VERSION ""

NS_ :

BS_:

BU_: APIM_CISM FCIMB RACM_RCIM DSP WCM DACMC HUD_ADV TRM_ITRM ACM GWM _delete APIM IPC GENERIC TSTR

BO_ 643 GWM_Send_Signals_18_HS3: 8 GWM
 SG_ StrtInGearMsgTxt_D_Rq_UB : 48|1@0+ (1,0) [0|1] "SED"  IPC
 SG_ StrtInGearMsgTxt_D_Rq : 59|4@0+ (1,0) [0|15] "SED"  IPC
 SG_ StabBarCnnct_D_Stat_UB : 49|1@0+ (1,0) [0|1] "SED"  APIM_CISM,APIM
 SG_ StabBarCnnct_D_Stat : 63|4@0+ (1,0) [0|15] "SED"  APIM_CISM,APIM
 SG_ FstChrgCmplt_T_Est : 33|10@0+ (1,0) [0|1023] "minute"  APIM_CISM,APIM,IPC
 SG_ GearPos_D_Trg_UB : 23|1@0+ (1,0) [0|1] "SED"  APIM_CISM,APIM
 SG_ GearPos_D_Trg : 11|4@0+ (1,0) [0|15] "SED"  APIM_CISM,APIM
 SG_ PwTgateStepMsgTxt_B_Rq : 13|1@0+ (1,0) [0|1] "SED"  IPC
 SG_ PwTgateStepMsgTxt_B_Rq_UB : 12|1@0+ (1,0) [0|1] "SED"  IPC
 SG_ PwTgateMsgTxt_B_Rq_UB : 14|1@0+ (1,0) [0|1] "SED"  IPC
 SG_ PwTgateLamp_B_Rq_UB : 0|1@0+ (1,0) [0|1] "SED"  IPC
 SG_ PwTgateMsgTxt_B_Rq : 15|1@0+ (1,0) [0|1] "SED"  IPC
 SG_ PwTgateLamp_B_Rq : 1|1@0+ (1,0) [0|1] "SED"  IPC
 SG_ PwRnngBoardSwtch_D_Stat_UB : 5|1@0+ (1,0) [0|1] "SED"  APIM_CISM,IPC,APIM
 SG_ PwRnngBoardT_D_Stat_UB : 2|1@0+ (1,0) [0|1] "SED"  APIM_CISM,IPC,APIM
 SG_ PwRnngBoardT_D_Stat : 4|2@0+ (1,0) [0|3] "SED"  APIM_CISM,IPC,APIM
 SG_ PwRnngBoardSwtch_D_Stat : 7|2@0+ (1,0) [0|3] "SED"  APIM_CISM,IPC,APIM
 SG_ OnePdlDrvLamp_B_Rq_UB : 52|1@0+ (1,0) [0|1] "SED"  IPC
 SG_ OnePdlDrv_D_Dsply_UB : 53|1@0+ (1,0) [0|1] "SED"  APIM_CISM,IPC,APIM
 SG_ OnePdlDrvLamp_B_Rq : 34|1@0+ (1,0) [0|1] "SED"  IPC
 SG_ OnePdlDrv_D_Dsply : 55|2@0+ (1,0) [0|3] "SED"  APIM_CISM,IPC,APIM
 SG_ SeatSlprPosMsgTxt_B_Rq_UB : 50|1@0+ (1,0) [0|1] "SED"  IPC
 SG_ SeatSlprPosMsgTxt_B_Rq : 51|1@0+ (1,0) [0|1] "SED"  IPC
 SG_ DrPrsntRearPsngr_D_Stat_UB : 36|1@0+ (1,0) [0|1] "SED"  IPC
 SG_ DrPrsntPsngr_D_Stat_UB : 37|1@0+ (1,0) [0|1] "SED"  IPC
 SG_ DrPsngrMsgTxt_B_Rq_UB : 38|1@0+ (1,0) [0|1] "SED"  IPC
 SG_ DrPsngrMsgTxt_B_Rq : 39|1@0+ (1,0) [0|1] "SED"  IPC
 SG_ DrPrsntRearPsngr_D_Stat : 25|2@0+ (1,0) [0|3] "SED"  IPC
 SG_ DrPrsntPsngr_D_Stat : 27|2@0+ (1,0) [0|3] "SED"  IPC
 SG_ DrPrsntRearDrv_D_Stat_UB : 30|1@0+ (1,0) [0|1] "SED"  IPC
 SG_ DrDrvMsgTxt_B_Rq_UB : 28|1@0+ (1,0) [0|1] "SED"  IPC
 SG_ DrPrsntDrv_D_Stat_UB : 31|1@0+ (1,0) [0|1] "SED"  IPC
 SG_ DrPrsntDrv_D_Stat : 19|2@0+ (1,0) [0|3] "SED"  IPC
 SG_ DrPrsntRearDrv_D_Stat : 17|2@0+ (1,0) [0|3] "SED"  IPC
 SG_ DrDrvMsgTxt_B_Rq : 29|1@0+ (1,0) [0|1] "SED"  IPC
 SG_ FstChrgCmplt_T_Est_UB : 35|1@0+ (1,0) [0|1] "SED"  APIM_CISM,APIM,IPC
 SG_ TrunkFrontOpen_D_Stat_UB : 20|1@0+ (1,0) [0|1] "SED"  APIM_CISM,APIM
 SG_ TrunkFrontOpen_D_Stat : 22|2@0+ (1,0) [0|3] "SED"  APIM_CISM,APIM

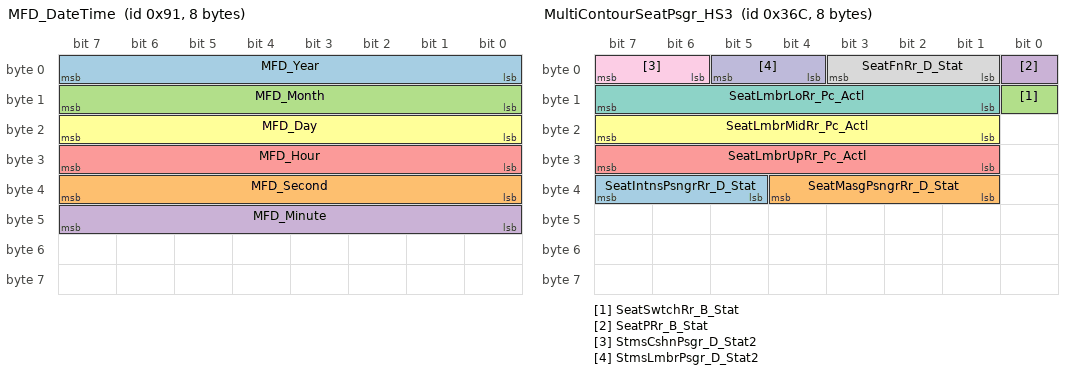
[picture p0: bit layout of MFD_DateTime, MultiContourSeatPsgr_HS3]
BO_ 145 MFD_DateTime: 8 APIM
 SG_ MFD_Year : 7|8@0+ (1,2000) [2000|2254] "year"  DSP,IPC,RACM_RCIM
 SG_ MFD_Second : 39|8@0+ (1,0) [0|59] "second"  DSP,IPC,RACM_RCIM
 SG_ MFD_Month : 15|8@0+ (1,0) [0|12] "month"  DSP,IPC,RACM_RCIM
 SG_ MFD_Minute : 47|8@0+ (1,0) [0|59] "minute"  DSP,IPC,RACM_RCIM
 SG_ MFD_Hour : 31|8@0+ (1,0) [0|23] "hour"  DSP,IPC,RACM_RCIM
 SG_ MFD_Day : 23|8@0+ (1,0) [0|31] "day"  DSP,IPC,RACM_RCIM

BO_ 607 RDRV_RSE_WORD_Rx: 8 RACM_RCIM
 SG_ RDRV_RSE_WORD_Rx : 7|64@0+ (1,0) [0|1.84467440737096E+019] "unitless"  GENERIC

BO_ 598 CONMP_RSE_WORD_Tx: 8 APIM
 SG_ CONMP_RSE_WORD_Tx : 7|64@0+ (1,0) [0|1.84467440737096E+019] "unitless"  RACM_RCIM

BO_ 606 CONMP_RSE_WORD_Rx: 8 RACM_RCIM
 SG_ CONMP_RSE_WORD_Rx : 7|64@0+ (1,0) [0|1.84467440737096E+019] "unitless"  APIM,APIM_CISM

BO_ 597 AUDIO_RSE_WORD_Tx: 8 ACM
 SG_ AUDIO_RSE_WORD_Tx : 7|64@0+ (1,0) [0|1.84467440737096E+019] "unitless"  RACM_RCIM

BO_ 605 AUDIO_RSE_WORD_Rx: 8 RACM_RCIM
 SG_ AUDIO_RSE_WORD_Rx : 7|64@0+ (1,0) [0|1.84467440737096E+019] "unitless"  APIM_CISM,ACM

BO_ 876 MultiContourSeatPsgr_HS3: 8 GWM
 SG_ SeatIntnsPsngrRr_D_Stat : 39|3@0+ (1,0) [0|7] "SED" Vector__XXX
 SG_ SeatMasgPsngrRr_D_Stat : 36|4@0+ (1,0) [0|15] "SED" Vector__XXX
 SG_ SeatSwtchRr_B_Stat : 8|1@0+ (1,0) [0|1] "SED"  RACM_RCIM
 SG_ SeatPRr_B_Stat : 0|1@0+ (1,0) [0|1] "SED"  RACM_RCIM
 SG_ SeatLmbrUpRr_Pc_Actl : 31|7@0+ (1,0) [0|127] "Percent"  RACM_RCIM
 SG_ SeatLmbrMidRr_Pc_Actl : 23|7@0+ (1,0) [0|127] "Percent"  RACM_RCIM
 SG_ SeatLmbrLoRr_Pc_Actl : 15|7@0+ (1,0) [0|127] "Percent"  RACM_RCIM
 SG_ SeatFnRr_D_Stat : 3|3@0+ (1,0) [0|7] "SED"  RACM_RCIM
 SG_ StmsCshnPsgr_D_Stat2 : 7|2@0+ (1,0) [0|3] "SED"  RACM_RCIM
 SG_ StmsLmbrPsgr_D_Stat2 : 5|2@0+ (1,0) [0|3] "SED"  RACM_RCIM

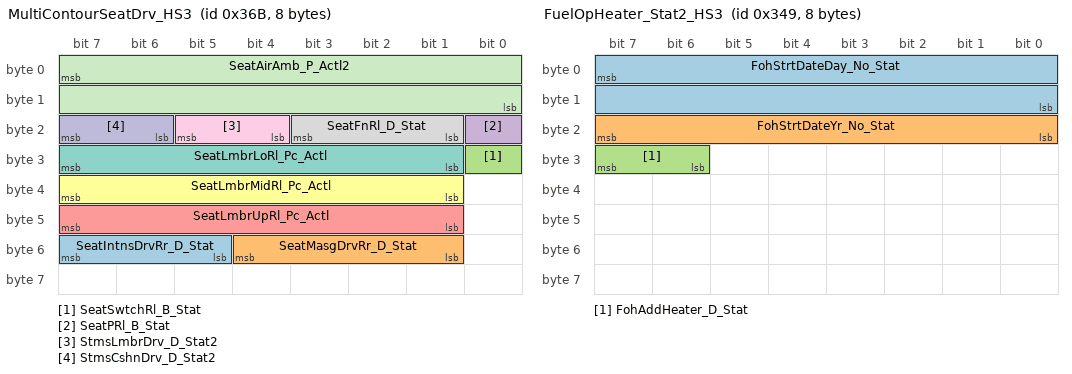
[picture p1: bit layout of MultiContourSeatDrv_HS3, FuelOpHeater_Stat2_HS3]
BO_ 875 MultiContourSeatDrv_HS3: 8 GWM
 SG_ SeatIntnsDrvRr_D_Stat : 55|3@0+ (1,0) [0|7] "SED" Vector__XXX
 SG_ SeatMasgDrvRr_D_Stat : 52|4@0+ (1,0) [0|15] "SED" Vector__XXX
 SG_ SeatSwtchRl_B_Stat : 24|1@0+ (1,0) [0|1] "SED"  RACM_RCIM
 SG_ SeatPRl_B_Stat : 16|1@0+ (1,0) [0|1] "SED"  RACM_RCIM
 SG_ SeatLmbrUpRl_Pc_Actl : 47|7@0+ (1,0) [0|127] "Percent"  RACM_RCIM
 SG_ SeatLmbrMidRl_Pc_Actl : 39|7@0+ (1,0) [0|127] "Percent"  RACM_RCIM
 SG_ SeatLmbrLoRl_Pc_Actl : 31|7@0+ (1,0) [0|127] "Percent"  RACM_RCIM
 SG_ SeatFnRl_D_Stat : 19|3@0+ (1,0) [0|7] "SED"  RACM_RCIM
 SG_ StmsLmbrDrv_D_Stat2 : 21|2@0+ (1,0) [0|3] "SED"  RACM_RCIM
 SG_ StmsCshnDrv_D_Stat2 : 23|2@0+ (1,0) [0|3] "SED"  RACM_RCIM
 SG_ SeatAirAmb_P_Actl2 : 7|16@0+ (0.01,0) [0|655.35] "kilopascal"  RACM_RCIM

BO_ 841 FuelOpHeater_Stat2_HS3: 8 GWM
 SG_ FohStrtDateDay_No_Stat : 7|16@0+ (1,0) [0|65535] "julian day"  IPC
 SG_ FohStrtDateYr_No_Stat : 23|8@0+ (1,2000) [2000|2255] "year"  IPC
 SG_ FohAddHeater_D_Stat : 31|2@0+ (1,0) [0|3] "SED"  IPC

BO_ 545 DSPAMP_Send_Signals_1: 8 DSP
 SG_ SpkrDgtlRight_D_Stat : 47|2@0+ (1,0) [0|3] "SED" Vector__XXX
 SG_ SpkrDgtlLeft_D_Stat : 45|2@0+ (1,0) [0|3] "SED" Vector__XXX
 SG_ SpkrDgtlCntr_D_Stat : 43|2@0+ (1,0) [0|3] "SED"  APIM_CISM,ACM
 SG_ SurndSndUpmix2_D_Stat : 34|3@0+ (1,0) [0|7] "SED"  APIM_CISM,APIM
 SG_ DSP_Bezel_Diag_St : 23|4@0+ (1,0) [0|15] "SED"  APIM_CISM,APIM
 SG_ SndImmrsnLvl_D_Stat : 55|8@0+ (1,0) [0|255] "SED"  APIM_CISM,APIM
 SG_ DSP_Sur_Sound_st : 7|2@0+ (1,0) [0|3] "SED"  APIM_CISM,APIM
 SG_ DSP_MyKeyVolLimitUp_St : 19|2@0+ (1,0) [0|3] "SED"  APIM_CISM,APIM
 SG_ DSP_MyKeyVolLim_St : 2|2@0+ (1,0) [0|3] "SED"  APIM_CISM,APIM
 SG_ DSP_BeltminderAudio_St : 4|2@0+ (1,0) [0|3] "SED"  APIM_CISM,APIM
 SG_ DSP_Audio_Volume_Up_St : 9|1@0+ (1,0) [0|1] "SED"  IPC,HUD_ADV,APIM_CISM,GWM,APIM,RACM_RCIM
 SG_ DSP_Audio_Vol_Level_St : 15|5@0+ (1,0) [0|31] "percent"  IPC,WCM,HUD_ADV,APIM_CISM,ACM,APIM,RACM_RCIM
 SG_ AutoConfigOcc_Rear : 28|1@0+ (1,0) [0|1] "SED"  APIM,APIM_CISM
 SG_ AutoConfigOcc_Front : 30|1@0+ (1,0) [0|1] "SED"  APIM,APIM_CISM
 SG_ AutoConfigOcc_Driver : 31|1@0+ (1,0) [0|1] "SED"  APIM,APIM_CISM
 SG_ AutoConfigOcc_AllSeats : 29|1@0+ (1,0) [0|1] "SED"  APIM,APIM_CISM
 SG_ AudioOccMde_D_Stat : 39|5@0+ (1,0) [0|31] "SED"  APIM,APIM_CISM

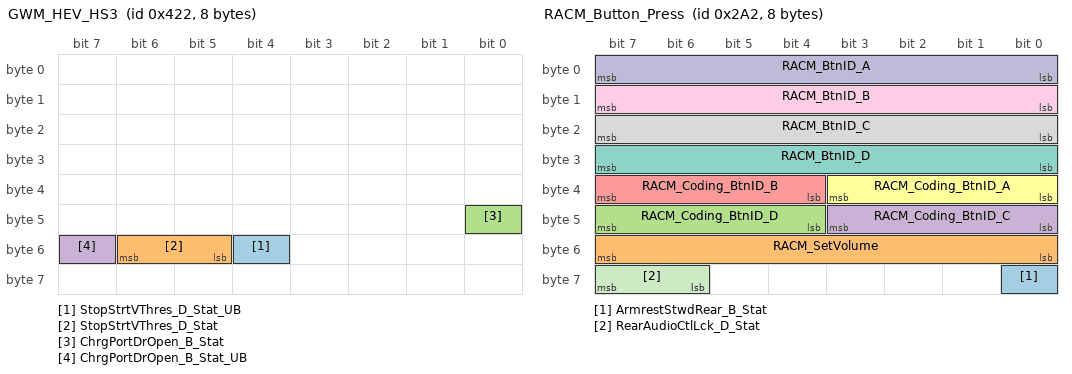
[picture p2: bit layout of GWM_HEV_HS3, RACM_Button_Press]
BO_ 1058 GWM_HEV_HS3: 8 GWM
 SG_ StopStrtVThres_D_Stat_UB : 52|1@0+ (1,0) [0|1] "SED"  APIM,APIM_CISM,IPC
 SG_ StopStrtVThres_D_Stat : 54|2@0+ (1,0) [0|3] "SED"  APIM,APIM_CISM,IPC
 SG_ ChrgPortDrOpen_B_Stat : 40|1@0+ (1,0) [0|1] "SED"  IPC
 SG_ ChrgPortDrOpen_B_Stat_UB : 55|1@0+ (1,0) [0|1] "SED"  IPC

BO_ 633 GWM_Send_Signals_6_HS3: 8 GWM
 SG_ RearDiffLckMsg2_D_Rq_UB : 63|1@0+ (1,0) [0|1] "SED"  IPC
 SG_ RearDiffLckMsg2_D_Rq : 21|4@0+ (1,0) [0|15] "SED"  IPC
 SG_ PwStepMsgTxt_D_Rq_UB : 5|1@0+ (1,0) [0|1] "SED"  IPC
 SG_ PwStepMsgTxt_D_Rq : 7|2@0+ (1,0) [0|3] "SED"  IPC
 SG_ RearDiffLck_D_RqDrv : 39|2@0+ (1,0) [0|3] "SED"  IPC
 SG_ AwdMde_D_RqDrv : 37|3@0+ (1,0) [0|7] "SED"  IPC
 SG_ RearDiffLck_D_RqDrv_UB : 34|1@0+ (1,0) [0|1] "SED"  IPC
 SG_ TsrRegionTxt_D_Stat_UB : 10|1@0+ (1,0) [0|1] "SED"  HUD_ADV,IPC
 SG_ AwdMde_D_RqDrv_UB : 53|1@0+ (1,0) [0|1] "SED"  IPC
 SG_ TsrRegionTxt_D_Stat : 15|5@0+ (1,0) [0|31] "SED"  HUD_ADV,IPC
 SG_ GsmGearMsgTxt_D_Rq_UB : 57|1@0+ (1,0) [0|1] "SED"  IPC
 SG_ GsmGearMsgTxt_D_Rq : 59|2@0+ (1,0) [0|3] "SED"  IPC
 SG_ RearDiffLckLamp_D_Rq2_UB : 54|1@0+ (1,0) [0|1] "SED"  IPC
 SG_ RearDiffLckLamp_D_Rq2 : 23|2@0+ (1,0) [0|3] "SED"  IPC
 SG_ DasAlrtInfo_D_Dsply_UB : 60|1@0+ (1,0) [0|1] "SED"  APIM_CISM,APIM
 SG_ DasAlrtInfo_D_Dsply : 62|2@0+ (1,0) [0|3] "SED"  APIM_CISM,APIM
 SG_ Shed_Feature_Group_ID_UB : 56|1@0+ (1,0) [0|1] "SED"  TRM_ITRM
 SG_ Shed_Feature_Group_ID : 4|5@0+ (1,0) [0|31] "SED"  TRM_ITRM

BO_ 936 ParkAid_Data_HS3: 8 GWM
 SG_ ApaButtnPrssd_B_Stat : 58|1@0+ (1,0) [0|1] "SED"  GENERIC
 SG_ ApaSys_D_Stat : 61|3@0+ (1,0) [0|7] "SED"  APIM_CISM,IPC,ACM,APIM
 SG_ ApaSteWhl_D_RqDrv : 63|2@0+ (1,0) [0|3] "SED"  APIM_CISM,ACM,APIM
 SG_ ApaSteScanMde_D_Stat : 49|2@0+ (1,0) [0|3] "SED"  APIM_CISM,ACM,APIM
 SG_ ApaSelSapp_D_Stat : 51|2@0+ (1,0) [0|3] "SED"  APIM_CISM,ACM,APIM
 SG_ ApaSelPpa_D_Stat : 53|2@0+ (1,0) [0|3] "SED"  APIM_CISM,ACM,APIM
 SG_ ApaSelPoa_D_Stat : 55|2@0+ (1,0) [0|3] "SED"  APIM_CISM,ACM,APIM
 SG_ ApaScan_D_Stat : 41|2@0+ (1,0) [0|3] "SED"  APIM_CISM,ACM,APIM
 SG_ ApaLongCtl_D_RqDrv : 44|3@0+ (1,0) [0|7] "SED"  APIM_CISM,ACM,APIM
 SG_ ApaGearShif_D_RqDrv : 47|3@0+ (1,0) [0|7] "SED"  APIM_CISM,ACM,APIM
 SG_ ApaActvSide2_D_Stat : 33|2@0+ (1,0) [0|3] "SED"  APIM_CISM,ACM,APIM
 SG_ ApaAcsy_D_RqDrv : 36|3@0+ (1,0) [0|7] "SED"  APIM_CISM,ACM,APIM
 SG_ ApaChime_D_Rq : 39|3@0+ (1,0) [0|7] "SED"  IPC
 SG_ EPASExtAngleStatReq : 23|1@0+ (1,0) [0|1] "SED" Vector__XXX
 SG_ ExtSteeringAngleReq2 : 22|15@0+ (0.1,-1000) [-1000|2276.5] "Degrees" Vector__XXX
 SG_ ApaTrgtDist_D_Stat : 11|4@0+ (1,0) [0|15] "SED"  APIM_CISM,APIM,ACM
 SG_ ApaMsgTxt_D_Rq : 15|4@0+ (1,0) [0|15] "SED"  APIM_CISM,APIM,ACM

BO_ 674 RACM_Button_Press: 8 RACM_RCIM
 SG_ ArmrestStwdRear_B_Stat : 56|1@0+ (1,0) [0|1] "SED"  GWM
 SG_ RACM_SetVolume : 55|8@0+ (1,-30) [-30|30] "unitless"  GWM,APIM_CISM,APIM,GENERIC
 SG_ RACM_Coding_BtnID_D : 47|4@0+ (1,0) [0|15] "SED"  GWM,APIM_CISM,APIM,GENERIC
 SG_ RACM_Coding_BtnID_C : 43|4@0+ (1,0) [0|15] "SED"  GWM,APIM_CISM,APIM,GENERIC
 SG_ RACM_Coding_BtnID_B : 39|4@0+ (1,0) [0|15] "SED"  GWM,APIM_CISM,APIM,GENERIC
 SG_ RACM_Coding_BtnID_A : 35|4@0+ (1,0) [0|15] "SED"  GWM,APIM_CISM,APIM,GENERIC
 SG_ RACM_BtnID_D : 31|8@0+ (1,0) [0|255] "unitless"  GWM,APIM_CISM,APIM,GENERIC
 SG_ RACM_BtnID_C : 23|8@0+ (1,0) [0|255] "unitless"  GWM,APIM_CISM,APIM,GENERIC
 SG_ RACM_BtnID_B : 15|8@0+ (1,0) [0|255] "unitless"  GWM,APIM_CISM,APIM,GENERIC
 SG_ RACM_BtnID_A : 7|8@0+ (1,0) [0|255] "unitless"  GWM,APIM_CISM,APIM,GENERIC
 SG_ RearAudioCtlLck_D_Stat : 63|2@0+ (1,0) [0|3] "SED"  GWM,APIM_CISM,APIM,FCIMB

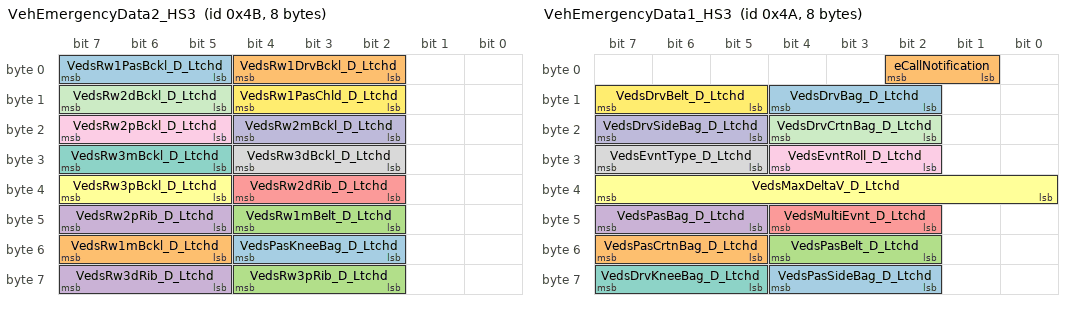
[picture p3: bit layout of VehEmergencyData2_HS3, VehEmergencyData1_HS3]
BO_ 75 VehEmergencyData2_HS3: 8 GWM
 SG_ VedsPasKneeBag_D_Ltchd : 52|3@0+ (1,0) [0|7] "SED"  APIM_CISM,APIM,ACM
 SG_ VedsRw1mBckl_D_Ltchd : 55|3@0+ (1,0) [0|7] "SED"  APIM_CISM,APIM
 SG_ VedsRw1mBelt_D_Ltchd : 44|3@0+ (1,0) [0|7] "SED"  APIM_CISM,APIM
 SG_ VedsRw2pRib_D_Ltchd : 47|3@0+ (1,0) [0|7] "SED"  APIM_CISM,APIM
 SG_ VedsRw2dRib_D_Ltchd : 36|3@0+ (1,0) [0|7] "SED"  APIM_CISM,APIM
 SG_ VedsRw3pBckl_D_Ltchd : 39|3@0+ (1,0) [0|7] "SED"  APIM_CISM,APIM
 SG_ VedsRw3mBckl_D_Ltchd : 31|3@0+ (1,0) [0|7] "SED"  APIM_CISM,APIM
 SG_ VedsRw3dBckl_D_Ltchd : 28|3@0+ (1,0) [0|7] "SED"  APIM_CISM,APIM
 SG_ VedsRw2pBckl_D_Ltchd : 23|3@0+ (1,0) [0|7] "SED"  APIM_CISM,APIM
 SG_ VedsRw2mBckl_D_Ltchd : 20|3@0+ (1,0) [0|7] "SED"  APIM_CISM,APIM
 SG_ VedsRw2dBckl_D_Ltchd : 15|3@0+ (1,0) [0|7] "SED"  APIM_CISM,APIM
 SG_ VedsRw1PasChld_D_Ltchd : 12|3@0+ (1,0) [0|7] "SED"  APIM_CISM,APIM
 SG_ VedsRw1PasBckl_D_Ltchd : 7|3@0+ (1,0) [0|7] "SED"  APIM_CISM,APIM
 SG_ VedsRw1DrvBckl_D_Ltchd : 4|3@0+ (1,0) [0|7] "SED"  APIM_CISM,APIM
 SG_ VedsRw3pRib_D_Ltchd : 60|3@0+ (1,0) [0|7] "SED"  APIM_CISM,APIM
 SG_ VedsRw3dRib_D_Ltchd : 63|3@0+ (1,0) [0|7] "SED"  APIM_CISM,APIM

BO_ 74 VehEmergencyData1_HS3: 8 GWM
 SG_ VedsPasSideBag_D_Ltchd : 60|3@0+ (1,0) [0|7] "SED"  APIM_CISM,APIM
 SG_ VedsPasCrtnBag_D_Ltchd : 55|3@0+ (1,0) [0|7] "SED"  APIM_CISM,APIM
 SG_ VedsPasBelt_D_Ltchd : 52|3@0+ (1,0) [0|7] "SED"  APIM_CISM,APIM
 SG_ VedsPasBag_D_Ltchd : 47|3@0+ (1,0) [0|7] "SED"  APIM_CISM,APIM
 SG_ VedsMultiEvnt_D_Ltchd : 44|3@0+ (1,0) [0|7] "SED"  APIM_CISM,APIM
 SG_ VedsMaxDeltaV_D_Ltchd : 39|8@0+ (1,0) [0|255] "kph"  APIM_CISM,APIM
 SG_ VedsDrvKneeBag_D_Ltchd : 63|3@0+ (1,0) [0|7] "SED"  APIM_CISM,APIM
 SG_ VedsEvntType_D_Ltchd : 31|3@0+ (1,0) [0|7] "SED"  APIM_CISM,APIM
 SG_ VedsEvntRoll_D_Ltchd : 28|3@0+ (1,0) [0|7] "SED"  APIM_CISM,APIM
 SG_ VedsDrvSideBag_D_Ltchd : 23|3@0+ (1,0) [0|7] "SED"  APIM_CISM,APIM
 SG_ VedsDrvCrtnBag_D_Ltchd : 20|3@0+ (1,0) [0|7] "SED"  APIM_CISM,APIM
 SG_ VedsDrvBelt_D_Ltchd : 15|3@0+ (1,0) [0|7] "SED"  APIM,APIM_CISM
 SG_ VedsDrvBag_D_Ltchd : 12|3@0+ (1,0) [0|7] "SED"  APIM,APIM_CISM,ACM
 SG_ eCallNotification : 2|2@0+ (1,0) [0|3] "SED"  APIM,APIM_CISM

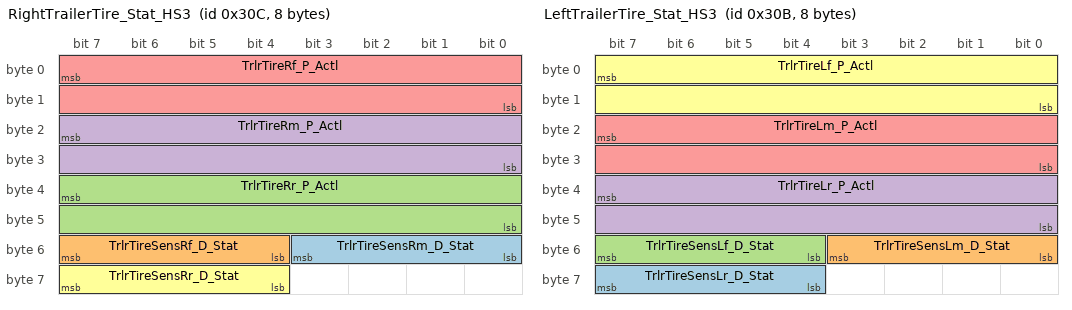
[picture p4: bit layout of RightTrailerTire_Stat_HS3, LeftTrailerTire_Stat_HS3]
BO_ 780 RightTrailerTire_Stat_HS3: 8 GWM
 SG_ TrlrTireSensRm_D_Stat : 51|4@0+ (1,0) [0|15] "SED"  IPC
 SG_ TrlrTireSensRf_D_Stat : 55|4@0+ (1,0) [0|15] "SED"  IPC
 SG_ TrlrTireRr_P_Actl : 39|16@0+ (1,0) [0|65533] "kilopascal"  IPC
 SG_ TrlrTireRm_P_Actl : 23|16@0+ (1,0) [0|65533] "kilopascal"  IPC
 SG_ TrlrTireRf_P_Actl : 7|16@0+ (1,0) [0|65533] "kilopascal"  IPC
 SG_ TrlrTireSensRr_D_Stat : 63|4@0+ (1,0) [0|15] "SED"  IPC

BO_ 779 LeftTrailerTire_Stat_HS3: 8 GWM
 SG_ TrlrTireSensLr_D_Stat : 63|4@0+ (1,0) [0|15] "SED"  IPC
 SG_ TrlrTireSensLm_D_Stat : 51|4@0+ (1,0) [0|15] "SED"  IPC
 SG_ TrlrTireSensLf_D_Stat : 55|4@0+ (1,0) [0|15] "SED"  IPC
 SG_ TrlrTireLr_P_Actl : 39|16@0+ (1,0) [0|65533] "kilopascal"  IPC
 SG_ TrlrTireLm_P_Actl : 23|16@0+ (1,0) [0|65533] "kilopascal"  IPC
 SG_ TrlrTireLf_P_Actl : 7|16@0+ (1,0) [0|65533] "kilopascal"  IPC

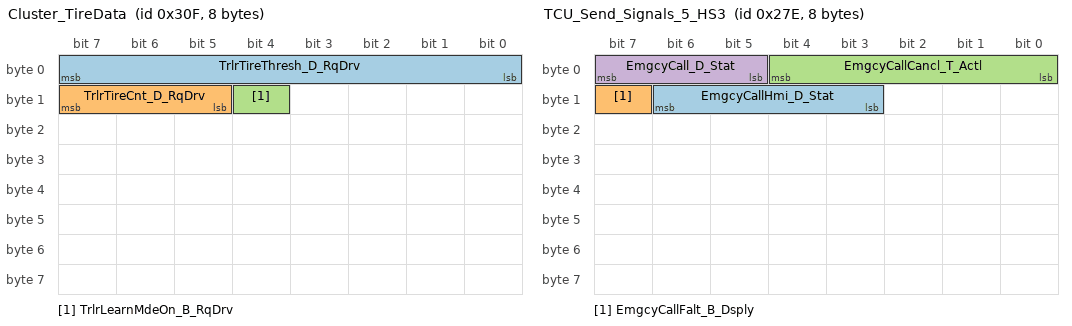
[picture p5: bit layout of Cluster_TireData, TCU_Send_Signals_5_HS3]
BO_ 783 Cluster_TireData: 8 IPC
 SG_ TrlrTireThresh_D_RqDrv : 7|8@0+ (1,0) [0|255] "unitless"  GWM
 SG_ TrlrTireCnt_D_RqDrv : 15|3@0+ (1,0) [0|6] "SED"  GWM
 SG_ TrlrLearnMdeOn_B_RqDrv : 12|1@0+ (1,0) [0|1] "SED"  GWM

BO_ 638 TCU_Send_Signals_5_HS3: 8 GWM
 SG_ EmgcyCallHmi_D_Stat : 14|4@0+ (1,0) [0|15] "SED"  APIM_CISM,APIM
 SG_ EmgcyCallFalt_B_Dsply : 15|1@0+ (1,0) [0|1] "SED"  IPC
 SG_ EmgcyCallCancl_T_Actl : 4|5@0+ (1,0) [0|31] "second"  APIM_CISM,APIM
 SG_ EmgcyCall_D_Stat : 7|3@0+ (1,0) [0|7] "SED"  APIM_CISM,APIM

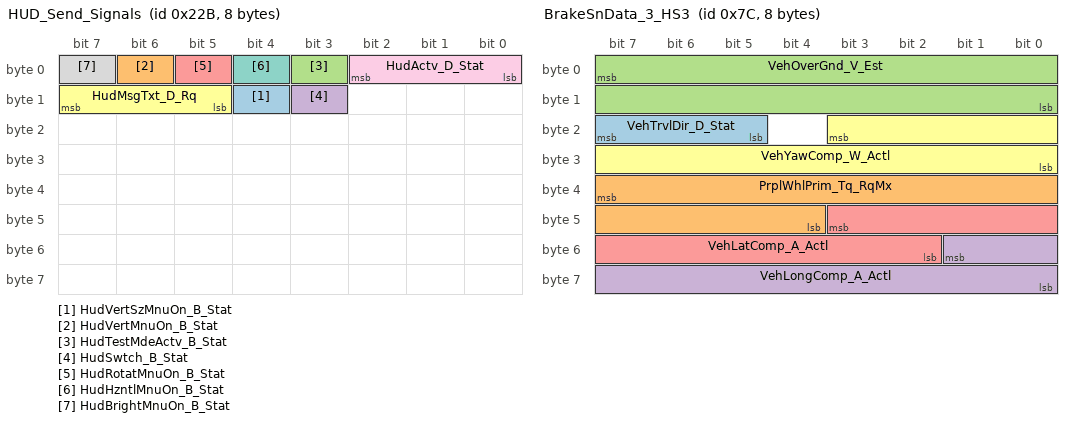
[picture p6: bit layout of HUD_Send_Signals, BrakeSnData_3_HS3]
BO_ 555 HUD_Send_Signals: 8 HUD_ADV
 SG_ HudVertSzMnuOn_B_Stat : 12|1@0+ (1,0) [0|1] "SED"  IPC
 SG_ HudVertMnuOn_B_Stat : 6|1@0+ (1,0) [0|1] "SED"  IPC
 SG_ HudTestMdeActv_B_Stat : 3|1@0+ (1,0) [0|1] "SED"  IPC
 SG_ HudSwtch_B_Stat : 11|1@0+ (1,0) [0|1] "SED"  IPC
 SG_ HudRotatMnuOn_B_Stat : 5|1@0+ (1,0) [0|1] "SED"  IPC
 SG_ HudMsgTxt_D_Rq : 15|3@0+ (1,0) [0|7] "SED"  IPC
 SG_ HudHzntlMnuOn_B_Stat : 4|1@0+ (1,0) [0|1] "SED"  IPC
 SG_ HudBrightMnuOn_B_Stat : 7|1@0+ (1,0) [0|1] "SED"  IPC
 SG_ HudActv_D_Stat : 2|3@0+ (1,0) [0|7] "SED"  IPC

BO_ 124 BrakeSnData_3_HS3: 8 GWM
 SG_ VehTrvlDir_D_Stat : 23|3@0+ (1,0) [0|7] "SED"  GENERIC
 SG_ PrplWhlPrim_Tq_RqMx : 39|12@0+ (8,0) [0|32760] "Nm"  GENERIC
 SG_ VehOverGnd_V_Est : 7|16@0+ (0.01,0) [0|655.33] "kph"  APIM_CISM,APIM,IPC
 SG_ VehLongComp_A_Actl : 49|10@0+ (0.035,-17.9) [-17.9|17.835] "m/s^2"  APIM_CISM,APIM,IPC
 SG_ VehLatComp_A_Actl : 43|10@0+ (0.035,-17.9) [-17.9|17.835] "m/s^2"  APIM_CISM,APIM,IPC
 SG_ VehYawComp_W_Actl : 19|12@0+ (0.03663,-75) [-75|74.92659] "deg/s"  APIM_CISM,IPC,APIM

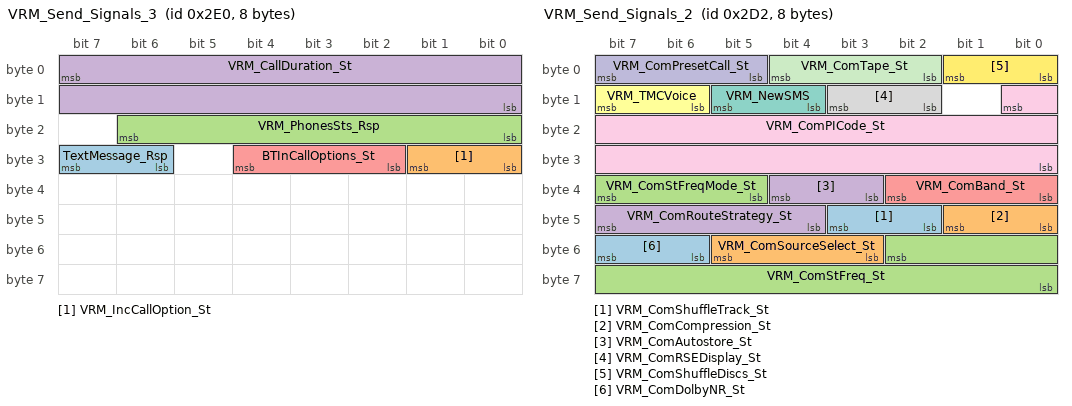
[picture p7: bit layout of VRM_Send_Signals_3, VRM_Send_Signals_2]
BO_ 736 VRM_Send_Signals_3: 8 APIM
 SG_ TextMessage_Rsp : 31|2@0+ (1,0) [0|3] "SED"  HUD_ADV,IPC
 SG_ VRM_IncCallOption_St : 25|2@0+ (1,0) [0|3] "SED"  GENERIC
 SG_ VRM_PhonesSts_Rsp : 22|7@0+ (1,0) [0|127] "unitless"  GENERIC
 SG_ VRM_CallDuration_St : 7|16@0+ (1,0) [0|65534] "second"  IPC
 SG_ BTInCallOptions_St : 28|3@0+ (1,0) [0|7] "SED"  HUD_ADV,IPC

BO_ 722 VRM_Send_Signals_2: 8 APIM
 SG_ VRM_ComShuffleTrack_St : 43|2@0+ (1,0) [0|3] "SED"  GENERIC
 SG_ VRM_ComCompression_St : 41|2@0+ (1,0) [0|3] "SED"  GENERIC
 SG_ VRM_ComStFreqMode_St : 39|3@0+ (1,0) [0|7] "SED"  GENERIC
 SG_ VRM_ComAutostore_St : 36|2@0+ (1,0) [0|3] "SED"  GENERIC
 SG_ VRM_ComBand_St : 34|3@0+ (1,0) [0|7] "SED"  GENERIC
 SG_ VRM_TMCVoice : 15|2@0+ (1,0) [0|3] "SED"  GENERIC
 SG_ VRM_NewSMS : 13|2@0+ (1,0) [0|3] "SED"  HUD_ADV,IPC
 SG_ VRM_ComRSEDisplay_St : 11|2@0+ (1,0) [0|3] "SED"  GENERIC
 SG_ VRM_ComPICode_St : 8|17@0+ (1,0) [0|65535] "unitless"  GENERIC
 SG_ VRM_ComPresetCall_St : 7|3@0+ (1,0) [0|7] "SED"  GENERIC
 SG_ VRM_ComTape_St : 4|3@0+ (1,0) [0|7] "SED"  GENERIC
 SG_ VRM_ComShuffleDiscs_St : 1|2@0+ (1,0) [0|3] "SED"  GENERIC
 SG_ VRM_ComDolbyNR_St : 55|2@0+ (1,0) [0|3] "SED"  GENERIC
 SG_ VRM_ComSourceSelect_St : 53|3@0+ (1,0) [0|7] "SED"  GENERIC
 SG_ VRM_ComStFreq_St : 50|11@0+ (1,0) [0|1557] "unitless"  GENERIC
 SG_ VRM_ComRouteStrategy_St : 47|4@0+ (1,0) [0|15] "SED"  GENERIC

BO_ 721 VRM_Send_Signals_1: 8 APIM
 SG_ VRM_BTDefaultPhone_St : 63|4@0+ (1,0) [0|15] "SED"  IPC
 SG_ VRM_DetourUnit_st : 59|2@0+ (1,0) [0|3] "SED"  GENERIC
 SG_ VRM_Zoom_Option_St : 57|2@0+ (1,0) [0|3] "SED"  GENERIC
 SG_ VRM_ComBTDTMFTone_St : 55|4@0+ (1,0) [0|15] "SED"  GENERIC
 SG_ VRM_SuggestedRoute_St : 51|2@0+ (1,0) [0|3] "SED"  GENERIC
 SG_ VRM_ComDelWaypoint_St : 49|2@0+ (1,0) [0|3] "SED"  GENERIC
 SG_ VRM_ComSelectDisc_St : 47|3@0+ (1,0) [0|7] "SED"  GENERIC
 SG_ VRM_ComTelService_St : 44|3@0+ (1,0) [0|7] "SED"  GENERIC
 SG_ VRM_ComDestHome_St : 41|2@0+ (1,0) [0|3] "SED"  GENERIC
 SG_ VRM_ComSelectTrack_St : 39|7@0+ (1,0) [0|100] "unitless"  GENERIC
 SG_ VRM_ComShowNavInfo_St : 31|3@0+ (1,0) [0|7] "SED"  GENERIC
 SG_ VRM_VoiceRecStatus_St : 28|3@0+ (1,0) [0|7] "SED"  IPC
 SG_ VRM_ComSelTrackSource_St : 25|2@0+ (1,0) [0|3] "SED"  GENERIC
 SG_ VRM_ComDetour_St : 23|4@0+ (1,0) [0|15] "SED"  GENERIC
 SG_ VRM_ComDisplay_St : 19|3@0+ (1,0) [0|7] "SED"  GENERIC
 SG_ VRM_ComDynamicGuidande_St : 15|2@0+ (1,0) [0|3] "SED"  GENERIC
 SG_ VRM_ComZoom_St : 12|5@0+ (1,0) [0|31] "SED"  GENERIC
 SG_ VRM_ComCallControl_St : 7|3@0+ (1,0) [0|7] "SED"  GENERIC
 SG_ VRM_ComGuidance_St : 4|3@0+ (1,0) [0|7] "SED"  GENERIC
 SG_ VRM_ComTrafficInfDsp_St : 1|2@0+ (1,0) [0|3] "SED"  GENERIC

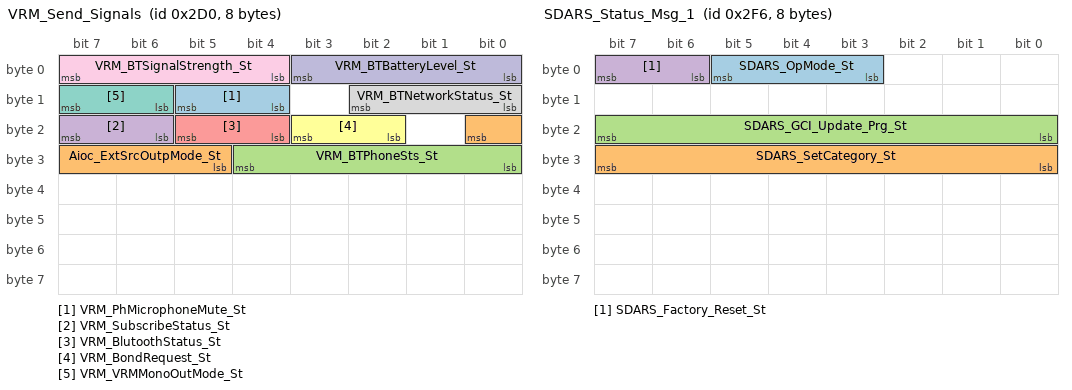
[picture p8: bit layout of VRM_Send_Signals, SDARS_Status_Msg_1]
BO_ 720 VRM_Send_Signals: 8 APIM
 SG_ VRM_PhMicrophoneMute_St : 13|2@0+ (1,0) [0|3] "SED"  IPC
 SG_ Aioc_ExtSrcOutpMode_St : 16|4@0+ (1,0) [0|15] "SED"  GENERIC
 SG_ VRM_BTPhoneSts_St : 28|5@0+ (1,0) [0|31] "SED"  RACM_RCIM,GWM,HUD_ADV,IPC
 SG_ VRM_SubscribeStatus_St : 23|2@0+ (1,0) [0|3] "SED"  GENERIC
 SG_ VRM_BlutoothStatus_St : 21|2@0+ (1,0) [0|3] "SED"  IPC
 SG_ VRM_BondRequest_St : 19|2@0+ (1,0) [0|3] "SED"  GENERIC
 SG_ VRM_VRMMonoOutMode_St : 15|2@0+ (1,0) [0|3] "SED"  GENERIC
 SG_ VRM_BTNetworkStatus_St : 10|3@0+ (1,0) [0|7] "unitless"  IPC
 SG_ VRM_BTSignalStrength_St : 7|4@0+ (1,0) [0|15] "unitless"  IPC
 SG_ VRM_BTBatteryLevel_St : 3|4@0+ (1,0) [0|15] "unitless"  IPC

BO_ 470 VRM_Response_Signals: 8 APIM
 SG_ VRM_BTIncomingCall_Rsp : 47|2@0+ (1,0) [0|3] "SED"  HUD_ADV,IPC
 SG_ VRM_BTEndTelService_Rsp : 37|2@0+ (1,0) [0|3] "SED"  HUD_ADV,IPC

BO_ 1978 TesterPhysicalResHUD_ADV: 8 HUD_ADV
 SG_ TesterPhysicalResHUD_ADV : 7|64@0+ (1,0) [0|1.84467E+019] "unitless"  TSTR

BO_ 1970 TesterPhysicalReqHUD_ADV: 8 TSTR
 SG_ TesterPhysicalReqHUD_ADV : 7|64@0+ (1,0) [0|1.84467E+019] "unitless"  HUD_ADV

BO_ 758 SDARS_Status_Msg_1: 8 ACM
 SG_ SDARS_OpMode_St : 5|3@0+ (1,0) [0|7] "SED"  APIM,IPC
 SG_ SDARS_SetCategory_St : 31|8@0+ (1,0) [0|255] "unitless"  APIM,IPC
 SG_ SDARS_GCI_Update_Prg_St : 23|8@0+ (1,0) [0|255] "unitless"  RACM_RCIM,APIM,IPC
 SG_ SDARS_Factory_Reset_St : 7|2@0+ (1,0) [0|3] "SED"  APIM,IPC

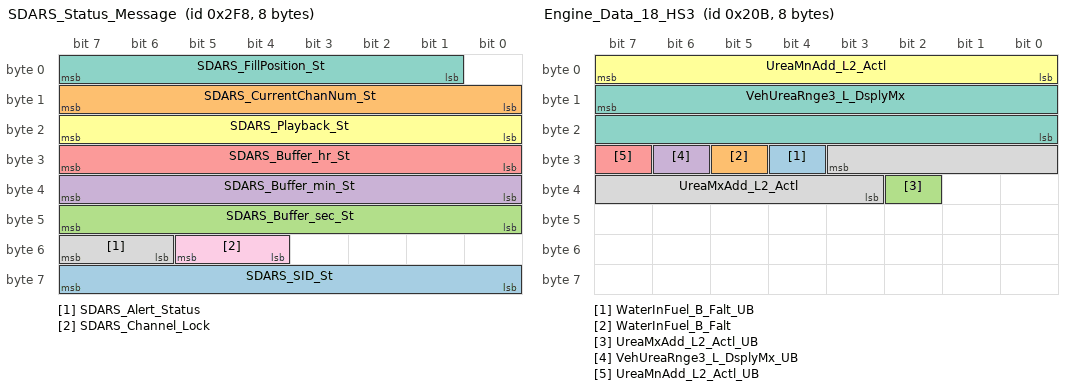
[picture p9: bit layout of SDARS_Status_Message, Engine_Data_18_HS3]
BO_ 760 SDARS_Status_Message: 8 ACM
 SG_ SDARS_SID_St : 63|8@0+ (1,0) [0|255] "unitless"  RACM_RCIM,APIM
 SG_ SDARS_CurrentChanNum_St : 15|8@0+ (1,0) [0|255] "unitless"  HUD_ADV,APIM,RACM_RCIM,IPC
 SG_ SDARS_Buffer_sec_St : 47|8@0+ (1,0) [0|255] "unitless"  APIM,IPC
 SG_ SDARS_Buffer_min_St : 39|8@0+ (1,0) [0|255] "unitless"  APIM,IPC
 SG_ SDARS_Buffer_hr_St : 31|8@0+ (1,0) [0|255] "unitless"  APIM,IPC
 SG_ SDARS_Playback_St : 23|8@0+ (1,0) [0|255] "unitless"  APIM,IPC
 SG_ SDARS_FillPosition_St : 7|7@0+ (1,0) [0|127] "unitless"  APIM,IPC
 SG_ SDARS_Alert_Status : 55|2@0+ (1,0) [0|3] "SED"  APIM,IPC
 SG_ SDARS_Channel_Lock : 53|2@0+ (1,0) [0|3] "SED"  HUD_ADV,RACM_RCIM,APIM,IPC

BO_ 705 SDARS_RDISP_WORD_Tx: 8 ACM
 SG_ SDARS_RDISP_WORD_Tx : 7|64@0+ (1,0) [0|1.84467440737096E+019] "unitless"  APIM

BO_ 692 AUDIO_RDISP_WORD_Tx: 8 ACM
 SG_ AUDIO_RDISP_WORD_Tx : 7|64@0+ (1,0) [0|1.84467440737096E+019] "unitless"  APIM

BO_ 1837 TesterPhysicalResWCM: 8 WCM
 SG_ TesterPhysicalResWCM : 7|64@0+ (1,0) [0|1.84467E+019] "unitless"  TSTR

BO_ 523 Engine_Data_18_HS3: 8 GWM
 SG_ WaterInFuel_B_Falt_UB : 28|1@0+ (1,0) [0|1] "SED"  IPC
 SG_ WaterInFuel_B_Falt : 29|1@0+ (1,0) [0|1] "SED"  IPC
 SG_ UreaMxAdd_L2_Actl_UB : 34|1@0+ (1,0) [0|1] "SED"  IPC
 SG_ VehUreaRnge3_L_DsplyMx_UB : 30|1@0+ (1,0) [0|1] "SED"  IPC
 SG_ UreaMnAdd_L2_Actl_UB : 31|1@0+ (1,0) [0|1] "SED"  IPC
 SG_ UreaMnAdd_L2_Actl : 7|8@0+ (0.1,0) [0|25.4] "litre"  IPC
 SG_ VehUreaRnge3_L_DsplyMx : 15|16@0+ (1,0) [0|65535] "unitless"  IPC
 SG_ UreaMxAdd_L2_Actl : 27|9@0+ (0.1,0) [0|51] "litre"  IPC

BO_ 942 ParkAid_Data2_HS3: 8 GWM
 SG_ ApaOffOptnSel_B_Avail : 51|1@0+ (1,0) [0|1] "SED"  APIM_CISM,APIM
 SG_ PrkBrkElRleas_B_RqApa : 50|1@0+ (1,0) [0|0] "SED"  GENERIC
 SG_ ApaDrvRq2MsgTxt_D_Rq : 55|4@0+ (1,0) [0|15] "SED"  APIM_CISM,APIM
 SG_ ApaDrvRq1MsgTxt_D_Rq : 42|3@0+ (1,0) [0|7] "SED"  APIM_CISM,APIM
 SG_ ApaSys_D2_Stat : 35|4@0+ (1,0) [0|15] "SED"  APIM_CISM,APIM
 SG_ ApaSlotTrgt_D_Stat : 39|4@0+ (1,0) [0|15] "SED"  APIM_CISM,APIM
 SG_ ApaSlotOption_B_Avail : 43|1@0+ (1,0) [0|1] "SED"  APIM_CISM,APIM
 SG_ ApaSlotAlrtSet_B_Stat : 44|1@0+ (1,0) [0|1] "SED"  APIM_CISM,APIM
 SG_ ApaSlotAlrt_B_Rq : 45|1@0+ (1,0) [0|1] "SED"  APIM_CISM,APIM
 SG_ ApaRmtFeatSel_B_Avail : 46|1@0+ (1,0) [0|1] "SED"  APIM_CISM,APIM
 SG_ ApaParkOutSel_B_Avail : 47|1@0+ (1,0) [0|1] "SED"  APIM_CISM,APIM
 SG_ ApaParkInSel_B_Avail : 24|1@0+ (1,0) [0|1] "SED"  APIM_CISM,APIM
 SG_ ApaMsgTxt_D2_Stat : 28|4@0+ (1,0) [0|15] "SED"  APIM_CISM,APIM
 SG_ ApaDynmcSlot_B_Stat : 29|1@0+ (1,0) [0|1] "SED"  APIM_CISM,APIM
 SG_ ApaDisplayMode_D_Stat : 31|2@0+ (1,0) [0|3] "SED"  APIM_CISM,APIM
 SG_ ApaControlMode_D_Stat : 16|1@0+ (1,0) [0|1] "SED"  APIM_CISM,APIM
 SG_ PrkAidAcsyRear_D_Stat : 18|2@0+ (1,0) [0|3] "SED"  IPC
 SG_ PrkAidAcsyFront_D_Stat : 20|2@0+ (1,0) [0|3] "SED"  IPC
 SG_ PrkAidRdiusRight_L_Dsply : 15|8@0+ (1,0) [0|255] "unitless"  APIM_CISM,APIM
 SG_ PrkAidRdiusLeft_L_Dsply : 7|8@0+ (1,0) [0|255] "unitless"  APIM_CISM,APIM
 SG_ PrkAidDrvDir_D_Stat : 23|3@0+ (1,0) [0|7] "SED"  APIM_CISM,APIM

BO_ 634 GWM_Send_Signals_7_HS3: 8 GWM
 SG_ EngAirFiltMsgTxt_D_Rq_UB : 56|1@0+ (1,0) [0|1] "SED"  IPC
 SG_ EngAirFiltMsgTxt_D_Rq : 59|3@0+ (1,0) [0|7] "SED"  IPC
 SG_ AutoHoldSwMde_B_Ind_UB : 62|1@0+ (1,0) [0|1] "SED"  APIM_CISM,APIM
 SG_ AutoHoldSwMde_B_Ind : 63|1@0+ (1,0) [0|1] "SED"  APIM_CISM,APIM
 SG_ Ccd_B_Falt_UB : 24|1@0+ (1,0) [0|1] "SED"  IPC
 SG_ Ccd_B_Falt : 25|1@0+ (1,0) [0|1] "SED"  IPC
 SG_ RearDiffLckLamp_D_Rq3_UB : 47|1@0+ (1,0) [0|1] "SED"  IPC
 SG_ AwdLckLamp_D_Rq_UB : 12|1@0+ (1,0) [0|1] "SED"  IPC
 SG_ RearDiffLckLamp_D_Rq3 : 61|2@0+ (1,0) [0|3] "SED"  IPC
 SG_ AwdLckLamp_D_Rq : 14|2@0+ (1,0) [0|3] "SED"  IPC
 SG_ AutoTowAllw_D_StatMnu_UB : 26|1@0+ (1,0) [0|1] "SED"  IPC
 SG_ AutoTowAllw_D_StatMnu : 28|2@0+ (1,0) [0|3] "SED"  IPC
 SG_ AutoTowActv_B_Stat : 30|1@0+ (1,0) [0|1] "SED"  DACMC,IPC
 SG_ AutoTowActv_B_Stat_UB : 29|1@0+ (1,0) [0|1] "SED"  IPC
 SG_ LdwChime_B_Rq_UB : 5|1@0+ (1,0) [0|1] "SED"  IPC
 SG_ HdcOn_B_Ind : 7|1@0+ (1,0) [0|1] "SED"  IPC
 SG_ HdcOn_B_Ind_UB : 6|1@0+ (1,0) [0|1] "SED"  IPC
 SG_ SuspVLimMsgTxt_B_Rq_UB : 4|1@0+ (1,0) [0|1] "SED"  IPC
 SG_ SuspVlimMsgTxt_B_Rq : 31|1@0+ (1,0) [0|1] "SED"  IPC
 SG_ EngExhMdeQuiet_D2_Stat_UB : 0|1@0+ (1,0) [0|1] "SED"  APIM_CISM,APIM,IPC,ACM
 SG_ EngExhMdeQuiet_D2_Stat : 3|3@0+ (1,0) [0|7] "SED"  APIM_CISM,APIM,IPC,ACM
 SG_ ChrgCrdLck_D_Falt_UB : 44|1@0+ (1,0) [0|1] "SED"  APIM_CISM,APIM,IPC
 SG_ LdwChime_B_Rq : 15|1@0+ (1,0) [0|1] "SED"  IPC
 SG_ ChrgCrdLck_D_Falt : 46|2@0+ (1,0) [0|3] "SED"  APIM_CISM,APIM,IPC

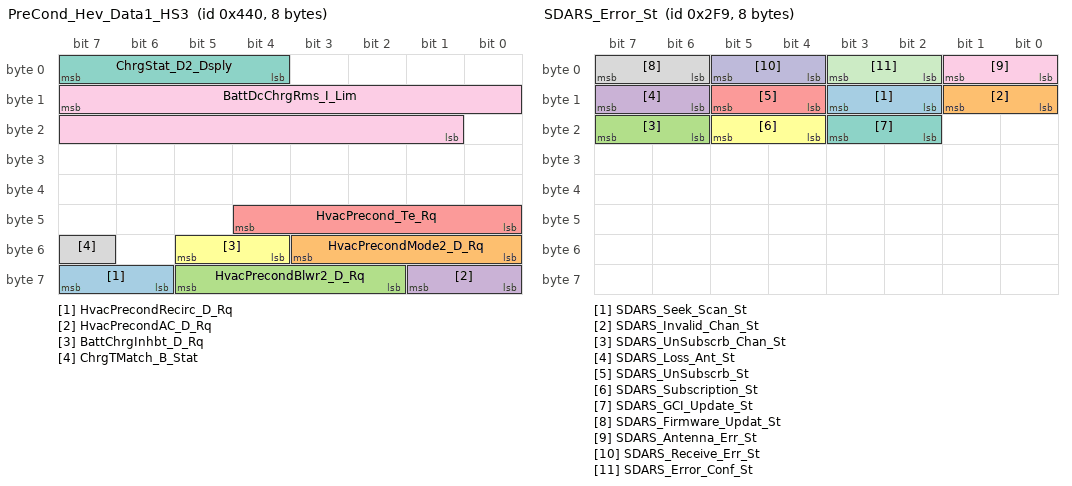
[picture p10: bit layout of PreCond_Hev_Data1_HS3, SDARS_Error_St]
BO_ 1088 PreCond_Hev_Data1_HS3: 8 GWM
 SG_ HvacPrecondRecirc_D_Rq : 63|2@0+ (1,0) [0|3] "SED"  GENERIC
 SG_ HvacPrecondMode2_D_Rq : 51|4@0+ (1,0) [0|15] "SED"  GENERIC
 SG_ HvacPrecondBlwr2_D_Rq : 61|4@0+ (1,0) [0|15] "SED"  GENERIC
 SG_ HvacPrecondAC_D_Rq : 57|2@0+ (1,0) [0|3] "SED"  GENERIC
 SG_ HvacPrecond_Te_Rq : 44|5@0+ (0.5,14.5) [14.5|30] "deg C"  GENERIC
 SG_ BattChrgInhbt_D_Rq : 53|2@0+ (1,0) [0|3] "SED"  APIM_CISM,GENERIC
 SG_ ChrgStat_D2_Dsply : 7|4@0+ (1,0) [0|15] "SED"  APIM_CISM,APIM,IPC
 SG_ ChrgTMatch_B_Stat : 55|1@0+ (1,0) [0|1] "SED"  IPC
 SG_ BattDcChrgRms_I_Lim : 15|15@0+ (0.05,0) [0|1638.25] "ampere"  GENERIC

BO_ 706 SDARS_MC_WORD_Tx: 8 ACM
 SG_ SDARS_MC_WORD_Tx : 7|64@0+ (1,0) [0|1.84467440737096E+019] "unitless"  IPC

BO_ 761 SDARS_Error_St: 8 ACM
 SG_ SDARS_Seek_Scan_St : 11|2@0+ (1,0) [0|3] "SED"  HUD_ADV,RACM_RCIM,APIM,IPC
 SG_ SDARS_Invalid_Chan_St : 9|2@0+ (1,0) [0|3] "SED"  HUD_ADV,RACM_RCIM,APIM,IPC
 SG_ SDARS_UnSubscrb_Chan_St : 23|2@0+ (1,0) [0|3] "SED"  HUD_ADV,RACM_RCIM,APIM,IPC
 SG_ SDARS_Loss_Ant_St : 15|2@0+ (1,0) [0|3] "SED"  HUD_ADV,APIM,RACM_RCIM,IPC
 SG_ SDARS_UnSubscrb_St : 13|2@0+ (1,0) [0|3] "SED"  HUD_ADV,RACM_RCIM,APIM,IPC
 SG_ SDARS_Subscription_St : 21|2@0+ (1,0) [0|3] "SED"  HUD_ADV,RACM_RCIM,APIM,IPC
 SG_ SDARS_GCI_Update_St : 19|2@0+ (1,0) [0|3] "SED"  HUD_ADV,RACM_RCIM,APIM,IPC
 SG_ SDARS_Firmware_Updat_St : 7|2@0+ (1,0) [0|3] "SED"  HUD_ADV,RACM_RCIM,APIM,IPC
 SG_ SDARS_Antenna_Err_St : 1|2@0+ (1,0) [0|3] "SED"  HUD_ADV,RACM_RCIM,APIM,IPC
 SG_ SDARS_Receive_Err_St : 5|2@0+ (1,0) [0|3] "SED"  HUD_ADV,RACM_RCIM,APIM,IPC
 SG_ SDARS_Error_Conf_St : 3|2@0+ (1,0) [0|3] "SED"  HUD_ADV,RACM_RCIM,APIM,IPC

BO_ 694 PHONE_MC_WORD_Tx: 8 APIM
 SG_ PHONE_MC_WORD_Tx : 7|64@0+ (1,0) [0|1.84467440737096E+019] "unitless"  IPC

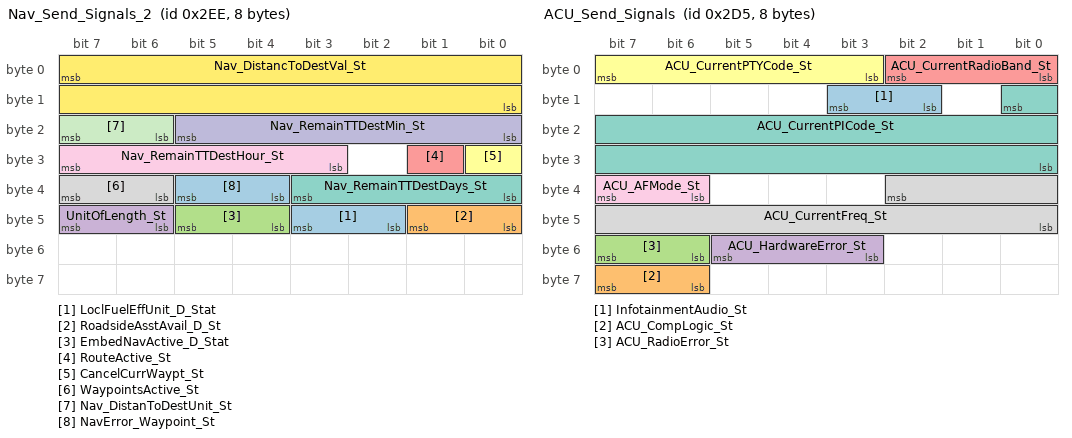
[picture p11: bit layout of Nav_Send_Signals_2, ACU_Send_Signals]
BO_ 750 Nav_Send_Signals_2: 8 APIM
 SG_ LoclFuelEffUnit_D_Stat : 43|2@0+ (1,0) [0|3] "SED"  IPC
 SG_ RoadsideAsstAvail_D_St : 41|2@0+ (1,0) [0|3] "SED"  IPC
 SG_ EmbedNavActive_D_Stat : 45|2@0+ (1,0) [0|3] "SED"  IPC
 SG_ UnitOfLength_St : 47|2@0+ (1,0) [0|3] "SED"  IPC
 SG_ RouteActive_St : 25|1@0+ (1,0) [0|1] "SED"  HUD_ADV,IPC
 SG_ CancelCurrWaypt_St : 24|1@0+ (1,0) [0|1] "SED"  IPC
 SG_ Nav_RemainTTDestDays_St : 35|4@0+ (1,0) [0|14] "day"  HUD_ADV,IPC
 SG_ WaypointsActive_St : 39|2@0+ (1,0) [0|3] "SED"  IPC
 SG_ Nav_RemainTTDestHour_St : 31|5@0+ (1,0) [0|31] "hour"  HUD_ADV,IPC
 SG_ Nav_RemainTTDestMin_St : 21|6@0+ (1,0) [0|63] "minute"  HUD_ADV,IPC
 SG_ Nav_DistanToDestUnit_St : 23|2@0+ (1,0) [0|3] "SED"  HUD_ADV,IPC
 SG_ Nav_DistancToDestVal_St : 7|16@0+ (1,0) [0|65534] "unitless"  HUD_ADV,IPC
 SG_ NavError_Waypoint_St : 37|2@0+ (1,0) [0|3] "SED"  HUD_ADV,IPC

BO_ 704 NAV_MC_WORD_Tx: 8 APIM
 SG_ NAV_MC_WORD_Tx : 7|64@0+ (1,0) [0|1.84467440737096E+019] "unitless"  IPC

BO_ 725 ACU_Send_Signals: 8 ACM
 SG_ InfotainmentAudio_St : 11|2@0+ (1,0) [0|3] "SED"  GWM,APIM,DSP
 SG_ ACU_CompLogic_St : 63|2@0+ (1,0) [0|3] "SED"  GWM,GENERIC
 SG_ ACU_RadioError_St : 55|2@0+ (1,0) [0|3] "SED"  RACM_RCIM,GWM,APIM,IPC
 SG_ ACU_HardwareError_St : 53|3@0+ (1,0) [0|7] "SED"  RACM_RCIM,GWM,APIM,IPC
 SG_ ACU_CurrentRadioBand_St : 2|3@0+ (1,0) [0|7] "SED"  GWM,IPC
 SG_ ACU_CurrentPTYCode_St : 7|5@0+ (1,0) [0|31] "unitless"  RACM_RCIM,GWM,APIM,IPC
 SG_ ACU_CurrentPICode_St : 8|17@0+ (1,0) [0|65535] "unitless"  RACM_RCIM,GWM,APIM
 SG_ ACU_CurrentFreq_St : 34|11@0+ (1,0) [0|1557] "unitless"  HUD_ADV,RACM_RCIM,GWM,APIM,WCM,IPC,DSP
 SG_ ACU_AFMode_St : 39|2@0+ (1,0) [0|3] "SED"  GWM,APIM

BO_ 1074 BodyEngGateway_2_HS3: 8 GWM
 SG_ TrlrTireDual_D_Stat_UB : 13|1@0+ (1,0) [0|1] "SED"  APIM_CISM,APIM,IPC
 SG_ TrlrTireDual_D_Stat : 27|4@0+ (1,0) [0|15] "SED"  APIM_CISM,APIM,IPC
 SG_ PwLftgtIntSw_B_Stat_UB : 14|1@0+ (1,0) [0|1] "SED"  APIM_CISM,APIM
 SG_ PwLftgtIntSw_B_Stat : 15|1@0+ (1,0) [0|1] "SED"  APIM_CISM,APIM
 SG_ E_Frt_Btn_Status_1st_UB : 0|1@0+ (1,0) [0|1] "SED"  APIM_CISM,APIM
 SG_ E_Frt_Btn_Status_2nd_UB : 1|1@0+ (1,0) [0|1] "SED"  APIM_CISM,APIM
 SG_ E_Frt_Btn_Status_2nd : 39|6@0+ (1,0) [0|63] "SED"  APIM_CISM,APIM
 SG_ E_Frt_Btn_Status_1st : 7|6@0+ (1,0) [0|63] "SED"  APIM_CISM,APIM
 SG_ DrLatchRrMsgTxt_D_Rq_UB : 28|1@0+ (1,0) [0|1] "SED"  IPC
 SG_ DrLatchRrMsgTxt_D_Rq : 31|3@0+ (1,0) [0|7] "SED"  IPC
 SG_ DrLatchRlMsgTxt_D_Rq_UB : 16|1@0+ (1,0) [0|1] "SED"  IPC
 SG_ DrLatchRlMsgTxt_D_Rq : 19|3@0+ (1,0) [0|7] "SED"  IPC
 SG_ DrLatchFrMsgTxt_D_Rq_UB : 20|1@0+ (1,0) [0|1] "SED"  IPC
 SG_ DrLatchFrMsgTxt_D_Rq : 23|3@0+ (1,0) [0|7] "SED"  IPC
 SG_ DrLatchFlMsgTxt_D_Rq_UB : 8|1@0+ (1,0) [0|1] "SED"  IPC
 SG_ DrLatchFlMsgTxt_D_Rq : 11|3@0+ (1,0) [0|7] "SED"  IPC
 SG_ TrlrTireThresh_D_Stat_UB : 41|1@0+ (1,0) [0|1] "SED"  IPC
 SG_ TrlrTireThresh_D_Stat : 55|8@0+ (1,0) [0|255] "unitless"  IPC
 SG_ TrlrTireSys_D_Stat_UB : 40|1@0+ (1,0) [0|1] "SED"  IPC
 SG_ TrlrTireSys_D_Stat : 63|4@0+ (1,0) [0|15] "SED"  IPC
 SG_ TrlrTireCnt_D_Stat_UB : 56|1@0+ (1,0) [0|1] "SED"  IPC
 SG_ TrlrTireCnt_D_Stat : 59|3@0+ (1,0) [0|6] "SED"  IPC
 SG_ BrkMdeInhbt_B_RqDsply_UB : 42|1@0+ (1,0) [0|1] "SED"  IPC
 SG_ BrkMdeInhbt_B_RqDsply : 43|1@0+ (1,0) [0|1] "SED"  IPC

BO_ 1014 WCM_Send_Signals: 8 WCM
 SG_ WrlssAcsyChrg_Pc_Actl : 15|7@0+ (1,0) [0|125] "percent"  APIM_CISM,APIM
 SG_ WrlssAcsyChrgr_D_Stat : 7|3@0+ (1,0) [0|7] "SED"  APIM_CISM,APIM

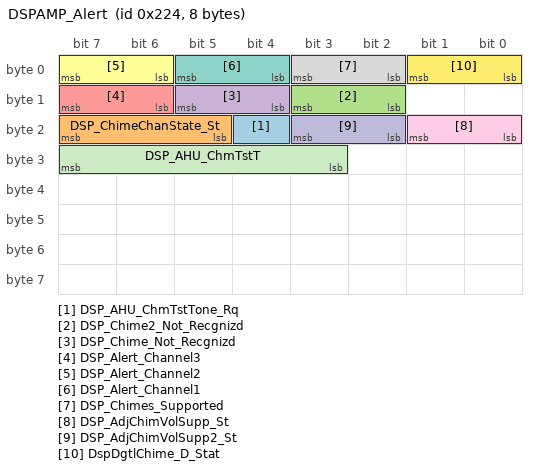
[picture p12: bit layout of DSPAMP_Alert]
BO_ 548 DSPAMP_Alert: 8 DSP
 SG_ DSP_AHU_ChmTstTone_Rq : 20|1@0+ (1,0) [0|1] "SED"  APIM_CISM,ACM
 SG_ DSP_ChimeChanState_St : 23|3@0+ (1,0) [0|7] "SED"  APIM_CISM,ACM
 SG_ DSP_Chime2_Not_Recgnizd : 11|2@0+ (1,0) [0|3] "SED"  APIM_CISM,IPC
 SG_ DSP_Chime_Not_Recgnizd : 13|2@0+ (1,0) [0|3] "SED"  APIM_CISM,IPC
 SG_ DSP_Alert_Channel3 : 15|2@0+ (1,0) [0|3] "SED"  RACM_RCIM,APIM_CISM,APIM,IPC
 SG_ DSP_Alert_Channel2 : 7|2@0+ (1,0) [0|3] "SED"  APIM_CISM,ACM,IPC
 SG_ DSP_Alert_Channel1 : 5|2@0+ (1,0) [0|3] "SED"  IPC,APIM_CISM,ACM
 SG_ DSP_Chimes_Supported : 3|2@0+ (1,0) [0|3] "SED"  APIM,APIM_CISM,ACM,IPC
 SG_ DSP_AdjChimVolSupp_St : 17|2@0+ (1,0) [0|4] "SED"  APIM_CISM,IPC,ACM
 SG_ DSP_AdjChimVolSupp2_St : 19|2@0+ (1,0) [0|4] "SED"  APIM_CISM,IPC,ACM
 SG_ DSP_AHU_ChmTstT : 31|5@0+ (1,0) [0|15] "SED"  APIM_CISM,ACM
 SG_ DspDgtlChime_D_Stat : 1|2@0+ (1,0) [0|3] "SED"  APIM_CISM,ACM

BO_ 404 Dsp_Response_Signals: 8 APIM
 SG_ Dsp_LangUpdate_Rsp : 7|2@0+ (1,0) [0|3] "SED"  IPC

BO_ 689 AUDIO_MC_WORD_Tx: 8 ACM
 SG_ AUDIO_MC_WORD_Tx : 7|64@0+ (1,0) [0|1.84467440737096E+019] "unitless"  IPC

BO_TX_BU_ 145 : APIM_CISM,APIM;
BO_TX_BU_ 598 : APIM_CISM,APIM;
BO_TX_BU_ 597 : APIM_CISM,ACM;
BO_TX_BU_ 736 : APIM_CISM,APIM;
BO_TX_BU_ 722 : APIM_CISM,APIM;
BO_TX_BU_ 721 : APIM_CISM,APIM;
BO_TX_BU_ 720 : APIM_CISM,APIM;
BO_TX_BU_ 470 : APIM_CISM,APIM;
BO_TX_BU_ 758 : APIM_CISM,ACM;
BO_TX_BU_ 760 : APIM_CISM,ACM;
BO_TX_BU_ 706 : APIM_CISM,ACM;
BO_TX_BU_ 761 : APIM_CISM,ACM;
BO_TX_BU_ 694 : APIM_CISM,APIM;
BO_TX_BU_ 750 : APIM_CISM,APIM;
BO_TX_BU_ 704 : APIM_CISM,APIM;
BO_TX_BU_ 725 : APIM_CISM,ACM;
BO_TX_BU_ 404 : APIM_CISM,APIM;
BO_TX_BU_ 689 : APIM_CISM,ACM;
CM_ SG_ 643 GearPos_D_Trg "Powersplit HEVs with HF45, HPCM will Tx  this message.  For all other programs it will be Tx by PCM or TCM. ";
CM_ BO_ 145 "MFD Shall not send this message when configured as a slave

Method: Clock Modes";
CM_ SG_ 145 MFD_Year "Used by MFD to distribute actual Master Clock data to the Slave";
CM_ SG_ 145 MFD_Second "Used by MFD to distribute actual Master Clock data to the Slave";
CM_ SG_ 145 MFD_Month "Used by MFD to distribute actual Master Clock data to the Slave";
CM_ SG_ 145 MFD_Minute "Used by MFD to distribute actual Master Clock data to the Slave";
CM_ SG_ 145 MFD_Hour "Used by MFD to distribute actual Master Clock data to the Slave";
CM_ SG_ 145 MFD_Day "Used by MFD to distribute actual Master Clock data to the Slave";
CM_ SG_ 607 RDRV_RSE_WORD_Rx "MM ISO 15765-2 Message Catalogue RSE - RDRV";
CM_ SG_ 598 CONMP_RSE_WORD_Tx "MM ISO 15765-2 Message Catalogue MediaPlayerServer – MediaPlayerClient3";
CM_ SG_ 606 CONMP_RSE_WORD_Rx "MM ISO 15765-2 Message Catalogue MediaPlayerClient3 - MediaPlayerServer";
CM_ SG_ 597 AUDIO_RSE_WORD_Tx "MM ISO 15765-2 Message Catalogue AUDIO - RSE";
CM_ SG_ 605 AUDIO_RSE_WORD_Rx "MM ISO 15765-2 Message Catalogue RSE - AUDIO";
CM_ SG_ 545 SurndSndUpmix2_D_Stat "Object:Surround_Sound_Upmix2_St";
CM_ SG_ 545 SndImmrsnLvl_D_Stat "ImmersionLevel_D_St";
CM_ SG_ 545 DSP_Sur_Sound_st "Method DSP_Sur_Sound_Upmix.St";
CM_ SG_ 545 DSP_MyKeyVolLimitUp_St "Method MykeyvolumeIsLimited";
CM_ SG_ 545 DSP_MyKeyVolLim_St "Method MykeyvolumeIsLimited";
CM_ SG_ 545 DSP_BeltminderAudio_St "Object.MyKey.BeltminderAudioIsMuted";
CM_ SG_ 545 DSP_Audio_Volume_Up_St "Object.VolumeControl.DSP_Audio_Vol_updated
";
CM_ SG_ 545 DSP_Audio_Vol_Level_St "Object.VolumeControl.DSP_Audio_Vol_Level.St

0x0 No Volume
0x1 Vol_Step1
0x2 Vol_Step2
0x3 Vol_Step3
Cont.
0x1E Vol_Step30";
CM_ SG_ 545 AudioOccMde_D_Stat "Object: Occupancy_Mode.St";
CM_ SG_ 674 RACM_SetVolume "Object CAN Button Strategy.BCP_Button_Press.SetVolume";
CM_ SG_ 674 RACM_Coding_BtnID_D "Object InputControlInterface ICI ButtonCoding_D
Object InputControlInterface ICI ButtonID_D";
CM_ SG_ 674 RACM_Coding_BtnID_C "Object InputControlInterface.ICI ButtonCoding_C
Object InputControlInterface.ICI ButtonID_C";
CM_ SG_ 674 RACM_Coding_BtnID_B "Object InputControlInterface ICI ButtonCoding_B
Object InputControlInterface.ICI ButtonID_B";
CM_ SG_ 674 RACM_Coding_BtnID_A "Object InputControlInterface ICI ButtonCoding_A
Object InputControlInterface.ICI ButtonID A";
CM_ SG_ 674 RACM_BtnID_D "Object InputControlInterface ICI ButtonID_D... 0xFF: Inactive";
CM_ SG_ 674 RACM_BtnID_C "Object InputControlInterface ICI ButtonID_D... 0xFF: Inactive";
CM_ SG_ 674 RACM_BtnID_B "Object InputControlInterface ICI ButtonID_D... 0xFF: Inactive";
CM_ SG_ 674 RACM_BtnID_A "Object InputControlInterface ICI ButtonID_D... 0xFF: Inactive";
CM_ SG_ 674 RearAudioCtlLck_D_Stat "RACLockout_St";
CM_ BO_ 74 "Reserve eCallNotification message";
CM_ SG_ 736 TextMessage_Rsp "Object.BTPhoneServer.TextMessage.Rsp.ResponseCode";
CM_ SG_ 736 VRM_IncCallOption_St "Object Bluetooth Phone.IncCallOption";
CM_ SG_ 736 VRM_PhonesSts_Rsp "Object Bluetooth Phone

Bit 0:  0: invalid, 1: valid
Bit 1: 
0:  Phone on index 1 not  connectable.
1: Phone on index 1 connectable.
.......
Bit 6: 
0:  Phone on index 6 not  connectable.
1: Phone on index 6 connectable.";
CM_ SG_ 736 VRM_CallDuration_St "Object Bluetooth Phone.CallDuration";
CM_ SG_ 736 BTInCallOptions_St "Object.BTPhoneServer.BTInCallOptions.Rsp.Result";
CM_ SG_ 722 VRM_ComShuffleTrack_St "Object Voice Recogniser.ComShuffleTrack";
CM_ SG_ 722 VRM_ComCompression_St "Object Voice Recogniser.ComCompression";
CM_ SG_ 722 VRM_ComStFreqMode_St "Object Voice Recogniser.ComFrequency(Parameter1)
Object Voice Recogniser.ComStation";
CM_ SG_ 722 VRM_ComAutostore_St "Object Voice Recogniser.ComAutostore";
CM_ SG_ 722 VRM_ComBand_St "Object Voice Recogniser.ComBand";
CM_ SG_ 722 VRM_TMCVoice "Object Voice Recogniser.TMC Voice";
CM_ SG_ 722 VRM_NewSMS "Object Bluetooth Phone";
CM_ SG_ 722 VRM_ComRSEDisplay_St "Object Voice Recogniser.ComRSEDisplay
NOT USED";
CM_ SG_ 722 VRM_ComPICode_St "Object Voice Recogniser.ComStation(PI Code)
(Parameter1)

16 bit hex coded PI Code";
CM_ SG_ 722 VRM_ComPresetCall_St "Object Voice Recogniser.ComPresetCall
NOT USED";
CM_ SG_ 722 VRM_ComTape_St "Object Voice Recogniser.ComTape
NOT USED";
CM_ SG_ 722 VRM_ComShuffleDiscs_St "Object Voice Recogniser.ComShuffleDiscs
NOT USED";
CM_ SG_ 722 VRM_ComDolbyNR_St "Object Voice Recogniser.ComDolbyNr
NOT USED";
CM_ SG_ 722 VRM_ComSourceSelect_St "Object Voice Recogniser.ComSourceSelect";
CM_ SG_ 722 VRM_ComStFreq_St "Object Voice Recogniser.ComFrequency(Parameter2)
Object Voice Recogniser.ComStation(Parameter2)

AM: Freq = 153+ Offset kHz. Offset 0..1557
FM: Freq = 76+ Offset*0.05 MHz. Offset 0..640
Selected tuned band determine frequency (kHz or MHz).
";
CM_ SG_ 722 VRM_ComRouteStrategy_St "Object Voice Recogniser.ComRouteStrategy";
CM_ SG_ 721 VRM_BTDefaultPhone_St "Object Voice Recogniser.BTDefaultPhone";
CM_ SG_ 721 VRM_DetourUnit_st "Object Voice Recogniser.DetourUnit";
CM_ SG_ 721 VRM_Zoom_Option_St "Object Voice Recogniser.ComZoom";
CM_ SG_ 721 VRM_ComBTDTMFTone_St "Object Voice Recogniser.ComBTDTMFTone";
CM_ SG_ 721 VRM_SuggestedRoute_St "Object Voice Recogniser.ComSuggestedRoute
NOT USED";
CM_ SG_ 721 VRM_ComDelWaypoint_St "Object Voice Recogniser.ComDelWaypoint";
CM_ SG_ 721 VRM_ComSelectDisc_St "Object Voice Recogniser.ComSelectDisc";
CM_ SG_ 721 VRM_ComTelService_St "Object Voice Recogniser.ComTelematicsService
NOT USED";
CM_ SG_ 721 VRM_ComDestHome_St "Object Voice Recogniser.ComDestHome";
CM_ SG_ 721 VRM_ComSelectTrack_St "Object Voice Recogniser.ComSelectTrack

$01: Command has not been issued";
CM_ SG_ 721 VRM_ComShowNavInfo_St "Object Voice Recogniser.ComShowNavInfo";
CM_ SG_ 721 VRM_VoiceRecStatus_St "Object VoiceRecognizer.VoiceRecStatus";
CM_ SG_ 721 VRM_ComSelTrackSource_St "Object Voice Recogniser.ComSelectTrack, parameter Source";
CM_ SG_ 721 VRM_ComDetour_St "Object Voice Recogniser.ComDetour";
CM_ SG_ 721 VRM_ComDisplay_St "Object Voice Recogniser.ComDisplay";
CM_ SG_ 721 VRM_ComDynamicGuidande_St "Object Voice Recogniser.DynamicRouteGuidance";
CM_ SG_ 721 VRM_ComZoom_St "Object Voice Recogniser.ComZoom";
CM_ SG_ 721 VRM_ComCallControl_St "Object Voice Recogniser.ComCallControl
NOT USED";
CM_ SG_ 721 VRM_ComGuidance_St "Object Voice Recogniser.ComGuidance";
CM_ SG_ 721 VRM_ComTrafficInfDsp_St "Object Voice Recogniser.ComTrafficInformation";
CM_ SG_ 720 VRM_PhMicrophoneMute_St "Object Bluetooth Phone.PhMicrophoneMute";
CM_ SG_ 720 Aioc_ExtSrcOutpMode_St "Object Audio Management Audio Switch.BVCOutputMode";
CM_ SG_ 720 VRM_BTPhoneSts_St "Object Bluetooth Phone.BTPhoneSts";
CM_ SG_ 720 VRM_SubscribeStatus_St "Object Bluetooth Phone";
CM_ SG_ 720 VRM_BlutoothStatus_St "Object Bluetooth Phone (Spelled as BluetoothStatus in OS)";
CM_ SG_ 720 VRM_BondRequest_St "Object Bluetooth Phone";
CM_ SG_ 720 VRM_VRMMonoOutMode_St "Object VRMAudioIOController.VRMMonoOutMode";
CM_ SG_ 720 VRM_BTNetworkStatus_St "Object Bluetooth Phone.BTNetworkStatus";
CM_ SG_ 720 VRM_BTSignalStrength_St "Object Bluetooth Phone.BTSignalStrength";
CM_ SG_ 720 VRM_BTBatteryLevel_St "Object Bluetooth Phone.BTBatteryLevel";
CM_ SG_ 758 SDARS_OpMode_St "Object Tuner.SDARS Tuner.OperationMode";
CM_ SG_ 758 SDARS_SetCategory_St "Object.ExternalPersonalization.SDARS_SetCategory.St.Category
0x00: All
0x01: Category1
0x02: Category2
....
0xF9: Category249
0xFA: Reserved
....
0xFE: Reserved
0xFF: Invalid 
";
CM_ SG_ 758 SDARS_GCI_Update_Prg_St "Object Tuner.SDARS Tuner.GCIUpdateProgress
0-100%";
CM_ SG_ 758 SDARS_Factory_Reset_St "Object Tuner.SDARS Tuner.FactoryReset";
CM_ SG_ 760 SDARS_SID_St "Object Tuner.SDARS.ServiceID
$0: SID_0
$1: SID_1
$2: SID_2
$FE: SID_254
$FF: SID_255

";
CM_ SG_ 760 SDARS_CurrentChanNum_St "Object Tuner.SDARS Tuner.CurrentChanNum.ChanNum 
$0: Channel_0
$1: Channel_1
$2: Channel_2
$FE: Channel_254
$FF: Inactive";
CM_ SG_ 760 SDARS_Buffer_sec_St "Object Tuner.SDARS Tuner.BufferStatus.Second
(Parameter5)
";
CM_ SG_ 760 SDARS_Buffer_min_St "Object Tuner.SDARS Tuner.BufferStatus.Minute
(Parameter4)
";
CM_ SG_ 760 SDARS_Buffer_hr_St "Object Tuner.SDARS Tuner.BufferStatus.Hour
(Parameter3)
";
CM_ SG_ 760 SDARS_Playback_St "Method SDARS_BufferStatus
0-100%
Object Tuner.SDARS Tuner.BufferStatus.PlaybackPosition
(Parameter2)";
CM_ SG_ 760 SDARS_FillPosition_St "Method SDARS_BufferStatus
0-100%
Object Tuner.SDARS Tuner.BufferStatus.FillPosition
(Parameter1)";
CM_ SG_ 760 SDARS_Alert_Status "Object.Tuner.SDARS.AlertStatus";
CM_ SG_ 760 SDARS_Channel_Lock "Method SDARS_Channel_Lock";
CM_ SG_ 692 AUDIO_RDISP_WORD_Tx "MM ISO 15765-2 Message Catalogue
Section AUDIO - RDISP";
CM_ SG_ 942 PrkAidRdiusRight_L_Dsply "MSGDCR 679, set all signals to OnChange";
CM_ SG_ 942 PrkAidRdiusLeft_L_Dsply "MSGDCR 679, set all signals to OnChange";
CM_ SG_ 942 PrkAidDrvDir_D_Stat "MSGDCR 679, set all signals to OnChange";
CM_ SG_ 1088 HvacPrecondMode2_D_Rq "Signal not transmitted on vehicles that do not have the Fuel operated heater feature.";
CM_ SG_ 1088 HvacPrecondBlwr2_D_Rq "Signal not transmitted on vehicles that do not have the Fuel operated heater feature.";
CM_ SG_ 761 SDARS_Seek_Scan_St "Method SDARS_Error_Msg
Int Seek/Scan No Channels Available

0x1: No Channel Available
Object Tuner.SDARS Tuner.";
CM_ SG_ 761 SDARS_Invalid_Chan_St "Object Tuner.SDARS Tuner.";
CM_ SG_ 761 SDARS_UnSubscrb_Chan_St "Object Tuner.SDARS Tuner.Unsubscribed Channel ";
CM_ SG_ 761 SDARS_Loss_Ant_St "Object Tuner.SDARS Tuner.Loss of Antenna Signal ";
CM_ SG_ 761 SDARS_UnSubscrb_St "Object Tuner.SDARS Tuner.Unsubscribed Receiver ";
CM_ SG_ 761 SDARS_Subscription_St "Object Tuner.SDARS Tuner.Subscription Update ";
CM_ SG_ 761 SDARS_GCI_Update_St "Object Tuner.SDARS Tuner.GCI Update ";
CM_ SG_ 761 SDARS_Firmware_Updat_St "Object Tuner.SDARS Tuner.FirmwareUpdate";
CM_ SG_ 761 SDARS_Antenna_Err_St "Object Tuner.SDARS Tuner.Antenna Error";
CM_ SG_ 761 SDARS_Receive_Err_St "Object Tuner.SDARS Tuner.Receiver Error";
CM_ SG_ 761 SDARS_Error_Conf_St "Object Tuner.SDARS Tuner.Configuration Status";
CM_ SG_ 694 PHONE_MC_WORD_Tx "MM ISO 15765-2 Message Catalogue
Section  PHONE - MC";
CM_ SG_ 750 UnitOfLength_St "Object.VehicleSettings.LengthUnit.St";
CM_ SG_ 750 RouteActive_St "RouteActive";
CM_ SG_ 750 CancelCurrWaypt_St "Object.NavigationRepeater.CancelCurrentWayPoint.Rsp.Cancelwaypoint";
CM_ SG_ 750 Nav_RemainTTDestDays_St "Object.NavigationRepeater.RemainTimeToDestination.Days
0x0…0xD: days (0…13)
0xE: greater than 13 days";
CM_ SG_ 750 WaypointsActive_St "Object:NavigationRepeater.WaypointsActive.St.WaypointStatus";
CM_ SG_ 750 Nav_RemainTTDestHour_St "Object Navigation.RemainTimeToDestination
0x00 .. 0x18: hours (0 .. 24)
0x19 .. 0x1D: reserved
0x1E : not available";
CM_ SG_ 750 Nav_RemainTTDestMin_St "Object Navigation.RemainTimeToDestination
0x00 .. 0x3C: minutes (0 .. 60)
0x3D .. 0x3D: reserved
0x3E : not available";
CM_ SG_ 750 Nav_DistanToDestUnit_St "Object Navigation.DistanceToDestination

This attribute shows the remaining distance to destination to the infotainment displays.
";
CM_ SG_ 750 Nav_DistancToDestVal_St "Object Navigation.DistanceToDestination

This attribute shows the remaining distance to destination to the infotainment displays.

0x0000 .. 0xFFFD: distance (0 .. 65533)
0xFFFE : distance not available";
CM_ SG_ 750 NavError_Waypoint_St "Object:NavigationRepeater.NAVError.WaypointStatus";
CM_ SG_ 704 NAV_MC_WORD_Tx "MM ISO 15765-2 Message Catalogue
Section NAV - MC
Section NavRepServer - NavRepClient";
CM_ SG_ 725 ACU_CompLogic_St "Object.CDCompLogic_St ";
CM_ SG_ 725 ACU_RadioError_St "Object Audio Management Audio Client.AudioError.RadioError";
CM_ SG_ 725 ACU_HardwareError_St "Object Audio Management Audio Client.AudioError.HardwareError";
CM_ SG_ 725 ACU_CurrentRadioBand_St "Object Tuner.CurrentRadioBand";
CM_ SG_ 725 ACU_CurrentPTYCode_St "Object Tuner.CurrentPTYCode

$0: Invalid
$1: PTY 1 (News)
..
$1F: PTY 31 (Alarm)";
CM_ SG_ 725 ACU_CurrentPICode_St "Object Tuner.CurrentPICode";
CM_ SG_ 725 ACU_CurrentFreq_St "Object Tuner.CurrentFreq

AM: Freq = 153+ Offset kHz.
Offset 0..1557 

FM: Freq = 76+ Offset*0.05 MHz. Offset 0..640
Selected tuned band determine frequency (kHz or MHz).";
CM_ SG_ 725 ACU_AFMode_St "Object Tuner.AFMode";
CM_ SG_ 548 DSP_ChimeChanState_St "Object BodyInterface.StdChimeIF.ChimeChannelState.St";
CM_ SG_ 548 DSP_Chime2_Not_Recgnizd "Object.ChimeAudioSource.DSP_Chime_Not_Recognized ";
CM_ SG_ 548 DSP_Chime_Not_Recgnizd "Object.ChimeAudioSource.DSP_Chime_Not_Recognized ";
CM_ SG_ 548 DSP_Alert_Channel3 "Object.AlertMethod.DSP_AMP_Alert

";
CM_ SG_ 548 DSP_Alert_Channel2 "Object.AlertMethod.DSP_AMP_Alert

";
CM_ SG_ 548 DSP_Alert_Channel1 "Object.AlertMethod.DSP_AMP_Alert

";
CM_ SG_ 548 DSP_Chimes_Supported "Object.AlertMethod.DSP_AMP_Alert

";
CM_ SG_ 548 DSP_AdjChimVolSupp_St "AdjustableChimeVolSupported2";
CM_ SG_ 548 DSP_AdjChimVolSupp2_St "AdjustableChimeVolSupported";
CM_ SG_ 404 Dsp_LangUpdate_Rsp "Object. LanguageUpdate.Rsp";
CM_ SG_ 689 AUDIO_MC_WORD_Tx "MM ISO 15765-2 Message Catalogue
Section Audio - MC";
BA_DEF_ BO_  "FrameRouting" STRING ;
BA_DEF_ BO_  "FrameGatewayNetwork" STRING ;
BA_DEF_ BO_  "NetworkInitialization" ENUM  "No","Yes";
BA_DEF_ BO_  "FrameGatewayId" HEX 0 1407;
BA_DEF_ BO_  "EventRateOfChange" INT 10 10000;
BA_DEF_ BO_  "GenMsgStartDelayTime" INT 0 10000;
BA_DEF_ BO_  "GenMsgNrOfRepetition" INT 0 100;
BA_DEF_ BO_  "GenMsgDelayTime" INT 0 1000;
BA_DEF_ BO_  "GenMsgCycleTime" INT 0 100000;
BA_DEF_ BO_  "GenMsgSendType" ENUM  "FixedPeriodic","Event","EnabledPeriodic","NotUsed","NotUsed","EventPeriodic","NotUsed","NotUsed","NoMsgSendType";
BA_DEF_ SG_  "U_U55X_MY2022_Tx" ENUM  "No","Yes";
BA_DEF_ SG_  "U_CD542_MY2021_Tx" ENUM  "No","Yes";
BA_DEF_ SG_  "ECGUsedTxSignal" ENUM  "No","Yes";
BA_DEF_ SG_  "U_T6_MCA_MY2020_Tx" ENUM  "No","Yes";
BA_DEF_ SG_  "U_P702_MY2021_Tx" ENUM  "No","Yes";
BA_DEF_ SG_  "U_CX727_MY2021_Tx" ENUM  "No","Yes";
BA_DEF_ SG_  "U_FNV2_IVI_Rx" ENUM  "No","Yes";
BA_DEF_ SG_  "U_U55X_MY2022_Rx" ENUM  "No","Yes";
BA_DEF_ SG_  "U_CD542_MY2021_Rx" ENUM  "No","Yes";
BA_DEF_ SG_  "ECGUsedRxSignal" ENUM  "No","Yes";
BA_DEF_ SG_  "U_T6_MCA_MY2020_Rx" ENUM  "No","Yes";
BA_DEF_ SG_  "U_P702_MY2021_Rx" ENUM  "No","Yes";
BA_DEF_ SG_  "U_CX727_MY2021_Rx" ENUM  "No","Yes";
BA_DEF_ SG_  "GenSigStartValue" HEX 0 268435455;
BA_DEF_ SG_  "MetaData" ENUM  "No","Yes";
BA_DEF_ SG_  "ContentDependant" ENUM  "No","Yes";
BA_DEF_ SG_  "GenSigStartValueInteger" INT 0 1000000000;
BA_DEF_ SG_  "UsedOnPgmDBC" ENUM  "No","Yes";
BA_DEF_ SG_  "WakeupSignal" ENUM  "No","Yes";
BA_DEF_ SG_  "GenSigInactiveValue" INT 0 100000;
BA_DEF_ SG_  "GenSigSendType" ENUM  "Cyclic","OnWrite","vector_leerstring","OnChange","vector_leerstring","IfActive","vector_leerstring","NoSigSendType";
BA_DEF_ BO_  "OvtpPushApplication" ENUM  "FALSE","TRUE";
BA_DEF_ BO_  "SCP_FreshnessValueLength" INT 0 512;
BA_DEF_ BO_  "SCP_FreshnessValueTxLength" INT 0 512;
BA_DEF_ BO_  "SCP_AuthInfoTxLength" INT 0 512;
BA_DEF_ BO_  "GenMsgRoutingTimeoutTime" INT 0 5000;
BA_DEF_ BO_  "MessageGateway" ENUM  "No","Yes";
BA_DEF_ BO_  "NmAsrMessage" ENUM  "No","Yes";
BA_DEF_ BO_  "DiagState" ENUM  "No","Yes";
BA_DEF_ BO_  "TpTxIndex" INT 0 536870911;
BA_DEF_ BO_  "DiagRequest" ENUM  "No","Yes";
BA_DEF_ BO_  "DiagResponse" ENUM  "No","Yes";
BA_DEF_ BO_  "GenMsgILSupport" ENUM  "No","Yes";
BA_DEF_DEF_  "FrameRouting" "";
BA_DEF_DEF_  "FrameGatewayNetwork" "NONE";
BA_DEF_DEF_  "NetworkInitialization" "Yes";
BA_DEF_DEF_  "FrameGatewayId" 0;
BA_DEF_DEF_  "EventRateOfChange" 10000;
BA_DEF_DEF_  "GenMsgStartDelayTime" 0;
BA_DEF_DEF_  "GenMsgNrOfRepetition" 1;
BA_DEF_DEF_  "GenMsgDelayTime" 20;
BA_DEF_DEF_  "GenMsgCycleTime" 0;
BA_DEF_DEF_  "GenMsgSendType" "NoMsgSendType";
BA_DEF_DEF_  "U_U55X_MY2022_Tx" "No";
BA_DEF_DEF_  "U_CD542_MY2021_Tx" "No";
BA_DEF_DEF_  "ECGUsedTxSignal" "No";
BA_DEF_DEF_  "U_T6_MCA_MY2020_Tx" "No";
BA_DEF_DEF_  "U_P702_MY2021_Tx" "No";
BA_DEF_DEF_  "U_CX727_MY2021_Tx" "No";
BA_DEF_DEF_  "U_FNV2_IVI_Rx" "No";
BA_DEF_DEF_  "U_U55X_MY2022_Rx" "No";
BA_DEF_DEF_  "U_CD542_MY2021_Rx" "No";
BA_DEF_DEF_  "ECGUsedRxSignal" "No";
BA_DEF_DEF_  "U_T6_MCA_MY2020_Rx" "No";
BA_DEF_DEF_  "U_P702_MY2021_Rx" "No";
BA_DEF_DEF_  "U_CX727_MY2021_Rx" "No";
BA_DEF_DEF_  "GenSigStartValue" 0;
BA_DEF_DEF_  "MetaData" "No";
BA_DEF_DEF_  "ContentDependant" "No";
BA_DEF_DEF_  "GenSigStartValueInteger" 0;
BA_DEF_DEF_  "UsedOnPgmDBC" "Yes";
BA_DEF_DEF_  "WakeupSignal" "No";
BA_DEF_DEF_  "GenSigInactiveValue" 0;
BA_DEF_DEF_  "GenSigSendType" "NoSigSendType";
BA_DEF_DEF_  "OvtpPushApplication" "FALSE";
BA_DEF_DEF_  "SCP_FreshnessValueLength" 64;
BA_DEF_DEF_  "SCP_FreshnessValueTxLength" 11;
BA_DEF_DEF_  "SCP_AuthInfoTxLength" 53;
BA_DEF_DEF_  "GenMsgRoutingTimeoutTime" 0;
BA_DEF_DEF_  "MessageGateway" "No";
BA_DEF_DEF_  "NmAsrMessage" "No";
BA_DEF_DEF_  "DiagState" "No";
BA_DEF_DEF_  "TpTxIndex" 0;
BA_DEF_DEF_  "DiagRequest" "No";
BA_DEF_DEF_  "DiagResponse" "No";
BA_DEF_DEF_  "GenMsgILSupport" "Yes";
BA_ "GenMsgCycleTime" BO_ 643 1000;
BA_ "GenMsgSendType" BO_ 643 5;
BA_ "GenMsgSendType" BO_ 145 1;
BA_ "TpTxIndex" BO_ 607 48;
BA_ "TpTxIndex" BO_ 598 47;
BA_ "TpTxIndex" BO_ 606 47;
BA_ "TpTxIndex" BO_ 597 46;
BA_ "TpTxIndex" BO_ 605 46;
BA_ "FrameRouting" BO_ 876 "MS1_CAN,0x36C;";
BA_ "FrameGatewayNetwork" BO_ 876 "MS1_CAN";
BA_ "FrameGatewayId" BO_ 876 876;
BA_ "FrameRouting" BO_ 875 "MS1_CAN,0x36B;";
BA_ "FrameGatewayNetwork" BO_ 875 "MS1_CAN";
BA_ "FrameGatewayId" BO_ 875 875;
BA_ "FrameRouting" BO_ 841 "MS1_CAN,0x349;";
BA_ "FrameGatewayNetwork" BO_ 841 "MS1_CAN";
BA_ "FrameGatewayId" BO_ 841 841;
BA_ "GenMsgCycleTime" BO_ 545 1000;
BA_ "GenMsgSendType" BO_ 545 5;
BA_ "GenMsgCycleTime" BO_ 1058 1000;
BA_ "GenMsgSendType" BO_ 1058 0;
BA_ "GenMsgCycleTime" BO_ 633 1000;
BA_ "GenMsgSendType" BO_ 633 5;
BA_ "GenMsgCycleTime" BO_ 936 1000;
BA_ "GenMsgSendType" BO_ 936 5;
BA_ "GenMsgRoutingTimeoutTime" BO_ 936 60;
BA_ "MessageGateway" BO_ 936 1;
BA_ "GenMsgStartDelayTime" BO_ 674 150;
BA_ "GenMsgDelayTime" BO_ 674 10;
BA_ "GenMsgCycleTime" BO_ 674 1000;
BA_ "GenMsgSendType" BO_ 674 5;
BA_ "GenMsgCycleTime" BO_ 75 1000;
BA_ "GenMsgSendType" BO_ 75 5;
BA_ "GenMsgRoutingTimeoutTime" BO_ 75 300;
BA_ "MessageGateway" BO_ 75 1;
BA_ "GenMsgCycleTime" BO_ 74 1000;
BA_ "GenMsgSendType" BO_ 74 5;
BA_ "GenMsgRoutingTimeoutTime" BO_ 74 300;
BA_ "MessageGateway" BO_ 74 1;
BA_ "FrameRouting" BO_ 780 "MS2_CAN,0x30C;";
BA_ "FrameGatewayNetwork" BO_ 780 "MS2_CAN";
BA_ "FrameGatewayId" BO_ 780 780;
BA_ "FrameRouting" BO_ 779 "MS2_CAN,0x30B;";
BA_ "FrameGatewayNetwork" BO_ 779 "MS2_CAN";
BA_ "FrameGatewayId" BO_ 779 779;
BA_ "GenMsgCycleTime" BO_ 783 1000;
BA_ "GenMsgSendType" BO_ 783 5;
BA_ "FrameRouting" BO_ 638 "HS4_CAN,0x27E";
BA_ "FrameGatewayNetwork" BO_ 638 "HS4_CAN";
BA_ "FrameGatewayId" BO_ 638 638;
BA_ "GenMsgCycleTime" BO_ 555 1000;
BA_ "GenMsgSendType" BO_ 555 5;
BA_ "FrameRouting" BO_ 124 "FD1_CAN,0x77;";
BA_ "FrameGatewayNetwork" BO_ 124 "FD1_CAN";
BA_ "FrameGatewayId" BO_ 124 119;
BA_ "GenMsgCycleTime" BO_ 736 1000;
BA_ "GenMsgSendType" BO_ 736 5;
BA_ "GenMsgCycleTime" BO_ 722 1000;
BA_ "GenMsgSendType" BO_ 722 5;
BA_ "GenMsgCycleTime" BO_ 721 1000;
BA_ "GenMsgSendType" BO_ 721 5;
BA_ "GenMsgCycleTime" BO_ 720 1000;
BA_ "GenMsgSendType" BO_ 720 5;
BA_ "GenMsgSendType" BO_ 470 1;
BA_ "NetworkInitialization" BO_ 1978 0;
BA_ "GenMsgDelayTime" BO_ 1978 0;
BA_ "GenMsgSendType" BO_ 1978 1;
BA_ "DiagResponse" BO_ 1978 1;
BA_ "GenMsgILSupport" BO_ 1978 0;
BA_ "NetworkInitialization" BO_ 1970 0;
BA_ "GenMsgDelayTime" BO_ 1970 0;
BA_ "GenMsgSendType" BO_ 1970 1;
BA_ "DiagRequest" BO_ 1970 1;
BA_ "GenMsgILSupport" BO_ 1970 0;
BA_ "GenMsgCycleTime" BO_ 758 1000;
BA_ "GenMsgSendType" BO_ 758 5;
BA_ "GenMsgCycleTime" BO_ 760 1000;
BA_ "GenMsgSendType" BO_ 760 5;
BA_ "TpTxIndex" BO_ 705 27;
BA_ "TpTxIndex" BO_ 692 15;
BA_ "NetworkInitialization" BO_ 1837 0;
BA_ "GenMsgDelayTime" BO_ 1837 0;
BA_ "GenMsgSendType" BO_ 1837 1;
BA_ "DiagResponse" BO_ 1837 1;
BA_ "GenMsgILSupport" BO_ 1837 0;
BA_ "GenMsgCycleTime" BO_ 523 1000;
BA_ "GenMsgSendType" BO_ 523 0;
BA_ "FrameRouting" BO_ 942 "FD1_CAN,0x3AE;";
BA_ "FrameGatewayNetwork" BO_ 942 "FD1_CAN";
BA_ "FrameGatewayId" BO_ 942 942;
BA_ "GenMsgCycleTime" BO_ 634 1000;
BA_ "GenMsgSendType" BO_ 634 5;
BA_ "FrameRouting" BO_ 1088 "FD1_CAN,0x440;HS1_CAN,0x440";
BA_ "TpTxIndex" BO_ 706 28;
BA_ "GenMsgCycleTime" BO_ 761 1000;
BA_ "GenMsgSendType" BO_ 761 5;
BA_ "TpTxIndex" BO_ 694 17;
BA_ "GenMsgCycleTime" BO_ 750 1000;
BA_ "GenMsgSendType" BO_ 750 5;
BA_ "TpTxIndex" BO_ 704 31;
BA_ "GenMsgCycleTime" BO_ 725 1000;
BA_ "GenMsgSendType" BO_ 725 5;
BA_ "GenMsgCycleTime" BO_ 1074 1000;
BA_ "GenMsgSendType" BO_ 1074 5;
BA_ "GenMsgCycleTime" BO_ 1014 1000;
BA_ "GenMsgSendType" BO_ 1014 5;
BA_ "GenMsgCycleTime" BO_ 548 1000;
BA_ "GenMsgSendType" BO_ 548 5;
BA_ "GenMsgSendType" BO_ 404 1;
BA_ "TpTxIndex" BO_ 689 12;
BA_ "U_T6_MCA_MY2020_Rx" SG_ 643 StrtInGearMsgTxt_D_Rq_UB 1;
BA_ "U_T6_MCA_MY2020_Rx" SG_ 643 StrtInGearMsgTxt_D_Rq 1;
BA_ "GenSigSendType" SG_ 643 StrtInGearMsgTxt_D_Rq 3;
BA_ "U_U55X_MY2022_Rx" SG_ 643 StabBarCnnct_D_Stat_UB 1;
BA_ "U_T6_MCA_MY2020_Rx" SG_ 643 StabBarCnnct_D_Stat_UB 1;
BA_ "U_U55X_MY2022_Rx" SG_ 643 StabBarCnnct_D_Stat 1;
BA_ "U_T6_MCA_MY2020_Rx" SG_ 643 StabBarCnnct_D_Stat 1;
BA_ "GenSigSendType" SG_ 643 StabBarCnnct_D_Stat 3;
BA_ "U_U55X_MY2022_Rx" SG_ 643 FstChrgCmplt_T_Est 1;
BA_ "U_CD542_MY2021_Rx" SG_ 643 FstChrgCmplt_T_Est 1;
BA_ "U_T6_MCA_MY2020_Rx" SG_ 643 FstChrgCmplt_T_Est 1;
BA_ "U_U55X_MY2022_Rx" SG_ 643 GearPos_D_Trg_UB 1;
BA_ "U_CD542_MY2021_Rx" SG_ 643 GearPos_D_Trg_UB 1;
BA_ "U_T6_MCA_MY2020_Rx" SG_ 643 GearPos_D_Trg_UB 1;
BA_ "U_U55X_MY2022_Rx" SG_ 643 GearPos_D_Trg 1;
BA_ "U_CD542_MY2021_Rx" SG_ 643 GearPos_D_Trg 1;
BA_ "U_T6_MCA_MY2020_Rx" SG_ 643 GearPos_D_Trg 1;
BA_ "GenSigSendType" SG_ 643 GearPos_D_Trg 3;
BA_ "GenSigStartValue" SG_ 643 GearPos_D_Trg 15;
BA_ "ContentDependant" SG_ 643 GearPos_D_Trg 1;
BA_ "GenSigStartValueInteger" SG_ 643 GearPos_D_Trg 15;
BA_ "U_U55X_MY2022_Rx" SG_ 643 PwTgateStepMsgTxt_B_Rq 1;
BA_ "U_T6_MCA_MY2020_Rx" SG_ 643 PwTgateStepMsgTxt_B_Rq 1;
BA_ "GenSigSendType" SG_ 643 PwTgateStepMsgTxt_B_Rq 3;
BA_ "U_U55X_MY2022_Rx" SG_ 643 PwTgateStepMsgTxt_B_Rq_UB 1;
BA_ "U_T6_MCA_MY2020_Rx" SG_ 643 PwTgateStepMsgTxt_B_Rq_UB 1;
BA_ "U_U55X_MY2022_Rx" SG_ 643 PwTgateMsgTxt_B_Rq_UB 1;
BA_ "U_T6_MCA_MY2020_Rx" SG_ 643 PwTgateMsgTxt_B_Rq_UB 1;
BA_ "U_U55X_MY2022_Rx" SG_ 643 PwTgateLamp_B_Rq_UB 1;
BA_ "U_T6_MCA_MY2020_Rx" SG_ 643 PwTgateLamp_B_Rq_UB 1;
BA_ "U_U55X_MY2022_Rx" SG_ 643 PwTgateMsgTxt_B_Rq 1;
BA_ "U_T6_MCA_MY2020_Rx" SG_ 643 PwTgateMsgTxt_B_Rq 1;
BA_ "GenSigSendType" SG_ 643 PwTgateMsgTxt_B_Rq 3;
BA_ "U_U55X_MY2022_Rx" SG_ 643 PwTgateLamp_B_Rq 1;
BA_ "U_T6_MCA_MY2020_Rx" SG_ 643 PwTgateLamp_B_Rq 1;
BA_ "GenSigSendType" SG_ 643 PwTgateLamp_B_Rq 3;
BA_ "U_CD542_MY2021_Rx" SG_ 643 PwRnngBoardSwtch_D_Stat_UB 1;
BA_ "U_U55X_MY2022_Rx" SG_ 643 PwRnngBoardSwtch_D_Stat_UB 1;
BA_ "U_T6_MCA_MY2020_Rx" SG_ 643 PwRnngBoardSwtch_D_Stat_UB 1;
BA_ "U_CD542_MY2021_Rx" SG_ 643 PwRnngBoardT_D_Stat_UB 1;
BA_ "U_U55X_MY2022_Rx" SG_ 643 PwRnngBoardT_D_Stat_UB 1;
BA_ "U_T6_MCA_MY2020_Rx" SG_ 643 PwRnngBoardT_D_Stat_UB 1;
BA_ "U_CD542_MY2021_Rx" SG_ 643 PwRnngBoardT_D_Stat 1;
BA_ "U_U55X_MY2022_Rx" SG_ 643 PwRnngBoardT_D_Stat 1;
BA_ "U_T6_MCA_MY2020_Rx" SG_ 643 PwRnngBoardT_D_Stat 1;
BA_ "GenSigSendType" SG_ 643 PwRnngBoardT_D_Stat 3;
BA_ "U_U55X_MY2022_Rx" SG_ 643 PwRnngBoardSwtch_D_Stat 1;
BA_ "U_CD542_MY2021_Rx" SG_ 643 PwRnngBoardSwtch_D_Stat 1;
BA_ "U_T6_MCA_MY2020_Rx" SG_ 643 PwRnngBoardSwtch_D_Stat 1;
BA_ "GenSigSendType" SG_ 643 PwRnngBoardSwtch_D_Stat 3;
BA_ "U_T6_MCA_MY2020_Rx" SG_ 643 OnePdlDrvLamp_B_Rq_UB 1;
BA_ "U_T6_MCA_MY2020_Rx" SG_ 643 OnePdlDrv_D_Dsply_UB 1;
BA_ "U_U55X_MY2022_Rx" SG_ 643 OnePdlDrv_D_Dsply_UB 1;
BA_ "U_CD542_MY2021_Rx" SG_ 643 OnePdlDrv_D_Dsply_UB 1;
BA_ "U_T6_MCA_MY2020_Rx" SG_ 643 OnePdlDrvLamp_B_Rq 1;
BA_ "GenSigSendType" SG_ 643 OnePdlDrvLamp_B_Rq 3;
BA_ "U_T6_MCA_MY2020_Rx" SG_ 643 OnePdlDrv_D_Dsply 1;
BA_ "U_U55X_MY2022_Rx" SG_ 643 OnePdlDrv_D_Dsply 1;
BA_ "U_CD542_MY2021_Rx" SG_ 643 OnePdlDrv_D_Dsply 1;
BA_ "GenSigSendType" SG_ 643 OnePdlDrv_D_Dsply 3;
BA_ "GenSigSendType" SG_ 643 SeatSlprPosMsgTxt_B_Rq 3;
BA_ "U_T6_MCA_MY2020_Rx" SG_ 643 DrPrsntRearPsngr_D_Stat_UB 1;
BA_ "U_T6_MCA_MY2020_Rx" SG_ 643 DrPsngrMsgTxt_B_Rq_UB 1;
BA_ "U_T6_MCA_MY2020_Rx" SG_ 643 DrPsngrMsgTxt_B_Rq 1;
BA_ "GenSigSendType" SG_ 643 DrPsngrMsgTxt_B_Rq 3;
BA_ "U_T6_MCA_MY2020_Rx" SG_ 643 DrPrsntRearPsngr_D_Stat 1;
BA_ "GenSigSendType" SG_ 643 DrPrsntRearPsngr_D_Stat 3;
BA_ "WakeupSignal" SG_ 643 DrPrsntRearPsngr_D_Stat 1;
BA_ "GenSigSendType" SG_ 643 DrPrsntPsngr_D_Stat 3;
BA_ "WakeupSignal" SG_ 643 DrPrsntPsngr_D_Stat 1;
BA_ "U_T6_MCA_MY2020_Rx" SG_ 643 DrPrsntRearDrv_D_Stat_UB 1;
BA_ "U_T6_MCA_MY2020_Rx" SG_ 643 DrDrvMsgTxt_B_Rq_UB 1;
BA_ "U_T6_MCA_MY2020_Rx" SG_ 643 DrPrsntDrv_D_Stat_UB 1;
BA_ "U_T6_MCA_MY2020_Rx" SG_ 643 DrPrsntDrv_D_Stat 1;
BA_ "GenSigSendType" SG_ 643 DrPrsntDrv_D_Stat 3;
BA_ "WakeupSignal" SG_ 643 DrPrsntDrv_D_Stat 1;
BA_ "U_T6_MCA_MY2020_Rx" SG_ 643 DrPrsntRearDrv_D_Stat 1;
BA_ "GenSigSendType" SG_ 643 DrPrsntRearDrv_D_Stat 3;
BA_ "WakeupSignal" SG_ 643 DrPrsntRearDrv_D_Stat 1;
BA_ "U_T6_MCA_MY2020_Rx" SG_ 643 DrDrvMsgTxt_B_Rq 1;
BA_ "GenSigSendType" SG_ 643 DrDrvMsgTxt_B_Rq 3;
BA_ "U_U55X_MY2022_Rx" SG_ 643 FstChrgCmplt_T_Est_UB 1;
BA_ "U_CD542_MY2021_Rx" SG_ 643 FstChrgCmplt_T_Est_UB 1;
BA_ "U_T6_MCA_MY2020_Rx" SG_ 643 FstChrgCmplt_T_Est_UB 1;
BA_ "U_U55X_MY2022_Rx" SG_ 643 TrunkFrontOpen_D_Stat_UB 1;
BA_ "U_CD542_MY2021_Rx" SG_ 643 TrunkFrontOpen_D_Stat_UB 1;
BA_ "U_T6_MCA_MY2020_Rx" SG_ 643 TrunkFrontOpen_D_Stat_UB 1;
BA_ "U_U55X_MY2022_Rx" SG_ 643 TrunkFrontOpen_D_Stat 1;
BA_ "U_CD542_MY2021_Rx" SG_ 643 TrunkFrontOpen_D_Stat 1;
BA_ "U_T6_MCA_MY2020_Rx" SG_ 643 TrunkFrontOpen_D_Stat 1;
BA_ "GenSigSendType" SG_ 643 TrunkFrontOpen_D_Stat 3;
BA_ "GenSigStartValue" SG_ 643 TrunkFrontOpen_D_Stat 2;
BA_ "WakeupSignal" SG_ 643 TrunkFrontOpen_D_Stat 1;
BA_ "U_U55X_MY2022_Tx" SG_ 145 MFD_Year 1;
BA_ "U_CD542_MY2021_Tx" SG_ 145 MFD_Year 1;
BA_ "U_T6_MCA_MY2020_Tx" SG_ 145 MFD_Year 1;
BA_ "U_T6_MCA_MY2020_Rx" SG_ 145 MFD_Year 1;
BA_ "U_U55X_MY2022_Rx" SG_ 145 MFD_Year 1;
BA_ "U_U55X_MY2022_Tx" SG_ 145 MFD_Second 1;
BA_ "U_CD542_MY2021_Tx" SG_ 145 MFD_Second 1;
BA_ "U_T6_MCA_MY2020_Tx" SG_ 145 MFD_Second 1;
BA_ "U_T6_MCA_MY2020_Rx" SG_ 145 MFD_Second 1;
BA_ "U_U55X_MY2022_Rx" SG_ 145 MFD_Second 1;
BA_ "GenSigSendType" SG_ 145 MFD_Second 3;
BA_ "U_U55X_MY2022_Tx" SG_ 145 MFD_Month 1;
BA_ "U_CD542_MY2021_Tx" SG_ 145 MFD_Month 1;
BA_ "U_T6_MCA_MY2020_Tx" SG_ 145 MFD_Month 1;
BA_ "U_T6_MCA_MY2020_Rx" SG_ 145 MFD_Month 1;
BA_ "U_U55X_MY2022_Rx" SG_ 145 MFD_Month 1;
BA_ "U_U55X_MY2022_Tx" SG_ 145 MFD_Minute 1;
BA_ "U_CD542_MY2021_Tx" SG_ 145 MFD_Minute 1;
BA_ "U_T6_MCA_MY2020_Tx" SG_ 145 MFD_Minute 1;
BA_ "U_T6_MCA_MY2020_Rx" SG_ 145 MFD_Minute 1;
BA_ "U_U55X_MY2022_Rx" SG_ 145 MFD_Minute 1;
BA_ "U_U55X_MY2022_Tx" SG_ 145 MFD_Hour 1;
BA_ "U_CD542_MY2021_Tx" SG_ 145 MFD_Hour 1;
BA_ "U_T6_MCA_MY2020_Tx" SG_ 145 MFD_Hour 1;
BA_ "U_T6_MCA_MY2020_Rx" SG_ 145 MFD_Hour 1;
BA_ "U_U55X_MY2022_Rx" SG_ 145 MFD_Hour 1;
BA_ "U_U55X_MY2022_Tx" SG_ 145 MFD_Day 1;
BA_ "U_CD542_MY2021_Tx" SG_ 145 MFD_Day 1;
BA_ "U_T6_MCA_MY2020_Tx" SG_ 145 MFD_Day 1;
BA_ "U_T6_MCA_MY2020_Rx" SG_ 145 MFD_Day 1;
BA_ "U_U55X_MY2022_Rx" SG_ 145 MFD_Day 1;
BA_ "U_U55X_MY2022_Tx" SG_ 607 RDRV_RSE_WORD_Rx 1;
BA_ "U_U55X_MY2022_Tx" SG_ 598 CONMP_RSE_WORD_Tx 1;
BA_ "U_CD542_MY2021_Tx" SG_ 598 CONMP_RSE_WORD_Tx 1;
BA_ "U_T6_MCA_MY2020_Tx" SG_ 598 CONMP_RSE_WORD_Tx 1;
BA_ "U_U55X_MY2022_Rx" SG_ 598 CONMP_RSE_WORD_Tx 1;
BA_ "U_U55X_MY2022_Tx" SG_ 606 CONMP_RSE_WORD_Rx 1;
BA_ "U_U55X_MY2022_Rx" SG_ 606 CONMP_RSE_WORD_Rx 1;
BA_ "U_CD542_MY2021_Rx" SG_ 606 CONMP_RSE_WORD_Rx 1;
BA_ "U_T6_MCA_MY2020_Rx" SG_ 606 CONMP_RSE_WORD_Rx 1;
BA_ "U_U55X_MY2022_Tx" SG_ 597 AUDIO_RSE_WORD_Tx 1;
BA_ "U_T6_MCA_MY2020_Tx" SG_ 597 AUDIO_RSE_WORD_Tx 1;
BA_ "U_U55X_MY2022_Rx" SG_ 597 AUDIO_RSE_WORD_Tx 1;
BA_ "U_U55X_MY2022_Tx" SG_ 605 AUDIO_RSE_WORD_Rx 1;
BA_ "U_U55X_MY2022_Rx" SG_ 605 AUDIO_RSE_WORD_Rx 1;
BA_ "U_U55X_MY2022_Rx" SG_ 876 SeatSwtchRr_B_Stat 1;
BA_ "U_U55X_MY2022_Rx" SG_ 876 SeatPRr_B_Stat 1;
BA_ "U_U55X_MY2022_Rx" SG_ 876 SeatLmbrUpRr_Pc_Actl 1;
BA_ "GenSigStartValue" SG_ 876 SeatLmbrUpRr_Pc_Actl 127;
BA_ "GenSigStartValueInteger" SG_ 876 SeatLmbrUpRr_Pc_Actl 127;
BA_ "U_U55X_MY2022_Rx" SG_ 876 SeatLmbrMidRr_Pc_Actl 1;
BA_ "GenSigStartValue" SG_ 876 SeatLmbrMidRr_Pc_Actl 127;
BA_ "GenSigStartValueInteger" SG_ 876 SeatLmbrMidRr_Pc_Actl 127;
BA_ "U_U55X_MY2022_Rx" SG_ 876 SeatLmbrLoRr_Pc_Actl 1;
BA_ "GenSigStartValue" SG_ 876 SeatLmbrLoRr_Pc_Actl 127;
BA_ "GenSigStartValueInteger" SG_ 876 SeatLmbrLoRr_Pc_Actl 127;
BA_ "U_U55X_MY2022_Rx" SG_ 876 SeatFnRr_D_Stat 1;
BA_ "U_U55X_MY2022_Rx" SG_ 876 StmsCshnPsgr_D_Stat2 1;
BA_ "U_U55X_MY2022_Rx" SG_ 876 StmsLmbrPsgr_D_Stat2 1;
BA_ "U_U55X_MY2022_Rx" SG_ 875 SeatSwtchRl_B_Stat 1;
BA_ "U_U55X_MY2022_Rx" SG_ 875 SeatPRl_B_Stat 1;
BA_ "U_U55X_MY2022_Rx" SG_ 875 SeatLmbrUpRl_Pc_Actl 1;
BA_ "GenSigStartValue" SG_ 875 SeatLmbrUpRl_Pc_Actl 127;
BA_ "GenSigStartValueInteger" SG_ 875 SeatLmbrUpRl_Pc_Actl 127;
BA_ "U_U55X_MY2022_Rx" SG_ 875 SeatLmbrMidRl_Pc_Actl 1;
BA_ "GenSigStartValue" SG_ 875 SeatLmbrMidRl_Pc_Actl 127;
BA_ "GenSigStartValueInteger" SG_ 875 SeatLmbrMidRl_Pc_Actl 127;
BA_ "U_U55X_MY2022_Rx" SG_ 875 SeatLmbrLoRl_Pc_Actl 1;
BA_ "GenSigStartValue" SG_ 875 SeatLmbrLoRl_Pc_Actl 127;
BA_ "GenSigStartValueInteger" SG_ 875 SeatLmbrLoRl_Pc_Actl 127;
BA_ "U_U55X_MY2022_Rx" SG_ 875 SeatFnRl_D_Stat 1;
BA_ "U_U55X_MY2022_Rx" SG_ 875 StmsLmbrDrv_D_Stat2 1;
BA_ "U_U55X_MY2022_Rx" SG_ 875 StmsCshnDrv_D_Stat2 1;
BA_ "U_U55X_MY2022_Rx" SG_ 875 SeatAirAmb_P_Actl2 1;
BA_ "U_T6_MCA_MY2020_Rx" SG_ 841 FohStrtDateDay_No_Stat 1;
BA_ "U_T6_MCA_MY2020_Rx" SG_ 841 FohStrtDateYr_No_Stat 1;
BA_ "U_T6_MCA_MY2020_Rx" SG_ 841 FohAddHeater_D_Stat 1;
BA_ "U_U55X_MY2022_Tx" SG_ 545 SpkrDgtlRight_D_Stat 1;
BA_ "U_CD542_MY2021_Tx" SG_ 545 SpkrDgtlRight_D_Stat 1;
BA_ "U_T6_MCA_MY2020_Tx" SG_ 545 SpkrDgtlRight_D_Stat 1;
BA_ "U_P702_MY2021_Tx" SG_ 545 SpkrDgtlRight_D_Stat 1;
BA_ "GenSigSendType" SG_ 545 SpkrDgtlRight_D_Stat 3;
BA_ "U_U55X_MY2022_Tx" SG_ 545 SpkrDgtlLeft_D_Stat 1;
BA_ "U_CD542_MY2021_Tx" SG_ 545 SpkrDgtlLeft_D_Stat 1;
BA_ "U_T6_MCA_MY2020_Tx" SG_ 545 SpkrDgtlLeft_D_Stat 1;
BA_ "U_P702_MY2021_Tx" SG_ 545 SpkrDgtlLeft_D_Stat 1;
BA_ "GenSigSendType" SG_ 545 SpkrDgtlLeft_D_Stat 3;
BA_ "U_U55X_MY2022_Tx" SG_ 545 SpkrDgtlCntr_D_Stat 1;
BA_ "U_CD542_MY2021_Tx" SG_ 545 SpkrDgtlCntr_D_Stat 1;
BA_ "U_T6_MCA_MY2020_Tx" SG_ 545 SpkrDgtlCntr_D_Stat 1;
BA_ "U_P702_MY2021_Tx" SG_ 545 SpkrDgtlCntr_D_Stat 1;
BA_ "U_T6_MCA_MY2020_Rx" SG_ 545 SpkrDgtlCntr_D_Stat 1;
BA_ "GenSigSendType" SG_ 545 SpkrDgtlCntr_D_Stat 3;
BA_ "U_U55X_MY2022_Tx" SG_ 545 SurndSndUpmix2_D_Stat 1;
BA_ "U_CD542_MY2021_Tx" SG_ 545 SurndSndUpmix2_D_Stat 1;
BA_ "U_T6_MCA_MY2020_Tx" SG_ 545 SurndSndUpmix2_D_Stat 1;
BA_ "U_P702_MY2021_Tx" SG_ 545 SurndSndUpmix2_D_Stat 1;
BA_ "U_U55X_MY2022_Rx" SG_ 545 SurndSndUpmix2_D_Stat 1;
BA_ "U_CD542_MY2021_Rx" SG_ 545 SurndSndUpmix2_D_Stat 1;
BA_ "U_T6_MCA_MY2020_Rx" SG_ 545 SurndSndUpmix2_D_Stat 1;
BA_ "U_P702_MY2021_Rx" SG_ 545 SurndSndUpmix2_D_Stat 1;
BA_ "GenSigSendType" SG_ 545 SurndSndUpmix2_D_Stat 3;
BA_ "U_U55X_MY2022_Tx" SG_ 545 DSP_Bezel_Diag_St 1;
BA_ "U_CD542_MY2021_Tx" SG_ 545 DSP_Bezel_Diag_St 1;
BA_ "U_T6_MCA_MY2020_Tx" SG_ 545 DSP_Bezel_Diag_St 1;
BA_ "U_U55X_MY2022_Rx" SG_ 545 DSP_Bezel_Diag_St 1;
BA_ "U_CD542_MY2021_Rx" SG_ 545 DSP_Bezel_Diag_St 1;
BA_ "U_T6_MCA_MY2020_Rx" SG_ 545 DSP_Bezel_Diag_St 1;
BA_ "U_P702_MY2021_Rx" SG_ 545 DSP_Bezel_Diag_St 1;
BA_ "GenSigSendType" SG_ 545 DSP_Bezel_Diag_St 3;
BA_ "U_U55X_MY2022_Tx" SG_ 545 SndImmrsnLvl_D_Stat 1;
BA_ "U_CD542_MY2021_Tx" SG_ 545 SndImmrsnLvl_D_Stat 1;
BA_ "U_T6_MCA_MY2020_Tx" SG_ 545 SndImmrsnLvl_D_Stat 1;
BA_ "U_P702_MY2021_Tx" SG_ 545 SndImmrsnLvl_D_Stat 1;
BA_ "U_U55X_MY2022_Rx" SG_ 545 SndImmrsnLvl_D_Stat 1;
BA_ "U_CD542_MY2021_Rx" SG_ 545 SndImmrsnLvl_D_Stat 1;
BA_ "U_T6_MCA_MY2020_Rx" SG_ 545 SndImmrsnLvl_D_Stat 1;
BA_ "U_P702_MY2021_Rx" SG_ 545 SndImmrsnLvl_D_Stat 1;
BA_ "GenSigSendType" SG_ 545 SndImmrsnLvl_D_Stat 3;
BA_ "U_U55X_MY2022_Tx" SG_ 545 DSP_Sur_Sound_st 1;
BA_ "U_CD542_MY2021_Tx" SG_ 545 DSP_Sur_Sound_st 1;
BA_ "U_T6_MCA_MY2020_Tx" SG_ 545 DSP_Sur_Sound_st 1;
BA_ "U_P702_MY2021_Tx" SG_ 545 DSP_Sur_Sound_st 1;
BA_ "U_U55X_MY2022_Rx" SG_ 545 DSP_Sur_Sound_st 1;
BA_ "U_CD542_MY2021_Rx" SG_ 545 DSP_Sur_Sound_st 1;
BA_ "U_T6_MCA_MY2020_Rx" SG_ 545 DSP_Sur_Sound_st 1;
BA_ "U_P702_MY2021_Rx" SG_ 545 DSP_Sur_Sound_st 1;
BA_ "GenSigSendType" SG_ 545 DSP_Sur_Sound_st 3;
BA_ "U_U55X_MY2022_Tx" SG_ 545 DSP_MyKeyVolLimitUp_St 1;
BA_ "U_CD542_MY2021_Tx" SG_ 545 DSP_MyKeyVolLimitUp_St 1;
BA_ "U_T6_MCA_MY2020_Tx" SG_ 545 DSP_MyKeyVolLimitUp_St 1;
BA_ "U_P702_MY2021_Tx" SG_ 545 DSP_MyKeyVolLimitUp_St 1;
BA_ "U_U55X_MY2022_Rx" SG_ 545 DSP_MyKeyVolLimitUp_St 1;
BA_ "U_CD542_MY2021_Rx" SG_ 545 DSP_MyKeyVolLimitUp_St 1;
BA_ "U_T6_MCA_MY2020_Rx" SG_ 545 DSP_MyKeyVolLimitUp_St 1;
BA_ "U_P702_MY2021_Rx" SG_ 545 DSP_MyKeyVolLimitUp_St 1;
BA_ "GenSigSendType" SG_ 545 DSP_MyKeyVolLimitUp_St 3;
BA_ "U_U55X_MY2022_Tx" SG_ 545 DSP_MyKeyVolLim_St 1;
BA_ "U_CD542_MY2021_Tx" SG_ 545 DSP_MyKeyVolLim_St 1;
BA_ "U_T6_MCA_MY2020_Tx" SG_ 545 DSP_MyKeyVolLim_St 1;
BA_ "U_P702_MY2021_Tx" SG_ 545 DSP_MyKeyVolLim_St 1;
BA_ "U_U55X_MY2022_Rx" SG_ 545 DSP_MyKeyVolLim_St 1;
BA_ "U_CD542_MY2021_Rx" SG_ 545 DSP_MyKeyVolLim_St 1;
BA_ "U_T6_MCA_MY2020_Rx" SG_ 545 DSP_MyKeyVolLim_St 1;
BA_ "U_P702_MY2021_Rx" SG_ 545 DSP_MyKeyVolLim_St 1;
BA_ "GenSigSendType" SG_ 545 DSP_MyKeyVolLim_St 3;
BA_ "U_U55X_MY2022_Tx" SG_ 545 DSP_BeltminderAudio_St 1;
BA_ "U_CD542_MY2021_Tx" SG_ 545 DSP_BeltminderAudio_St 1;
BA_ "U_T6_MCA_MY2020_Tx" SG_ 545 DSP_BeltminderAudio_St 1;
BA_ "U_P702_MY2021_Tx" SG_ 545 DSP_BeltminderAudio_St 1;
BA_ "U_U55X_MY2022_Rx" SG_ 545 DSP_BeltminderAudio_St 1;
BA_ "U_CD542_MY2021_Rx" SG_ 545 DSP_BeltminderAudio_St 1;
BA_ "U_T6_MCA_MY2020_Rx" SG_ 545 DSP_BeltminderAudio_St 1;
BA_ "U_P702_MY2021_Rx" SG_ 545 DSP_BeltminderAudio_St 1;
BA_ "GenSigSendType" SG_ 545 DSP_BeltminderAudio_St 3;
BA_ "U_U55X_MY2022_Tx" SG_ 545 DSP_Audio_Volume_Up_St 1;
BA_ "U_CD542_MY2021_Tx" SG_ 545 DSP_Audio_Volume_Up_St 1;
BA_ "U_T6_MCA_MY2020_Tx" SG_ 545 DSP_Audio_Volume_Up_St 1;
BA_ "U_P702_MY2021_Tx" SG_ 545 DSP_Audio_Volume_Up_St 1;
BA_ "ECGUsedRxSignal" SG_ 545 DSP_Audio_Volume_Up_St 1;
BA_ "U_CD542_MY2021_Rx" SG_ 545 DSP_Audio_Volume_Up_St 1;
BA_ "U_P702_MY2021_Rx" SG_ 545 DSP_Audio_Volume_Up_St 1;
BA_ "U_U55X_MY2022_Rx" SG_ 545 DSP_Audio_Volume_Up_St 1;
BA_ "U_T6_MCA_MY2020_Rx" SG_ 545 DSP_Audio_Volume_Up_St 1;
BA_ "GenSigSendType" SG_ 545 DSP_Audio_Volume_Up_St 3;
BA_ "U_U55X_MY2022_Tx" SG_ 545 DSP_Audio_Vol_Level_St 1;
BA_ "U_CD542_MY2021_Tx" SG_ 545 DSP_Audio_Vol_Level_St 1;
BA_ "U_T6_MCA_MY2020_Tx" SG_ 545 DSP_Audio_Vol_Level_St 1;
BA_ "U_P702_MY2021_Tx" SG_ 545 DSP_Audio_Vol_Level_St 1;
BA_ "U_CD542_MY2021_Rx" SG_ 545 DSP_Audio_Vol_Level_St 1;
BA_ "U_P702_MY2021_Rx" SG_ 545 DSP_Audio_Vol_Level_St 1;
BA_ "U_U55X_MY2022_Rx" SG_ 545 DSP_Audio_Vol_Level_St 1;
BA_ "U_T6_MCA_MY2020_Rx" SG_ 545 DSP_Audio_Vol_Level_St 1;
BA_ "GenSigSendType" SG_ 545 DSP_Audio_Vol_Level_St 3;
BA_ "U_CD542_MY2021_Tx" SG_ 545 AutoConfigOcc_Rear 1;
BA_ "U_U55X_MY2022_Rx" SG_ 545 AutoConfigOcc_Rear 1;
BA_ "U_CD542_MY2021_Rx" SG_ 545 AutoConfigOcc_Rear 1;
BA_ "U_T6_MCA_MY2020_Rx" SG_ 545 AutoConfigOcc_Rear 1;
BA_ "GenSigSendType" SG_ 545 AutoConfigOcc_Rear 3;
BA_ "U_CD542_MY2021_Tx" SG_ 545 AutoConfigOcc_Front 1;
BA_ "U_U55X_MY2022_Rx" SG_ 545 AutoConfigOcc_Front 1;
BA_ "U_CD542_MY2021_Rx" SG_ 545 AutoConfigOcc_Front 1;
BA_ "U_T6_MCA_MY2020_Rx" SG_ 545 AutoConfigOcc_Front 1;
BA_ "GenSigSendType" SG_ 545 AutoConfigOcc_Front 3;
BA_ "U_CD542_MY2021_Tx" SG_ 545 AutoConfigOcc_Driver 1;
BA_ "U_U55X_MY2022_Rx" SG_ 545 AutoConfigOcc_Driver 1;
BA_ "U_CD542_MY2021_Rx" SG_ 545 AutoConfigOcc_Driver 1;
BA_ "U_T6_MCA_MY2020_Rx" SG_ 545 AutoConfigOcc_Driver 1;
BA_ "GenSigSendType" SG_ 545 AutoConfigOcc_Driver 3;
BA_ "U_CD542_MY2021_Tx" SG_ 545 AutoConfigOcc_AllSeats 1;
BA_ "U_U55X_MY2022_Rx" SG_ 545 AutoConfigOcc_AllSeats 1;
BA_ "U_CD542_MY2021_Rx" SG_ 545 AutoConfigOcc_AllSeats 1;
BA_ "U_T6_MCA_MY2020_Rx" SG_ 545 AutoConfigOcc_AllSeats 1;
BA_ "GenSigSendType" SG_ 545 AutoConfigOcc_AllSeats 3;
BA_ "U_U55X_MY2022_Tx" SG_ 545 AudioOccMde_D_Stat 1;
BA_ "U_CD542_MY2021_Tx" SG_ 545 AudioOccMde_D_Stat 1;
BA_ "U_T6_MCA_MY2020_Tx" SG_ 545 AudioOccMde_D_Stat 1;
BA_ "U_U55X_MY2022_Rx" SG_ 545 AudioOccMde_D_Stat 1;
BA_ "U_CD542_MY2021_Rx" SG_ 545 AudioOccMde_D_Stat 1;
BA_ "U_T6_MCA_MY2020_Rx" SG_ 545 AudioOccMde_D_Stat 1;
BA_ "GenSigSendType" SG_ 545 AudioOccMde_D_Stat 3;
BA_ "U_CD542_MY2021_Rx" SG_ 1058 StopStrtVThres_D_Stat_UB 1;
BA_ "U_T6_MCA_MY2020_Rx" SG_ 1058 StopStrtVThres_D_Stat_UB 1;
BA_ "U_CD542_MY2021_Rx" SG_ 1058 StopStrtVThres_D_Stat 1;
BA_ "U_T6_MCA_MY2020_Rx" SG_ 1058 StopStrtVThres_D_Stat 1;
BA_ "GenSigSendType" SG_ 1058 StopStrtVThres_D_Stat 3;
BA_ "GenSigStartValue" SG_ 1058 StopStrtVThres_D_Stat 1;
BA_ "GenSigStartValueInteger" SG_ 1058 StopStrtVThres_D_Stat 1;
BA_ "U_CD542_MY2021_Rx" SG_ 1058 ChrgPortDrOpen_B_Stat 1;
BA_ "U_T6_MCA_MY2020_Rx" SG_ 1058 ChrgPortDrOpen_B_Stat 1;
BA_ "GenSigSendType" SG_ 1058 ChrgPortDrOpen_B_Stat 3;
BA_ "U_CD542_MY2021_Rx" SG_ 1058 ChrgPortDrOpen_B_Stat_UB 1;
BA_ "U_T6_MCA_MY2020_Rx" SG_ 1058 ChrgPortDrOpen_B_Stat_UB 1;
BA_ "U_T6_MCA_MY2020_Rx" SG_ 633 RearDiffLckMsg2_D_Rq_UB 1;
BA_ "U_T6_MCA_MY2020_Rx" SG_ 633 RearDiffLckMsg2_D_Rq 1;
BA_ "GenSigSendType" SG_ 633 RearDiffLckMsg2_D_Rq 3;
BA_ "U_U55X_MY2022_Rx" SG_ 633 PwStepMsgTxt_D_Rq_UB 1;
BA_ "U_T6_MCA_MY2020_Rx" SG_ 633 PwStepMsgTxt_D_Rq_UB 1;
BA_ "U_U55X_MY2022_Rx" SG_ 633 PwStepMsgTxt_D_Rq 1;
BA_ "U_T6_MCA_MY2020_Rx" SG_ 633 PwStepMsgTxt_D_Rq 1;
BA_ "GenSigSendType" SG_ 633 PwStepMsgTxt_D_Rq 3;
BA_ "U_T6_MCA_MY2020_Rx" SG_ 633 RearDiffLck_D_RqDrv 1;
BA_ "GenSigSendType" SG_ 633 RearDiffLck_D_RqDrv 3;
BA_ "GenSigStartValue" SG_ 633 RearDiffLck_D_RqDrv 2;
BA_ "GenSigStartValueInteger" SG_ 633 RearDiffLck_D_RqDrv 2;
BA_ "U_T6_MCA_MY2020_Rx" SG_ 633 AwdMde_D_RqDrv 1;
BA_ "GenSigSendType" SG_ 633 AwdMde_D_RqDrv 3;
BA_ "GenSigStartValue" SG_ 633 AwdMde_D_RqDrv 5;
BA_ "GenSigStartValueInteger" SG_ 633 AwdMde_D_RqDrv 5;
BA_ "U_T6_MCA_MY2020_Rx" SG_ 633 RearDiffLck_D_RqDrv_UB 1;
BA_ "U_U55X_MY2022_Rx" SG_ 633 TsrRegionTxt_D_Stat_UB 1;
BA_ "U_T6_MCA_MY2020_Rx" SG_ 633 TsrRegionTxt_D_Stat_UB 1;
BA_ "U_T6_MCA_MY2020_Rx" SG_ 633 AwdMde_D_RqDrv_UB 1;
BA_ "U_U55X_MY2022_Rx" SG_ 633 TsrRegionTxt_D_Stat 1;
BA_ "U_T6_MCA_MY2020_Rx" SG_ 633 TsrRegionTxt_D_Stat 1;
BA_ "GenSigSendType" SG_ 633 TsrRegionTxt_D_Stat 3;
BA_ "U_U55X_MY2022_Rx" SG_ 633 GsmGearMsgTxt_D_Rq_UB 1;
BA_ "U_CD542_MY2021_Rx" SG_ 633 GsmGearMsgTxt_D_Rq_UB 1;
BA_ "U_T6_MCA_MY2020_Rx" SG_ 633 GsmGearMsgTxt_D_Rq_UB 1;
BA_ "U_P702_MY2021_Rx" SG_ 633 GsmGearMsgTxt_D_Rq_UB 1;
BA_ "U_U55X_MY2022_Rx" SG_ 633 GsmGearMsgTxt_D_Rq 1;
BA_ "U_CD542_MY2021_Rx" SG_ 633 GsmGearMsgTxt_D_Rq 1;
BA_ "U_T6_MCA_MY2020_Rx" SG_ 633 GsmGearMsgTxt_D_Rq 1;
BA_ "U_P702_MY2021_Rx" SG_ 633 GsmGearMsgTxt_D_Rq 1;
BA_ "GenSigSendType" SG_ 633 GsmGearMsgTxt_D_Rq 3;
BA_ "U_T6_MCA_MY2020_Rx" SG_ 633 RearDiffLckLamp_D_Rq2_UB 1;
BA_ "U_T6_MCA_MY2020_Rx" SG_ 633 RearDiffLckLamp_D_Rq2 1;
BA_ "GenSigSendType" SG_ 633 RearDiffLckLamp_D_Rq2 3;
BA_ "U_U55X_MY2022_Rx" SG_ 633 DasAlrtInfo_D_Dsply_UB 1;
BA_ "U_CD542_MY2021_Rx" SG_ 633 DasAlrtInfo_D_Dsply_UB 1;
BA_ "U_T6_MCA_MY2020_Rx" SG_ 633 DasAlrtInfo_D_Dsply_UB 1;
BA_ "U_P702_MY2021_Rx" SG_ 633 DasAlrtInfo_D_Dsply_UB 1;
BA_ "U_U55X_MY2022_Rx" SG_ 633 DasAlrtInfo_D_Dsply 1;
BA_ "U_CD542_MY2021_Rx" SG_ 633 DasAlrtInfo_D_Dsply 1;
BA_ "U_T6_MCA_MY2020_Rx" SG_ 633 DasAlrtInfo_D_Dsply 1;
BA_ "U_P702_MY2021_Rx" SG_ 633 DasAlrtInfo_D_Dsply 1;
BA_ "GenSigSendType" SG_ 633 DasAlrtInfo_D_Dsply 3;
BA_ "U_U55X_MY2022_Rx" SG_ 633 Shed_Feature_Group_ID_UB 1;
BA_ "U_T6_MCA_MY2020_Rx" SG_ 633 Shed_Feature_Group_ID_UB 1;
BA_ "U_P702_MY2021_Rx" SG_ 633 Shed_Feature_Group_ID_UB 1;
BA_ "U_U55X_MY2022_Rx" SG_ 633 Shed_Feature_Group_ID 1;
BA_ "U_T6_MCA_MY2020_Rx" SG_ 633 Shed_Feature_Group_ID 1;
BA_ "U_P702_MY2021_Rx" SG_ 633 Shed_Feature_Group_ID 1;
BA_ "GenSigSendType" SG_ 633 Shed_Feature_Group_ID 3;
BA_ "WakeupSignal" SG_ 633 Shed_Feature_Group_ID 1;
BA_ "U_CD542_MY2021_Rx" SG_ 936 ApaSys_D_Stat 1;
BA_ "U_T6_MCA_MY2020_Rx" SG_ 936 ApaSys_D_Stat 1;
BA_ "U_P702_MY2021_Rx" SG_ 936 ApaSys_D_Stat 1;
BA_ "GenSigSendType" SG_ 936 ApaSys_D_Stat 3;
BA_ "U_CD542_MY2021_Rx" SG_ 936 ApaSteWhl_D_RqDrv 1;
BA_ "U_T6_MCA_MY2020_Rx" SG_ 936 ApaSteWhl_D_RqDrv 1;
BA_ "U_P702_MY2021_Rx" SG_ 936 ApaSteWhl_D_RqDrv 1;
BA_ "GenSigSendType" SG_ 936 ApaSteWhl_D_RqDrv 3;
BA_ "U_CD542_MY2021_Rx" SG_ 936 ApaSteScanMde_D_Stat 1;
BA_ "U_T6_MCA_MY2020_Rx" SG_ 936 ApaSteScanMde_D_Stat 1;
BA_ "U_P702_MY2021_Rx" SG_ 936 ApaSteScanMde_D_Stat 1;
BA_ "GenSigSendType" SG_ 936 ApaSteScanMde_D_Stat 3;
BA_ "U_CD542_MY2021_Rx" SG_ 936 ApaSelSapp_D_Stat 1;
BA_ "U_T6_MCA_MY2020_Rx" SG_ 936 ApaSelSapp_D_Stat 1;
BA_ "U_P702_MY2021_Rx" SG_ 936 ApaSelSapp_D_Stat 1;
BA_ "GenSigSendType" SG_ 936 ApaSelSapp_D_Stat 3;
BA_ "U_CD542_MY2021_Rx" SG_ 936 ApaSelPpa_D_Stat 1;
BA_ "U_T6_MCA_MY2020_Rx" SG_ 936 ApaSelPpa_D_Stat 1;
BA_ "U_P702_MY2021_Rx" SG_ 936 ApaSelPpa_D_Stat 1;
BA_ "GenSigSendType" SG_ 936 ApaSelPpa_D_Stat 3;
BA_ "U_CD542_MY2021_Rx" SG_ 936 ApaSelPoa_D_Stat 1;
BA_ "U_T6_MCA_MY2020_Rx" SG_ 936 ApaSelPoa_D_Stat 1;
BA_ "U_P702_MY2021_Rx" SG_ 936 ApaSelPoa_D_Stat 1;
BA_ "GenSigSendType" SG_ 936 ApaSelPoa_D_Stat 3;
BA_ "U_CD542_MY2021_Rx" SG_ 936 ApaScan_D_Stat 1;
BA_ "U_T6_MCA_MY2020_Rx" SG_ 936 ApaScan_D_Stat 1;
BA_ "U_P702_MY2021_Rx" SG_ 936 ApaScan_D_Stat 1;
BA_ "GenSigSendType" SG_ 936 ApaScan_D_Stat 3;
BA_ "U_CD542_MY2021_Rx" SG_ 936 ApaLongCtl_D_RqDrv 1;
BA_ "U_T6_MCA_MY2020_Rx" SG_ 936 ApaLongCtl_D_RqDrv 1;
BA_ "U_P702_MY2021_Rx" SG_ 936 ApaLongCtl_D_RqDrv 1;
BA_ "GenSigSendType" SG_ 936 ApaLongCtl_D_RqDrv 3;
BA_ "U_CD542_MY2021_Rx" SG_ 936 ApaGearShif_D_RqDrv 1;
BA_ "U_T6_MCA_MY2020_Rx" SG_ 936 ApaGearShif_D_RqDrv 1;
BA_ "U_P702_MY2021_Rx" SG_ 936 ApaGearShif_D_RqDrv 1;
BA_ "GenSigSendType" SG_ 936 ApaGearShif_D_RqDrv 3;
BA_ "U_CD542_MY2021_Rx" SG_ 936 ApaActvSide2_D_Stat 1;
BA_ "U_T6_MCA_MY2020_Rx" SG_ 936 ApaActvSide2_D_Stat 1;
BA_ "U_P702_MY2021_Rx" SG_ 936 ApaActvSide2_D_Stat 1;
BA_ "GenSigSendType" SG_ 936 ApaActvSide2_D_Stat 3;
BA_ "U_CD542_MY2021_Rx" SG_ 936 ApaAcsy_D_RqDrv 1;
BA_ "U_T6_MCA_MY2020_Rx" SG_ 936 ApaAcsy_D_RqDrv 1;
BA_ "U_P702_MY2021_Rx" SG_ 936 ApaAcsy_D_RqDrv 1;
BA_ "GenSigSendType" SG_ 936 ApaAcsy_D_RqDrv 3;
BA_ "U_U55X_MY2022_Rx" SG_ 936 ApaChime_D_Rq 1;
BA_ "U_CD542_MY2021_Rx" SG_ 936 ApaChime_D_Rq 1;
BA_ "U_T6_MCA_MY2020_Rx" SG_ 936 ApaChime_D_Rq 1;
BA_ "GenSigSendType" SG_ 936 ApaChime_D_Rq 3;
BA_ "GenSigSendType" SG_ 936 EPASExtAngleStatReq 3;
BA_ "U_U55X_MY2022_Rx" SG_ 936 ApaTrgtDist_D_Stat 1;
BA_ "U_CD542_MY2021_Rx" SG_ 936 ApaTrgtDist_D_Stat 1;
BA_ "U_T6_MCA_MY2020_Rx" SG_ 936 ApaTrgtDist_D_Stat 1;
BA_ "U_P702_MY2021_Rx" SG_ 936 ApaTrgtDist_D_Stat 1;
BA_ "U_U55X_MY2022_Rx" SG_ 936 ApaMsgTxt_D_Rq 1;
BA_ "U_CD542_MY2021_Rx" SG_ 936 ApaMsgTxt_D_Rq 1;
BA_ "U_T6_MCA_MY2020_Rx" SG_ 936 ApaMsgTxt_D_Rq 1;
BA_ "U_P702_MY2021_Rx" SG_ 936 ApaMsgTxt_D_Rq 1;
BA_ "U_U55X_MY2022_Tx" SG_ 674 ArmrestStwdRear_B_Stat 1;
BA_ "GenSigSendType" SG_ 674 ArmrestStwdRear_B_Stat 3;
BA_ "GenSigStartValue" SG_ 674 ArmrestStwdRear_B_Stat 1;
BA_ "GenSigStartValueInteger" SG_ 674 ArmrestStwdRear_B_Stat 1;
BA_ "U_U55X_MY2022_Tx" SG_ 674 RACM_SetVolume 1;
BA_ "U_U55X_MY2022_Rx" SG_ 674 RACM_SetVolume 1;
BA_ "U_CD542_MY2021_Rx" SG_ 674 RACM_SetVolume 1;
BA_ "GenSigSendType" SG_ 674 RACM_SetVolume 3;
BA_ "U_U55X_MY2022_Tx" SG_ 674 RACM_Coding_BtnID_D 1;
BA_ "U_U55X_MY2022_Rx" SG_ 674 RACM_Coding_BtnID_D 1;
BA_ "U_CD542_MY2021_Rx" SG_ 674 RACM_Coding_BtnID_D 1;
BA_ "GenSigSendType" SG_ 674 RACM_Coding_BtnID_D 3;
BA_ "U_U55X_MY2022_Tx" SG_ 674 RACM_Coding_BtnID_C 1;
BA_ "U_U55X_MY2022_Rx" SG_ 674 RACM_Coding_BtnID_C 1;
BA_ "U_CD542_MY2021_Rx" SG_ 674 RACM_Coding_BtnID_C 1;
BA_ "GenSigSendType" SG_ 674 RACM_Coding_BtnID_C 3;
BA_ "U_U55X_MY2022_Tx" SG_ 674 RACM_Coding_BtnID_B 1;
BA_ "U_U55X_MY2022_Rx" SG_ 674 RACM_Coding_BtnID_B 1;
BA_ "U_CD542_MY2021_Rx" SG_ 674 RACM_Coding_BtnID_B 1;
BA_ "GenSigSendType" SG_ 674 RACM_Coding_BtnID_B 3;
BA_ "U_U55X_MY2022_Tx" SG_ 674 RACM_Coding_BtnID_A 1;
BA_ "U_U55X_MY2022_Rx" SG_ 674 RACM_Coding_BtnID_A 1;
BA_ "U_CD542_MY2021_Rx" SG_ 674 RACM_Coding_BtnID_A 1;
BA_ "GenSigSendType" SG_ 674 RACM_Coding_BtnID_A 3;
BA_ "U_U55X_MY2022_Tx" SG_ 674 RACM_BtnID_D 1;
BA_ "U_U55X_MY2022_Rx" SG_ 674 RACM_BtnID_D 1;
BA_ "U_CD542_MY2021_Rx" SG_ 674 RACM_BtnID_D 1;
BA_ "GenSigSendType" SG_ 674 RACM_BtnID_D 3;
BA_ "U_U55X_MY2022_Tx" SG_ 674 RACM_BtnID_C 1;
BA_ "U_U55X_MY2022_Rx" SG_ 674 RACM_BtnID_C 1;
BA_ "U_CD542_MY2021_Rx" SG_ 674 RACM_BtnID_C 1;
BA_ "GenSigSendType" SG_ 674 RACM_BtnID_C 3;
BA_ "U_U55X_MY2022_Tx" SG_ 674 RACM_BtnID_B 1;
BA_ "U_U55X_MY2022_Rx" SG_ 674 RACM_BtnID_B 1;
BA_ "U_CD542_MY2021_Rx" SG_ 674 RACM_BtnID_B 1;
BA_ "GenSigSendType" SG_ 674 RACM_BtnID_B 3;
BA_ "U_U55X_MY2022_Tx" SG_ 674 RACM_BtnID_A 1;
BA_ "U_U55X_MY2022_Rx" SG_ 674 RACM_BtnID_A 1;
BA_ "U_CD542_MY2021_Rx" SG_ 674 RACM_BtnID_A 1;
BA_ "GenSigSendType" SG_ 674 RACM_BtnID_A 3;
BA_ "U_U55X_MY2022_Tx" SG_ 674 RearAudioCtlLck_D_Stat 1;
BA_ "U_U55X_MY2022_Rx" SG_ 674 RearAudioCtlLck_D_Stat 1;
BA_ "U_CD542_MY2021_Rx" SG_ 674 RearAudioCtlLck_D_Stat 1;
BA_ "GenSigSendType" SG_ 674 RearAudioCtlLck_D_Stat 3;
BA_ "U_U55X_MY2022_Rx" SG_ 75 VedsPasKneeBag_D_Ltchd 1;
BA_ "U_CD542_MY2021_Rx" SG_ 75 VedsPasKneeBag_D_Ltchd 1;
BA_ "U_T6_MCA_MY2020_Rx" SG_ 75 VedsPasKneeBag_D_Ltchd 1;
BA_ "U_P702_MY2021_Rx" SG_ 75 VedsPasKneeBag_D_Ltchd 1;
BA_ "GenSigSendType" SG_ 75 VedsPasKneeBag_D_Ltchd 3;
BA_ "U_U55X_MY2022_Rx" SG_ 75 VedsRw1mBckl_D_Ltchd 1;
BA_ "U_CD542_MY2021_Rx" SG_ 75 VedsRw1mBckl_D_Ltchd 1;
BA_ "U_T6_MCA_MY2020_Rx" SG_ 75 VedsRw1mBckl_D_Ltchd 1;
BA_ "U_P702_MY2021_Rx" SG_ 75 VedsRw1mBckl_D_Ltchd 1;
BA_ "GenSigSendType" SG_ 75 VedsRw1mBckl_D_Ltchd 3;
BA_ "U_U55X_MY2022_Rx" SG_ 75 VedsRw1mBelt_D_Ltchd 1;
BA_ "U_CD542_MY2021_Rx" SG_ 75 VedsRw1mBelt_D_Ltchd 1;
BA_ "U_T6_MCA_MY2020_Rx" SG_ 75 VedsRw1mBelt_D_Ltchd 1;
BA_ "U_P702_MY2021_Rx" SG_ 75 VedsRw1mBelt_D_Ltchd 1;
BA_ "GenSigSendType" SG_ 75 VedsRw1mBelt_D_Ltchd 3;
BA_ "U_U55X_MY2022_Rx" SG_ 75 VedsRw2pRib_D_Ltchd 1;
BA_ "U_CD542_MY2021_Rx" SG_ 75 VedsRw2pRib_D_Ltchd 1;
BA_ "U_T6_MCA_MY2020_Rx" SG_ 75 VedsRw2pRib_D_Ltchd 1;
BA_ "U_P702_MY2021_Rx" SG_ 75 VedsRw2pRib_D_Ltchd 1;
BA_ "GenSigSendType" SG_ 75 VedsRw2pRib_D_Ltchd 3;
BA_ "U_U55X_MY2022_Rx" SG_ 75 VedsRw2dRib_D_Ltchd 1;
BA_ "U_CD542_MY2021_Rx" SG_ 75 VedsRw2dRib_D_Ltchd 1;
BA_ "U_T6_MCA_MY2020_Rx" SG_ 75 VedsRw2dRib_D_Ltchd 1;
BA_ "U_P702_MY2021_Rx" SG_ 75 VedsRw2dRib_D_Ltchd 1;
BA_ "GenSigSendType" SG_ 75 VedsRw2dRib_D_Ltchd 3;
BA_ "U_U55X_MY2022_Rx" SG_ 75 VedsRw3pBckl_D_Ltchd 1;
BA_ "U_CD542_MY2021_Rx" SG_ 75 VedsRw3pBckl_D_Ltchd 1;
BA_ "U_T6_MCA_MY2020_Rx" SG_ 75 VedsRw3pBckl_D_Ltchd 1;
BA_ "U_P702_MY2021_Rx" SG_ 75 VedsRw3pBckl_D_Ltchd 1;
BA_ "GenSigSendType" SG_ 75 VedsRw3pBckl_D_Ltchd 3;
BA_ "U_U55X_MY2022_Rx" SG_ 75 VedsRw3mBckl_D_Ltchd 1;
BA_ "U_CD542_MY2021_Rx" SG_ 75 VedsRw3mBckl_D_Ltchd 1;
BA_ "U_T6_MCA_MY2020_Rx" SG_ 75 VedsRw3mBckl_D_Ltchd 1;
BA_ "U_P702_MY2021_Rx" SG_ 75 VedsRw3mBckl_D_Ltchd 1;
BA_ "GenSigSendType" SG_ 75 VedsRw3mBckl_D_Ltchd 3;
BA_ "U_U55X_MY2022_Rx" SG_ 75 VedsRw3dBckl_D_Ltchd 1;
BA_ "U_CD542_MY2021_Rx" SG_ 75 VedsRw3dBckl_D_Ltchd 1;
BA_ "U_T6_MCA_MY2020_Rx" SG_ 75 VedsRw3dBckl_D_Ltchd 1;
BA_ "U_P702_MY2021_Rx" SG_ 75 VedsRw3dBckl_D_Ltchd 1;
BA_ "GenSigSendType" SG_ 75 VedsRw3dBckl_D_Ltchd 3;
BA_ "U_U55X_MY2022_Rx" SG_ 75 VedsRw2pBckl_D_Ltchd 1;
BA_ "U_CD542_MY2021_Rx" SG_ 75 VedsRw2pBckl_D_Ltchd 1;
BA_ "U_T6_MCA_MY2020_Rx" SG_ 75 VedsRw2pBckl_D_Ltchd 1;
BA_ "U_P702_MY2021_Rx" SG_ 75 VedsRw2pBckl_D_Ltchd 1;
BA_ "GenSigSendType" SG_ 75 VedsRw2pBckl_D_Ltchd 3;
BA_ "U_U55X_MY2022_Rx" SG_ 75 VedsRw2mBckl_D_Ltchd 1;
BA_ "U_CD542_MY2021_Rx" SG_ 75 VedsRw2mBckl_D_Ltchd 1;
BA_ "U_T6_MCA_MY2020_Rx" SG_ 75 VedsRw2mBckl_D_Ltchd 1;
BA_ "U_P702_MY2021_Rx" SG_ 75 VedsRw2mBckl_D_Ltchd 1;
BA_ "GenSigSendType" SG_ 75 VedsRw2mBckl_D_Ltchd 3;
BA_ "U_U55X_MY2022_Rx" SG_ 75 VedsRw2dBckl_D_Ltchd 1;
BA_ "U_CD542_MY2021_Rx" SG_ 75 VedsRw2dBckl_D_Ltchd 1;
BA_ "U_T6_MCA_MY2020_Rx" SG_ 75 VedsRw2dBckl_D_Ltchd 1;
BA_ "U_P702_MY2021_Rx" SG_ 75 VedsRw2dBckl_D_Ltchd 1;
BA_ "GenSigSendType" SG_ 75 VedsRw2dBckl_D_Ltchd 3;
BA_ "U_U55X_MY2022_Rx" SG_ 75 VedsRw1PasChld_D_Ltchd 1;
BA_ "U_CD542_MY2021_Rx" SG_ 75 VedsRw1PasChld_D_Ltchd 1;
BA_ "U_T6_MCA_MY2020_Rx" SG_ 75 VedsRw1PasChld_D_Ltchd 1;
BA_ "U_P702_MY2021_Rx" SG_ 75 VedsRw1PasChld_D_Ltchd 1;
BA_ "GenSigSendType" SG_ 75 VedsRw1PasChld_D_Ltchd 3;
BA_ "U_U55X_MY2022_Rx" SG_ 75 VedsRw1PasBckl_D_Ltchd 1;
BA_ "U_CD542_MY2021_Rx" SG_ 75 VedsRw1PasBckl_D_Ltchd 1;
BA_ "U_T6_MCA_MY2020_Rx" SG_ 75 VedsRw1PasBckl_D_Ltchd 1;
BA_ "U_P702_MY2021_Rx" SG_ 75 VedsRw1PasBckl_D_Ltchd 1;
BA_ "GenSigSendType" SG_ 75 VedsRw1PasBckl_D_Ltchd 3;
BA_ "U_U55X_MY2022_Rx" SG_ 75 VedsRw1DrvBckl_D_Ltchd 1;
BA_ "U_CD542_MY2021_Rx" SG_ 75 VedsRw1DrvBckl_D_Ltchd 1;
BA_ "U_T6_MCA_MY2020_Rx" SG_ 75 VedsRw1DrvBckl_D_Ltchd 1;
BA_ "U_P702_MY2021_Rx" SG_ 75 VedsRw1DrvBckl_D_Ltchd 1;
BA_ "GenSigSendType" SG_ 75 VedsRw1DrvBckl_D_Ltchd 3;
BA_ "U_U55X_MY2022_Rx" SG_ 75 VedsRw3pRib_D_Ltchd 1;
BA_ "U_CD542_MY2021_Rx" SG_ 75 VedsRw3pRib_D_Ltchd 1;
BA_ "U_T6_MCA_MY2020_Rx" SG_ 75 VedsRw3pRib_D_Ltchd 1;
BA_ "U_P702_MY2021_Rx" SG_ 75 VedsRw3pRib_D_Ltchd 1;
BA_ "GenSigSendType" SG_ 75 VedsRw3pRib_D_Ltchd 3;
BA_ "U_U55X_MY2022_Rx" SG_ 75 VedsRw3dRib_D_Ltchd 1;
BA_ "U_CD542_MY2021_Rx" SG_ 75 VedsRw3dRib_D_Ltchd 1;
BA_ "U_T6_MCA_MY2020_Rx" SG_ 75 VedsRw3dRib_D_Ltchd 1;
BA_ "U_P702_MY2021_Rx" SG_ 75 VedsRw3dRib_D_Ltchd 1;
BA_ "GenSigSendType" SG_ 75 VedsRw3dRib_D_Ltchd 3;
BA_ "U_CD542_MY2021_Rx" SG_ 74 VedsPasSideBag_D_Ltchd 1;
BA_ "U_U55X_MY2022_Rx" SG_ 74 VedsPasSideBag_D_Ltchd 1;
BA_ "U_T6_MCA_MY2020_Rx" SG_ 74 VedsPasSideBag_D_Ltchd 1;
BA_ "GenSigSendType" SG_ 74 VedsPasSideBag_D_Ltchd 3;
BA_ "U_CD542_MY2021_Rx" SG_ 74 VedsPasCrtnBag_D_Ltchd 1;
BA_ "U_U55X_MY2022_Rx" SG_ 74 VedsPasCrtnBag_D_Ltchd 1;
BA_ "U_T6_MCA_MY2020_Rx" SG_ 74 VedsPasCrtnBag_D_Ltchd 1;
BA_ "GenSigSendType" SG_ 74 VedsPasCrtnBag_D_Ltchd 3;
BA_ "U_CD542_MY2021_Rx" SG_ 74 VedsPasBelt_D_Ltchd 1;
BA_ "U_U55X_MY2022_Rx" SG_ 74 VedsPasBelt_D_Ltchd 1;
BA_ "U_T6_MCA_MY2020_Rx" SG_ 74 VedsPasBelt_D_Ltchd 1;
BA_ "GenSigSendType" SG_ 74 VedsPasBelt_D_Ltchd 3;
BA_ "U_CD542_MY2021_Rx" SG_ 74 VedsPasBag_D_Ltchd 1;
BA_ "U_U55X_MY2022_Rx" SG_ 74 VedsPasBag_D_Ltchd 1;
BA_ "U_T6_MCA_MY2020_Rx" SG_ 74 VedsPasBag_D_Ltchd 1;
BA_ "GenSigSendType" SG_ 74 VedsPasBag_D_Ltchd 3;
BA_ "U_CD542_MY2021_Rx" SG_ 74 VedsMultiEvnt_D_Ltchd 1;
BA_ "U_U55X_MY2022_Rx" SG_ 74 VedsMultiEvnt_D_Ltchd 1;
BA_ "U_T6_MCA_MY2020_Rx" SG_ 74 VedsMultiEvnt_D_Ltchd 1;
BA_ "GenSigSendType" SG_ 74 VedsMultiEvnt_D_Ltchd 3;
BA_ "U_CD542_MY2021_Rx" SG_ 74 VedsMaxDeltaV_D_Ltchd 1;
BA_ "U_U55X_MY2022_Rx" SG_ 74 VedsMaxDeltaV_D_Ltchd 1;
BA_ "U_T6_MCA_MY2020_Rx" SG_ 74 VedsMaxDeltaV_D_Ltchd 1;
BA_ "U_CD542_MY2021_Rx" SG_ 74 VedsDrvKneeBag_D_Ltchd 1;
BA_ "U_U55X_MY2022_Rx" SG_ 74 VedsDrvKneeBag_D_Ltchd 1;
BA_ "U_T6_MCA_MY2020_Rx" SG_ 74 VedsDrvKneeBag_D_Ltchd 1;
BA_ "GenSigSendType" SG_ 74 VedsDrvKneeBag_D_Ltchd 3;
BA_ "U_CD542_MY2021_Rx" SG_ 74 VedsEvntType_D_Ltchd 1;
BA_ "U_U55X_MY2022_Rx" SG_ 74 VedsEvntType_D_Ltchd 1;
BA_ "U_T6_MCA_MY2020_Rx" SG_ 74 VedsEvntType_D_Ltchd 1;
BA_ "GenSigSendType" SG_ 74 VedsEvntType_D_Ltchd 3;
BA_ "U_CD542_MY2021_Rx" SG_ 74 VedsEvntRoll_D_Ltchd 1;
BA_ "U_U55X_MY2022_Rx" SG_ 74 VedsEvntRoll_D_Ltchd 1;
BA_ "U_T6_MCA_MY2020_Rx" SG_ 74 VedsEvntRoll_D_Ltchd 1;
BA_ "GenSigSendType" SG_ 74 VedsEvntRoll_D_Ltchd 3;
BA_ "U_CD542_MY2021_Rx" SG_ 74 VedsDrvSideBag_D_Ltchd 1;
BA_ "U_U55X_MY2022_Rx" SG_ 74 VedsDrvSideBag_D_Ltchd 1;
BA_ "U_T6_MCA_MY2020_Rx" SG_ 74 VedsDrvSideBag_D_Ltchd 1;
BA_ "GenSigSendType" SG_ 74 VedsDrvSideBag_D_Ltchd 3;
BA_ "U_CD542_MY2021_Rx" SG_ 74 VedsDrvCrtnBag_D_Ltchd 1;
BA_ "U_U55X_MY2022_Rx" SG_ 74 VedsDrvCrtnBag_D_Ltchd 1;
BA_ "U_T6_MCA_MY2020_Rx" SG_ 74 VedsDrvCrtnBag_D_Ltchd 1;
BA_ "GenSigSendType" SG_ 74 VedsDrvCrtnBag_D_Ltchd 3;
BA_ "U_U55X_MY2022_Rx" SG_ 74 VedsDrvBelt_D_Ltchd 1;
BA_ "U_T6_MCA_MY2020_Rx" SG_ 74 VedsDrvBelt_D_Ltchd 1;
BA_ "U_CD542_MY2021_Rx" SG_ 74 VedsDrvBelt_D_Ltchd 1;
BA_ "GenSigSendType" SG_ 74 VedsDrvBelt_D_Ltchd 3;
BA_ "U_U55X_MY2022_Rx" SG_ 74 VedsDrvBag_D_Ltchd 1;
BA_ "U_CD542_MY2021_Rx" SG_ 74 VedsDrvBag_D_Ltchd 1;
BA_ "U_T6_MCA_MY2020_Rx" SG_ 74 VedsDrvBag_D_Ltchd 1;
BA_ "U_P702_MY2021_Rx" SG_ 74 VedsDrvBag_D_Ltchd 1;
BA_ "GenSigSendType" SG_ 74 VedsDrvBag_D_Ltchd 3;
BA_ "U_U55X_MY2022_Rx" SG_ 74 eCallNotification 1;
BA_ "U_T6_MCA_MY2020_Rx" SG_ 74 eCallNotification 1;
BA_ "U_CD542_MY2021_Rx" SG_ 74 eCallNotification 1;
BA_ "GenSigSendType" SG_ 74 eCallNotification 3;
BA_ "GenSigStartValue" SG_ 74 eCallNotification 1;
BA_ "GenSigStartValueInteger" SG_ 74 eCallNotification 1;
BA_ "U_U55X_MY2022_Rx" SG_ 780 TrlrTireSensRm_D_Stat 1;
BA_ "U_T6_MCA_MY2020_Rx" SG_ 780 TrlrTireSensRm_D_Stat 1;
BA_ "U_U55X_MY2022_Rx" SG_ 780 TrlrTireSensRf_D_Stat 1;
BA_ "U_T6_MCA_MY2020_Rx" SG_ 780 TrlrTireSensRf_D_Stat 1;
BA_ "U_U55X_MY2022_Rx" SG_ 780 TrlrTireRr_P_Actl 1;
BA_ "U_T6_MCA_MY2020_Rx" SG_ 780 TrlrTireRr_P_Actl 1;
BA_ "U_P702_MY2021_Rx" SG_ 780 TrlrTireRr_P_Actl 1;
BA_ "GenSigStartValue" SG_ 780 TrlrTireRr_P_Actl 65533;
BA_ "GenSigStartValueInteger" SG_ 780 TrlrTireRr_P_Actl 65533;
BA_ "U_U55X_MY2022_Rx" SG_ 780 TrlrTireRm_P_Actl 1;
BA_ "U_T6_MCA_MY2020_Rx" SG_ 780 TrlrTireRm_P_Actl 1;
BA_ "U_P702_MY2021_Rx" SG_ 780 TrlrTireRm_P_Actl 1;
BA_ "GenSigStartValue" SG_ 780 TrlrTireRm_P_Actl 65533;
BA_ "GenSigStartValueInteger" SG_ 780 TrlrTireRm_P_Actl 65533;
BA_ "U_U55X_MY2022_Rx" SG_ 780 TrlrTireRf_P_Actl 1;
BA_ "U_T6_MCA_MY2020_Rx" SG_ 780 TrlrTireRf_P_Actl 1;
BA_ "U_P702_MY2021_Rx" SG_ 780 TrlrTireRf_P_Actl 1;
BA_ "GenSigStartValue" SG_ 780 TrlrTireRf_P_Actl 65533;
BA_ "GenSigStartValueInteger" SG_ 780 TrlrTireRf_P_Actl 65533;
BA_ "U_U55X_MY2022_Rx" SG_ 780 TrlrTireSensRr_D_Stat 1;
BA_ "U_T6_MCA_MY2020_Rx" SG_ 780 TrlrTireSensRr_D_Stat 1;
BA_ "U_U55X_MY2022_Rx" SG_ 779 TrlrTireSensLr_D_Stat 1;
BA_ "U_T6_MCA_MY2020_Rx" SG_ 779 TrlrTireSensLr_D_Stat 1;
BA_ "U_U55X_MY2022_Rx" SG_ 779 TrlrTireSensLm_D_Stat 1;
BA_ "U_T6_MCA_MY2020_Rx" SG_ 779 TrlrTireSensLm_D_Stat 1;
BA_ "U_U55X_MY2022_Rx" SG_ 779 TrlrTireSensLf_D_Stat 1;
BA_ "U_T6_MCA_MY2020_Rx" SG_ 779 TrlrTireSensLf_D_Stat 1;
BA_ "U_U55X_MY2022_Rx" SG_ 779 TrlrTireLr_P_Actl 1;
BA_ "U_T6_MCA_MY2020_Rx" SG_ 779 TrlrTireLr_P_Actl 1;
BA_ "U_P702_MY2021_Rx" SG_ 779 TrlrTireLr_P_Actl 1;
BA_ "GenSigStartValue" SG_ 779 TrlrTireLr_P_Actl 65533;
BA_ "GenSigStartValueInteger" SG_ 779 TrlrTireLr_P_Actl 65533;
BA_ "U_U55X_MY2022_Rx" SG_ 779 TrlrTireLm_P_Actl 1;
BA_ "U_T6_MCA_MY2020_Rx" SG_ 779 TrlrTireLm_P_Actl 1;
BA_ "U_P702_MY2021_Rx" SG_ 779 TrlrTireLm_P_Actl 1;
BA_ "GenSigStartValue" SG_ 779 TrlrTireLm_P_Actl 65533;
BA_ "GenSigStartValueInteger" SG_ 779 TrlrTireLm_P_Actl 65533;
BA_ "U_U55X_MY2022_Rx" SG_ 779 TrlrTireLf_P_Actl 1;
BA_ "U_T6_MCA_MY2020_Rx" SG_ 779 TrlrTireLf_P_Actl 1;
BA_ "U_P702_MY2021_Rx" SG_ 779 TrlrTireLf_P_Actl 1;
BA_ "GenSigStartValue" SG_ 779 TrlrTireLf_P_Actl 65533;
BA_ "GenSigStartValueInteger" SG_ 779 TrlrTireLf_P_Actl 65533;
BA_ "U_U55X_MY2022_Tx" SG_ 783 TrlrTireThresh_D_RqDrv 1;
BA_ "U_CD542_MY2021_Tx" SG_ 783 TrlrTireThresh_D_RqDrv 1;
BA_ "U_P702_MY2021_Tx" SG_ 783 TrlrTireThresh_D_RqDrv 1;
BA_ "U_U55X_MY2022_Tx" SG_ 783 TrlrTireCnt_D_RqDrv 1;
BA_ "U_CD542_MY2021_Tx" SG_ 783 TrlrTireCnt_D_RqDrv 1;
BA_ "GenSigSendType" SG_ 783 TrlrTireCnt_D_RqDrv 3;
BA_ "U_U55X_MY2022_Tx" SG_ 783 TrlrLearnMdeOn_B_RqDrv 1;
BA_ "U_CD542_MY2021_Tx" SG_ 783 TrlrLearnMdeOn_B_RqDrv 1;
BA_ "GenSigSendType" SG_ 783 TrlrLearnMdeOn_B_RqDrv 3;
BA_ "U_U55X_MY2022_Rx" SG_ 638 EmgcyCallHmi_D_Stat 1;
BA_ "U_T6_MCA_MY2020_Rx" SG_ 638 EmgcyCallHmi_D_Stat 1;
BA_ "U_P702_MY2021_Rx" SG_ 638 EmgcyCallHmi_D_Stat 1;
BA_ "U_CD542_MY2021_Rx" SG_ 638 EmgcyCallHmi_D_Stat 1;
BA_ "U_U55X_MY2022_Rx" SG_ 638 EmgcyCallFalt_B_Dsply 1;
BA_ "U_CD542_MY2021_Rx" SG_ 638 EmgcyCallFalt_B_Dsply 1;
BA_ "U_T6_MCA_MY2020_Rx" SG_ 638 EmgcyCallFalt_B_Dsply 1;
BA_ "U_U55X_MY2022_Rx" SG_ 638 EmgcyCallCancl_T_Actl 1;
BA_ "U_T6_MCA_MY2020_Rx" SG_ 638 EmgcyCallCancl_T_Actl 1;
BA_ "U_P702_MY2021_Rx" SG_ 638 EmgcyCallCancl_T_Actl 1;
BA_ "U_CD542_MY2021_Rx" SG_ 638 EmgcyCallCancl_T_Actl 1;
BA_ "U_U55X_MY2022_Rx" SG_ 638 EmgcyCall_D_Stat 1;
BA_ "U_T6_MCA_MY2020_Rx" SG_ 638 EmgcyCall_D_Stat 1;
BA_ "U_P702_MY2021_Rx" SG_ 638 EmgcyCall_D_Stat 1;
BA_ "U_CD542_MY2021_Rx" SG_ 638 EmgcyCall_D_Stat 1;
BA_ "U_U55X_MY2022_Tx" SG_ 555 HudVertSzMnuOn_B_Stat 1;
BA_ "U_T6_MCA_MY2020_Tx" SG_ 555 HudVertSzMnuOn_B_Stat 1;
BA_ "U_U55X_MY2022_Rx" SG_ 555 HudVertSzMnuOn_B_Stat 1;
BA_ "U_CD542_MY2021_Rx" SG_ 555 HudVertSzMnuOn_B_Stat 1;
BA_ "U_T6_MCA_MY2020_Rx" SG_ 555 HudVertSzMnuOn_B_Stat 1;
BA_ "GenSigSendType" SG_ 555 HudVertSzMnuOn_B_Stat 3;
BA_ "U_U55X_MY2022_Tx" SG_ 555 HudVertMnuOn_B_Stat 1;
BA_ "U_T6_MCA_MY2020_Tx" SG_ 555 HudVertMnuOn_B_Stat 1;
BA_ "U_U55X_MY2022_Rx" SG_ 555 HudVertMnuOn_B_Stat 1;
BA_ "U_CD542_MY2021_Rx" SG_ 555 HudVertMnuOn_B_Stat 1;
BA_ "U_T6_MCA_MY2020_Rx" SG_ 555 HudVertMnuOn_B_Stat 1;
BA_ "GenSigSendType" SG_ 555 HudVertMnuOn_B_Stat 3;
BA_ "U_U55X_MY2022_Tx" SG_ 555 HudTestMdeActv_B_Stat 1;
BA_ "U_T6_MCA_MY2020_Tx" SG_ 555 HudTestMdeActv_B_Stat 1;
BA_ "U_U55X_MY2022_Rx" SG_ 555 HudTestMdeActv_B_Stat 1;
BA_ "U_CD542_MY2021_Rx" SG_ 555 HudTestMdeActv_B_Stat 1;
BA_ "U_T6_MCA_MY2020_Rx" SG_ 555 HudTestMdeActv_B_Stat 1;
BA_ "GenSigSendType" SG_ 555 HudTestMdeActv_B_Stat 3;
BA_ "U_U55X_MY2022_Tx" SG_ 555 HudSwtch_B_Stat 1;
BA_ "U_T6_MCA_MY2020_Tx" SG_ 555 HudSwtch_B_Stat 1;
BA_ "U_U55X_MY2022_Rx" SG_ 555 HudSwtch_B_Stat 1;
BA_ "U_T6_MCA_MY2020_Rx" SG_ 555 HudSwtch_B_Stat 1;
BA_ "GenSigSendType" SG_ 555 HudSwtch_B_Stat 3;
BA_ "U_U55X_MY2022_Tx" SG_ 555 HudRotatMnuOn_B_Stat 1;
BA_ "U_T6_MCA_MY2020_Tx" SG_ 555 HudRotatMnuOn_B_Stat 1;
BA_ "U_U55X_MY2022_Rx" SG_ 555 HudRotatMnuOn_B_Stat 1;
BA_ "U_T6_MCA_MY2020_Rx" SG_ 555 HudRotatMnuOn_B_Stat 1;
BA_ "GenSigSendType" SG_ 555 HudRotatMnuOn_B_Stat 3;
BA_ "U_U55X_MY2022_Tx" SG_ 555 HudMsgTxt_D_Rq 1;
BA_ "U_T6_MCA_MY2020_Tx" SG_ 555 HudMsgTxt_D_Rq 1;
BA_ "U_U55X_MY2022_Rx" SG_ 555 HudMsgTxt_D_Rq 1;
BA_ "U_T6_MCA_MY2020_Rx" SG_ 555 HudMsgTxt_D_Rq 1;
BA_ "GenSigSendType" SG_ 555 HudMsgTxt_D_Rq 3;
BA_ "U_U55X_MY2022_Tx" SG_ 555 HudHzntlMnuOn_B_Stat 1;
BA_ "U_T6_MCA_MY2020_Tx" SG_ 555 HudHzntlMnuOn_B_Stat 1;
BA_ "U_U55X_MY2022_Rx" SG_ 555 HudHzntlMnuOn_B_Stat 1;
BA_ "U_T6_MCA_MY2020_Rx" SG_ 555 HudHzntlMnuOn_B_Stat 1;
BA_ "GenSigSendType" SG_ 555 HudHzntlMnuOn_B_Stat 3;
BA_ "U_U55X_MY2022_Tx" SG_ 555 HudBrightMnuOn_B_Stat 1;
BA_ "U_T6_MCA_MY2020_Tx" SG_ 555 HudBrightMnuOn_B_Stat 1;
BA_ "U_U55X_MY2022_Rx" SG_ 555 HudBrightMnuOn_B_Stat 1;
BA_ "U_CD542_MY2021_Rx" SG_ 555 HudBrightMnuOn_B_Stat 1;
BA_ "U_T6_MCA_MY2020_Rx" SG_ 555 HudBrightMnuOn_B_Stat 1;
BA_ "GenSigSendType" SG_ 555 HudBrightMnuOn_B_Stat 3;
BA_ "U_U55X_MY2022_Tx" SG_ 555 HudActv_D_Stat 1;
BA_ "U_T6_MCA_MY2020_Tx" SG_ 555 HudActv_D_Stat 1;
BA_ "U_U55X_MY2022_Rx" SG_ 555 HudActv_D_Stat 1;
BA_ "U_T6_MCA_MY2020_Rx" SG_ 555 HudActv_D_Stat 1;
BA_ "GenSigSendType" SG_ 555 HudActv_D_Stat 3;
BA_ "GenSigStartValue" SG_ 124 VehTrvlDir_D_Stat 6;
BA_ "GenSigStartValueInteger" SG_ 124 VehTrvlDir_D_Stat 6;
BA_ "U_U55X_MY2022_Rx" SG_ 124 VehOverGnd_V_Est 1;
BA_ "U_CD542_MY2021_Rx" SG_ 124 VehOverGnd_V_Est 1;
BA_ "U_P702_MY2021_Rx" SG_ 124 VehOverGnd_V_Est 1;
BA_ "U_T6_MCA_MY2020_Rx" SG_ 124 VehOverGnd_V_Est 1;
BA_ "U_U55X_MY2022_Rx" SG_ 124 VehLongComp_A_Actl 1;
BA_ "U_P702_MY2021_Rx" SG_ 124 VehLongComp_A_Actl 1;
BA_ "U_CD542_MY2021_Rx" SG_ 124 VehLongComp_A_Actl 1;
BA_ "U_T6_MCA_MY2020_Rx" SG_ 124 VehLongComp_A_Actl 1;
BA_ "GenSigStartValue" SG_ 124 VehLongComp_A_Actl 1022;
BA_ "GenSigStartValueInteger" SG_ 124 VehLongComp_A_Actl 1022;
BA_ "U_U55X_MY2022_Rx" SG_ 124 VehLatComp_A_Actl 1;
BA_ "U_P702_MY2021_Rx" SG_ 124 VehLatComp_A_Actl 1;
BA_ "U_CD542_MY2021_Rx" SG_ 124 VehLatComp_A_Actl 1;
BA_ "U_T6_MCA_MY2020_Rx" SG_ 124 VehLatComp_A_Actl 1;
BA_ "GenSigStartValue" SG_ 124 VehLatComp_A_Actl 1022;
BA_ "GenSigStartValueInteger" SG_ 124 VehLatComp_A_Actl 1022;
BA_ "U_U55X_MY2022_Rx" SG_ 124 VehYawComp_W_Actl 1;
BA_ "U_CD542_MY2021_Rx" SG_ 124 VehYawComp_W_Actl 1;
BA_ "U_P702_MY2021_Rx" SG_ 124 VehYawComp_W_Actl 1;
BA_ "U_T6_MCA_MY2020_Rx" SG_ 124 VehYawComp_W_Actl 1;
BA_ "GenSigStartValue" SG_ 124 VehYawComp_W_Actl 4094;
BA_ "GenSigStartValueInteger" SG_ 124 VehYawComp_W_Actl 4094;
BA_ "U_U55X_MY2022_Tx" SG_ 736 TextMessage_Rsp 1;
BA_ "U_CD542_MY2021_Tx" SG_ 736 TextMessage_Rsp 1;
BA_ "U_T6_MCA_MY2020_Tx" SG_ 736 TextMessage_Rsp 1;
BA_ "U_U55X_MY2022_Rx" SG_ 736 TextMessage_Rsp 1;
BA_ "U_CD542_MY2021_Rx" SG_ 736 TextMessage_Rsp 1;
BA_ "U_T6_MCA_MY2020_Rx" SG_ 736 TextMessage_Rsp 1;
BA_ "GenSigSendType" SG_ 736 TextMessage_Rsp 3;
BA_ "U_U55X_MY2022_Tx" SG_ 736 VRM_IncCallOption_St 1;
BA_ "U_CD542_MY2021_Tx" SG_ 736 VRM_IncCallOption_St 1;
BA_ "U_T6_MCA_MY2020_Tx" SG_ 736 VRM_IncCallOption_St 1;
BA_ "GenSigSendType" SG_ 736 VRM_IncCallOption_St 3;
BA_ "U_U55X_MY2022_Tx" SG_ 736 VRM_PhonesSts_Rsp 1;
BA_ "U_CD542_MY2021_Tx" SG_ 736 VRM_PhonesSts_Rsp 1;
BA_ "U_T6_MCA_MY2020_Tx" SG_ 736 VRM_PhonesSts_Rsp 1;
BA_ "U_U55X_MY2022_Tx" SG_ 736 VRM_CallDuration_St 1;
BA_ "U_CD542_MY2021_Tx" SG_ 736 VRM_CallDuration_St 1;
BA_ "U_T6_MCA_MY2020_Tx" SG_ 736 VRM_CallDuration_St 1;
BA_ "U_U55X_MY2022_Rx" SG_ 736 VRM_CallDuration_St 1;
BA_ "U_CD542_MY2021_Rx" SG_ 736 VRM_CallDuration_St 1;
BA_ "U_T6_MCA_MY2020_Rx" SG_ 736 VRM_CallDuration_St 1;
BA_ "U_U55X_MY2022_Tx" SG_ 736 BTInCallOptions_St 1;
BA_ "U_CD542_MY2021_Tx" SG_ 736 BTInCallOptions_St 1;
BA_ "U_T6_MCA_MY2020_Tx" SG_ 736 BTInCallOptions_St 1;
BA_ "U_U55X_MY2022_Rx" SG_ 736 BTInCallOptions_St 1;
BA_ "U_CD542_MY2021_Rx" SG_ 736 BTInCallOptions_St 1;
BA_ "U_T6_MCA_MY2020_Rx" SG_ 736 BTInCallOptions_St 1;
BA_ "GenSigSendType" SG_ 736 BTInCallOptions_St 3;
BA_ "U_T6_MCA_MY2020_Tx" SG_ 722 VRM_ComShuffleTrack_St 1;
BA_ "U_U55X_MY2022_Tx" SG_ 722 VRM_ComShuffleTrack_St 1;
BA_ "U_CD542_MY2021_Tx" SG_ 722 VRM_ComShuffleTrack_St 1;
BA_ "GenSigSendType" SG_ 722 VRM_ComShuffleTrack_St 3;
BA_ "U_T6_MCA_MY2020_Tx" SG_ 722 VRM_ComCompression_St 1;
BA_ "U_U55X_MY2022_Tx" SG_ 722 VRM_ComCompression_St 1;
BA_ "U_CD542_MY2021_Tx" SG_ 722 VRM_ComCompression_St 1;
BA_ "GenSigSendType" SG_ 722 VRM_ComCompression_St 3;
BA_ "U_T6_MCA_MY2020_Tx" SG_ 722 VRM_ComStFreqMode_St 1;
BA_ "U_U55X_MY2022_Tx" SG_ 722 VRM_ComStFreqMode_St 1;
BA_ "U_CD542_MY2021_Tx" SG_ 722 VRM_ComStFreqMode_St 1;
BA_ "GenSigSendType" SG_ 722 VRM_ComStFreqMode_St 3;
BA_ "U_U55X_MY2022_Tx" SG_ 722 VRM_ComAutostore_St 1;
BA_ "U_CD542_MY2021_Tx" SG_ 722 VRM_ComAutostore_St 1;
BA_ "U_T6_MCA_MY2020_Tx" SG_ 722 VRM_ComAutostore_St 1;
BA_ "GenSigSendType" SG_ 722 VRM_ComAutostore_St 3;
BA_ "U_U55X_MY2022_Tx" SG_ 722 VRM_ComBand_St 1;
BA_ "U_CD542_MY2021_Tx" SG_ 722 VRM_ComBand_St 1;
BA_ "U_T6_MCA_MY2020_Tx" SG_ 722 VRM_ComBand_St 1;
BA_ "GenSigSendType" SG_ 722 VRM_ComBand_St 3;
BA_ "U_U55X_MY2022_Tx" SG_ 722 VRM_TMCVoice 1;
BA_ "U_CD542_MY2021_Tx" SG_ 722 VRM_TMCVoice 1;
BA_ "U_T6_MCA_MY2020_Tx" SG_ 722 VRM_TMCVoice 1;
BA_ "GenSigSendType" SG_ 722 VRM_TMCVoice 3;
BA_ "U_U55X_MY2022_Tx" SG_ 722 VRM_NewSMS 1;
BA_ "U_CD542_MY2021_Tx" SG_ 722 VRM_NewSMS 1;
BA_ "U_T6_MCA_MY2020_Tx" SG_ 722 VRM_NewSMS 1;
BA_ "U_U55X_MY2022_Rx" SG_ 722 VRM_NewSMS 1;
BA_ "U_CD542_MY2021_Rx" SG_ 722 VRM_NewSMS 1;
BA_ "U_T6_MCA_MY2020_Rx" SG_ 722 VRM_NewSMS 1;
BA_ "GenSigSendType" SG_ 722 VRM_NewSMS 3;
BA_ "U_U55X_MY2022_Tx" SG_ 722 VRM_ComRSEDisplay_St 1;
BA_ "U_CD542_MY2021_Tx" SG_ 722 VRM_ComRSEDisplay_St 1;
BA_ "U_T6_MCA_MY2020_Tx" SG_ 722 VRM_ComRSEDisplay_St 1;
BA_ "GenSigSendType" SG_ 722 VRM_ComRSEDisplay_St 3;
BA_ "U_U55X_MY2022_Tx" SG_ 722 VRM_ComPICode_St 1;
BA_ "U_CD542_MY2021_Tx" SG_ 722 VRM_ComPICode_St 1;
BA_ "U_T6_MCA_MY2020_Tx" SG_ 722 VRM_ComPICode_St 1;
BA_ "U_U55X_MY2022_Tx" SG_ 722 VRM_ComPresetCall_St 1;
BA_ "U_CD542_MY2021_Tx" SG_ 722 VRM_ComPresetCall_St 1;
BA_ "U_T6_MCA_MY2020_Tx" SG_ 722 VRM_ComPresetCall_St 1;
BA_ "GenSigSendType" SG_ 722 VRM_ComPresetCall_St 3;
BA_ "U_U55X_MY2022_Tx" SG_ 722 VRM_ComTape_St 1;
BA_ "U_CD542_MY2021_Tx" SG_ 722 VRM_ComTape_St 1;
BA_ "U_T6_MCA_MY2020_Tx" SG_ 722 VRM_ComTape_St 1;
BA_ "GenSigSendType" SG_ 722 VRM_ComTape_St 3;
BA_ "U_U55X_MY2022_Tx" SG_ 722 VRM_ComShuffleDiscs_St 1;
BA_ "U_CD542_MY2021_Tx" SG_ 722 VRM_ComShuffleDiscs_St 1;
BA_ "U_T6_MCA_MY2020_Tx" SG_ 722 VRM_ComShuffleDiscs_St 1;
BA_ "GenSigSendType" SG_ 722 VRM_ComShuffleDiscs_St 3;
BA_ "U_U55X_MY2022_Tx" SG_ 722 VRM_ComDolbyNR_St 1;
BA_ "U_CD542_MY2021_Tx" SG_ 722 VRM_ComDolbyNR_St 1;
BA_ "U_T6_MCA_MY2020_Tx" SG_ 722 VRM_ComDolbyNR_St 1;
BA_ "GenSigSendType" SG_ 722 VRM_ComDolbyNR_St 3;
BA_ "U_U55X_MY2022_Tx" SG_ 722 VRM_ComSourceSelect_St 1;
BA_ "U_CD542_MY2021_Tx" SG_ 722 VRM_ComSourceSelect_St 1;
BA_ "U_T6_MCA_MY2020_Tx" SG_ 722 VRM_ComSourceSelect_St 1;
BA_ "GenSigSendType" SG_ 722 VRM_ComSourceSelect_St 3;
BA_ "U_U55X_MY2022_Tx" SG_ 722 VRM_ComStFreq_St 1;
BA_ "U_CD542_MY2021_Tx" SG_ 722 VRM_ComStFreq_St 1;
BA_ "U_T6_MCA_MY2020_Tx" SG_ 722 VRM_ComStFreq_St 1;
BA_ "U_U55X_MY2022_Tx" SG_ 722 VRM_ComRouteStrategy_St 1;
BA_ "U_CD542_MY2021_Tx" SG_ 722 VRM_ComRouteStrategy_St 1;
BA_ "U_T6_MCA_MY2020_Tx" SG_ 722 VRM_ComRouteStrategy_St 1;
BA_ "GenSigSendType" SG_ 722 VRM_ComRouteStrategy_St 3;
BA_ "U_U55X_MY2022_Tx" SG_ 721 VRM_BTDefaultPhone_St 1;
BA_ "U_CD542_MY2021_Tx" SG_ 721 VRM_BTDefaultPhone_St 1;
BA_ "U_T6_MCA_MY2020_Tx" SG_ 721 VRM_BTDefaultPhone_St 1;
BA_ "U_U55X_MY2022_Rx" SG_ 721 VRM_BTDefaultPhone_St 1;
BA_ "U_CD542_MY2021_Rx" SG_ 721 VRM_BTDefaultPhone_St 1;
BA_ "U_T6_MCA_MY2020_Rx" SG_ 721 VRM_BTDefaultPhone_St 1;
BA_ "GenSigSendType" SG_ 721 VRM_BTDefaultPhone_St 3;
BA_ "U_U55X_MY2022_Tx" SG_ 721 VRM_DetourUnit_st 1;
BA_ "U_CD542_MY2021_Tx" SG_ 721 VRM_DetourUnit_st 1;
BA_ "U_T6_MCA_MY2020_Tx" SG_ 721 VRM_DetourUnit_st 1;
BA_ "GenSigSendType" SG_ 721 VRM_DetourUnit_st 3;
BA_ "U_U55X_MY2022_Tx" SG_ 721 VRM_Zoom_Option_St 1;
BA_ "U_CD542_MY2021_Tx" SG_ 721 VRM_Zoom_Option_St 1;
BA_ "U_T6_MCA_MY2020_Tx" SG_ 721 VRM_Zoom_Option_St 1;
BA_ "GenSigSendType" SG_ 721 VRM_Zoom_Option_St 3;
BA_ "U_U55X_MY2022_Tx" SG_ 721 VRM_ComBTDTMFTone_St 1;
BA_ "U_CD542_MY2021_Tx" SG_ 721 VRM_ComBTDTMFTone_St 1;
BA_ "U_T6_MCA_MY2020_Tx" SG_ 721 VRM_ComBTDTMFTone_St 1;
BA_ "GenSigSendType" SG_ 721 VRM_ComBTDTMFTone_St 3;
BA_ "U_U55X_MY2022_Tx" SG_ 721 VRM_SuggestedRoute_St 1;
BA_ "U_CD542_MY2021_Tx" SG_ 721 VRM_SuggestedRoute_St 1;
BA_ "U_T6_MCA_MY2020_Tx" SG_ 721 VRM_SuggestedRoute_St 1;
BA_ "GenSigSendType" SG_ 721 VRM_SuggestedRoute_St 3;
BA_ "U_U55X_MY2022_Tx" SG_ 721 VRM_ComDelWaypoint_St 1;
BA_ "U_CD542_MY2021_Tx" SG_ 721 VRM_ComDelWaypoint_St 1;
BA_ "U_T6_MCA_MY2020_Tx" SG_ 721 VRM_ComDelWaypoint_St 1;
BA_ "GenSigSendType" SG_ 721 VRM_ComDelWaypoint_St 3;
BA_ "U_U55X_MY2022_Tx" SG_ 721 VRM_ComSelectDisc_St 1;
BA_ "U_CD542_MY2021_Tx" SG_ 721 VRM_ComSelectDisc_St 1;
BA_ "U_T6_MCA_MY2020_Tx" SG_ 721 VRM_ComSelectDisc_St 1;
BA_ "GenSigSendType" SG_ 721 VRM_ComSelectDisc_St 3;
BA_ "U_U55X_MY2022_Tx" SG_ 721 VRM_ComTelService_St 1;
BA_ "U_CD542_MY2021_Tx" SG_ 721 VRM_ComTelService_St 1;
BA_ "U_T6_MCA_MY2020_Tx" SG_ 721 VRM_ComTelService_St 1;
BA_ "GenSigSendType" SG_ 721 VRM_ComTelService_St 3;
BA_ "U_U55X_MY2022_Tx" SG_ 721 VRM_ComDestHome_St 1;
BA_ "U_CD542_MY2021_Tx" SG_ 721 VRM_ComDestHome_St 1;
BA_ "U_T6_MCA_MY2020_Tx" SG_ 721 VRM_ComDestHome_St 1;
BA_ "GenSigSendType" SG_ 721 VRM_ComDestHome_St 3;
BA_ "U_U55X_MY2022_Tx" SG_ 721 VRM_ComSelectTrack_St 1;
BA_ "U_CD542_MY2021_Tx" SG_ 721 VRM_ComSelectTrack_St 1;
BA_ "U_T6_MCA_MY2020_Tx" SG_ 721 VRM_ComSelectTrack_St 1;
BA_ "U_U55X_MY2022_Tx" SG_ 721 VRM_ComShowNavInfo_St 1;
BA_ "U_CD542_MY2021_Tx" SG_ 721 VRM_ComShowNavInfo_St 1;
BA_ "U_T6_MCA_MY2020_Tx" SG_ 721 VRM_ComShowNavInfo_St 1;
BA_ "GenSigSendType" SG_ 721 VRM_ComShowNavInfo_St 3;
BA_ "U_U55X_MY2022_Tx" SG_ 721 VRM_VoiceRecStatus_St 1;
BA_ "U_CD542_MY2021_Tx" SG_ 721 VRM_VoiceRecStatus_St 1;
BA_ "U_T6_MCA_MY2020_Tx" SG_ 721 VRM_VoiceRecStatus_St 1;
BA_ "GenSigSendType" SG_ 721 VRM_VoiceRecStatus_St 3;
BA_ "U_U55X_MY2022_Tx" SG_ 721 VRM_ComSelTrackSource_St 1;
BA_ "U_CD542_MY2021_Tx" SG_ 721 VRM_ComSelTrackSource_St 1;
BA_ "U_T6_MCA_MY2020_Tx" SG_ 721 VRM_ComSelTrackSource_St 1;
BA_ "GenSigSendType" SG_ 721 VRM_ComSelTrackSource_St 3;
BA_ "U_U55X_MY2022_Tx" SG_ 721 VRM_ComDetour_St 1;
BA_ "U_CD542_MY2021_Tx" SG_ 721 VRM_ComDetour_St 1;
BA_ "U_T6_MCA_MY2020_Tx" SG_ 721 VRM_ComDetour_St 1;
BA_ "GenSigSendType" SG_ 721 VRM_ComDetour_St 3;
BA_ "U_U55X_MY2022_Tx" SG_ 721 VRM_ComDisplay_St 1;
BA_ "U_CD542_MY2021_Tx" SG_ 721 VRM_ComDisplay_St 1;
BA_ "U_T6_MCA_MY2020_Tx" SG_ 721 VRM_ComDisplay_St 1;
BA_ "GenSigSendType" SG_ 721 VRM_ComDisplay_St 3;
BA_ "U_U55X_MY2022_Tx" SG_ 721 VRM_ComDynamicGuidande_St 1;
BA_ "U_CD542_MY2021_Tx" SG_ 721 VRM_ComDynamicGuidande_St 1;
BA_ "U_T6_MCA_MY2020_Tx" SG_ 721 VRM_ComDynamicGuidande_St 1;
BA_ "GenSigSendType" SG_ 721 VRM_ComDynamicGuidande_St 3;
BA_ "U_U55X_MY2022_Tx" SG_ 721 VRM_ComZoom_St 1;
BA_ "U_CD542_MY2021_Tx" SG_ 721 VRM_ComZoom_St 1;
BA_ "U_T6_MCA_MY2020_Tx" SG_ 721 VRM_ComZoom_St 1;
BA_ "GenSigSendType" SG_ 721 VRM_ComZoom_St 3;
BA_ "U_U55X_MY2022_Tx" SG_ 721 VRM_ComCallControl_St 1;
BA_ "U_CD542_MY2021_Tx" SG_ 721 VRM_ComCallControl_St 1;
BA_ "U_T6_MCA_MY2020_Tx" SG_ 721 VRM_ComCallControl_St 1;
BA_ "GenSigSendType" SG_ 721 VRM_ComCallControl_St 3;
BA_ "U_U55X_MY2022_Tx" SG_ 721 VRM_ComGuidance_St 1;
BA_ "U_CD542_MY2021_Tx" SG_ 721 VRM_ComGuidance_St 1;
BA_ "U_T6_MCA_MY2020_Tx" SG_ 721 VRM_ComGuidance_St 1;
BA_ "GenSigSendType" SG_ 721 VRM_ComGuidance_St 3;
BA_ "U_U55X_MY2022_Tx" SG_ 721 VRM_ComTrafficInfDsp_St 1;
BA_ "U_CD542_MY2021_Tx" SG_ 721 VRM_ComTrafficInfDsp_St 1;
BA_ "U_T6_MCA_MY2020_Tx" SG_ 721 VRM_ComTrafficInfDsp_St 1;
BA_ "GenSigSendType" SG_ 721 VRM_ComTrafficInfDsp_St 3;
BA_ "U_U55X_MY2022_Tx" SG_ 720 VRM_PhMicrophoneMute_St 1;
BA_ "U_CD542_MY2021_Tx" SG_ 720 VRM_PhMicrophoneMute_St 1;
BA_ "U_T6_MCA_MY2020_Tx" SG_ 720 VRM_PhMicrophoneMute_St 1;
BA_ "U_U55X_MY2022_Rx" SG_ 720 VRM_PhMicrophoneMute_St 1;
BA_ "U_CD542_MY2021_Rx" SG_ 720 VRM_PhMicrophoneMute_St 1;
BA_ "U_T6_MCA_MY2020_Rx" SG_ 720 VRM_PhMicrophoneMute_St 1;
BA_ "GenSigSendType" SG_ 720 VRM_PhMicrophoneMute_St 3;
BA_ "U_U55X_MY2022_Tx" SG_ 720 Aioc_ExtSrcOutpMode_St 1;
BA_ "U_CD542_MY2021_Tx" SG_ 720 Aioc_ExtSrcOutpMode_St 1;
BA_ "U_T6_MCA_MY2020_Tx" SG_ 720 Aioc_ExtSrcOutpMode_St 1;
BA_ "GenSigSendType" SG_ 720 Aioc_ExtSrcOutpMode_St 3;
BA_ "U_U55X_MY2022_Tx" SG_ 720 VRM_BTPhoneSts_St 1;
BA_ "U_CD542_MY2021_Tx" SG_ 720 VRM_BTPhoneSts_St 1;
BA_ "U_T6_MCA_MY2020_Tx" SG_ 720 VRM_BTPhoneSts_St 1;
BA_ "ECGUsedRxSignal" SG_ 720 VRM_BTPhoneSts_St 1;
BA_ "U_CD542_MY2021_Rx" SG_ 720 VRM_BTPhoneSts_St 1;
BA_ "U_U55X_MY2022_Rx" SG_ 720 VRM_BTPhoneSts_St 1;
BA_ "U_T6_MCA_MY2020_Rx" SG_ 720 VRM_BTPhoneSts_St 1;
BA_ "GenSigSendType" SG_ 720 VRM_BTPhoneSts_St 3;
BA_ "U_U55X_MY2022_Tx" SG_ 720 VRM_SubscribeStatus_St 1;
BA_ "U_CD542_MY2021_Tx" SG_ 720 VRM_SubscribeStatus_St 1;
BA_ "U_T6_MCA_MY2020_Tx" SG_ 720 VRM_SubscribeStatus_St 1;
BA_ "GenSigSendType" SG_ 720 VRM_SubscribeStatus_St 3;
BA_ "U_U55X_MY2022_Tx" SG_ 720 VRM_BlutoothStatus_St 1;
BA_ "U_CD542_MY2021_Tx" SG_ 720 VRM_BlutoothStatus_St 1;
BA_ "U_T6_MCA_MY2020_Tx" SG_ 720 VRM_BlutoothStatus_St 1;
BA_ "U_U55X_MY2022_Rx" SG_ 720 VRM_BlutoothStatus_St 1;
BA_ "U_CD542_MY2021_Rx" SG_ 720 VRM_BlutoothStatus_St 1;
BA_ "U_T6_MCA_MY2020_Rx" SG_ 720 VRM_BlutoothStatus_St 1;
BA_ "GenSigSendType" SG_ 720 VRM_BlutoothStatus_St 3;
BA_ "U_U55X_MY2022_Tx" SG_ 720 VRM_BondRequest_St 1;
BA_ "U_CD542_MY2021_Tx" SG_ 720 VRM_BondRequest_St 1;
BA_ "U_T6_MCA_MY2020_Tx" SG_ 720 VRM_BondRequest_St 1;
BA_ "GenSigSendType" SG_ 720 VRM_BondRequest_St 3;
BA_ "U_U55X_MY2022_Tx" SG_ 720 VRM_VRMMonoOutMode_St 1;
BA_ "U_CD542_MY2021_Tx" SG_ 720 VRM_VRMMonoOutMode_St 1;
BA_ "U_T6_MCA_MY2020_Tx" SG_ 720 VRM_VRMMonoOutMode_St 1;
BA_ "GenSigSendType" SG_ 720 VRM_VRMMonoOutMode_St 3;
BA_ "U_U55X_MY2022_Tx" SG_ 720 VRM_BTNetworkStatus_St 1;
BA_ "U_CD542_MY2021_Tx" SG_ 720 VRM_BTNetworkStatus_St 1;
BA_ "U_T6_MCA_MY2020_Tx" SG_ 720 VRM_BTNetworkStatus_St 1;
BA_ "U_U55X_MY2022_Rx" SG_ 720 VRM_BTNetworkStatus_St 1;
BA_ "U_CD542_MY2021_Rx" SG_ 720 VRM_BTNetworkStatus_St 1;
BA_ "U_T6_MCA_MY2020_Rx" SG_ 720 VRM_BTNetworkStatus_St 1;
BA_ "GenSigSendType" SG_ 720 VRM_BTNetworkStatus_St 3;
BA_ "U_U55X_MY2022_Tx" SG_ 720 VRM_BTSignalStrength_St 1;
BA_ "U_CD542_MY2021_Tx" SG_ 720 VRM_BTSignalStrength_St 1;
BA_ "U_T6_MCA_MY2020_Tx" SG_ 720 VRM_BTSignalStrength_St 1;
BA_ "U_CD542_MY2021_Rx" SG_ 720 VRM_BTSignalStrength_St 1;
BA_ "U_T6_MCA_MY2020_Rx" SG_ 720 VRM_BTSignalStrength_St 1;
BA_ "GenSigSendType" SG_ 720 VRM_BTSignalStrength_St 3;
BA_ "U_U55X_MY2022_Tx" SG_ 720 VRM_BTBatteryLevel_St 1;
BA_ "U_CD542_MY2021_Tx" SG_ 720 VRM_BTBatteryLevel_St 1;
BA_ "U_T6_MCA_MY2020_Tx" SG_ 720 VRM_BTBatteryLevel_St 1;
BA_ "U_CD542_MY2021_Rx" SG_ 720 VRM_BTBatteryLevel_St 1;
BA_ "U_T6_MCA_MY2020_Rx" SG_ 720 VRM_BTBatteryLevel_St 1;
BA_ "GenSigSendType" SG_ 720 VRM_BTBatteryLevel_St 3;
BA_ "U_U55X_MY2022_Tx" SG_ 470 VRM_BTIncomingCall_Rsp 1;
BA_ "U_CD542_MY2021_Tx" SG_ 470 VRM_BTIncomingCall_Rsp 1;
BA_ "U_T6_MCA_MY2020_Tx" SG_ 470 VRM_BTIncomingCall_Rsp 1;
BA_ "U_U55X_MY2022_Rx" SG_ 470 VRM_BTIncomingCall_Rsp 1;
BA_ "U_CD542_MY2021_Rx" SG_ 470 VRM_BTIncomingCall_Rsp 1;
BA_ "U_T6_MCA_MY2020_Rx" SG_ 470 VRM_BTIncomingCall_Rsp 1;
BA_ "GenSigSendType" SG_ 470 VRM_BTIncomingCall_Rsp 3;
BA_ "U_U55X_MY2022_Tx" SG_ 470 VRM_BTEndTelService_Rsp 1;
BA_ "U_CD542_MY2021_Tx" SG_ 470 VRM_BTEndTelService_Rsp 1;
BA_ "U_T6_MCA_MY2020_Tx" SG_ 470 VRM_BTEndTelService_Rsp 1;
BA_ "U_U55X_MY2022_Rx" SG_ 470 VRM_BTEndTelService_Rsp 1;
BA_ "U_CD542_MY2021_Rx" SG_ 470 VRM_BTEndTelService_Rsp 1;
BA_ "U_T6_MCA_MY2020_Rx" SG_ 470 VRM_BTEndTelService_Rsp 1;
BA_ "GenSigSendType" SG_ 470 VRM_BTEndTelService_Rsp 3;
BA_ "U_U55X_MY2022_Tx" SG_ 1978 TesterPhysicalResHUD_ADV 1;
BA_ "U_T6_MCA_MY2020_Tx" SG_ 1978 TesterPhysicalResHUD_ADV 1;
BA_ "GenSigSendType" SG_ 1978 TesterPhysicalResHUD_ADV 3;
BA_ "U_U55X_MY2022_Rx" SG_ 1970 TesterPhysicalReqHUD_ADV 1;
BA_ "U_T6_MCA_MY2020_Rx" SG_ 1970 TesterPhysicalReqHUD_ADV 1;
BA_ "GenSigSendType" SG_ 1970 TesterPhysicalReqHUD_ADV 3;
BA_ "U_CD542_MY2021_Tx" SG_ 758 SDARS_OpMode_St 1;
BA_ "U_T6_MCA_MY2020_Tx" SG_ 758 SDARS_OpMode_St 1;
BA_ "U_P702_MY2021_Tx" SG_ 758 SDARS_OpMode_St 1;
BA_ "U_U55X_MY2022_Rx" SG_ 758 SDARS_OpMode_St 1;
BA_ "U_CD542_MY2021_Rx" SG_ 758 SDARS_OpMode_St 1;
BA_ "U_T6_MCA_MY2020_Rx" SG_ 758 SDARS_OpMode_St 1;
BA_ "GenSigSendType" SG_ 758 SDARS_OpMode_St 3;
BA_ "U_CD542_MY2021_Tx" SG_ 758 SDARS_SetCategory_St 1;
BA_ "U_T6_MCA_MY2020_Tx" SG_ 758 SDARS_SetCategory_St 1;
BA_ "U_P702_MY2021_Tx" SG_ 758 SDARS_SetCategory_St 1;
BA_ "U_U55X_MY2022_Rx" SG_ 758 SDARS_SetCategory_St 1;
BA_ "U_CD542_MY2021_Rx" SG_ 758 SDARS_SetCategory_St 1;
BA_ "U_T6_MCA_MY2020_Rx" SG_ 758 SDARS_SetCategory_St 1;
BA_ "GenSigSendType" SG_ 758 SDARS_SetCategory_St 3;
BA_ "U_CD542_MY2021_Tx" SG_ 758 SDARS_GCI_Update_Prg_St 1;
BA_ "U_T6_MCA_MY2020_Tx" SG_ 758 SDARS_GCI_Update_Prg_St 1;
BA_ "U_P702_MY2021_Tx" SG_ 758 SDARS_GCI_Update_Prg_St 1;
BA_ "U_U55X_MY2022_Rx" SG_ 758 SDARS_GCI_Update_Prg_St 1;
BA_ "U_CD542_MY2021_Rx" SG_ 758 SDARS_GCI_Update_Prg_St 1;
BA_ "U_T6_MCA_MY2020_Rx" SG_ 758 SDARS_GCI_Update_Prg_St 1;
BA_ "GenSigSendType" SG_ 758 SDARS_GCI_Update_Prg_St 3;
BA_ "U_CD542_MY2021_Tx" SG_ 758 SDARS_Factory_Reset_St 1;
BA_ "U_T6_MCA_MY2020_Tx" SG_ 758 SDARS_Factory_Reset_St 1;
BA_ "U_P702_MY2021_Tx" SG_ 758 SDARS_Factory_Reset_St 1;
BA_ "U_U55X_MY2022_Rx" SG_ 758 SDARS_Factory_Reset_St 1;
BA_ "U_CD542_MY2021_Rx" SG_ 758 SDARS_Factory_Reset_St 1;
BA_ "U_T6_MCA_MY2020_Rx" SG_ 758 SDARS_Factory_Reset_St 1;
BA_ "GenSigSendType" SG_ 758 SDARS_Factory_Reset_St 3;
BA_ "U_CD542_MY2021_Tx" SG_ 760 SDARS_SID_St 1;
BA_ "U_T6_MCA_MY2020_Tx" SG_ 760 SDARS_SID_St 1;
BA_ "U_P702_MY2021_Tx" SG_ 760 SDARS_SID_St 1;
BA_ "U_U55X_MY2022_Rx" SG_ 760 SDARS_SID_St 1;
BA_ "U_CD542_MY2021_Rx" SG_ 760 SDARS_SID_St 1;
BA_ "U_T6_MCA_MY2020_Rx" SG_ 760 SDARS_SID_St 1;
BA_ "U_CD542_MY2021_Tx" SG_ 760 SDARS_CurrentChanNum_St 1;
BA_ "U_T6_MCA_MY2020_Tx" SG_ 760 SDARS_CurrentChanNum_St 1;
BA_ "U_P702_MY2021_Tx" SG_ 760 SDARS_CurrentChanNum_St 1;
BA_ "U_U55X_MY2022_Rx" SG_ 760 SDARS_CurrentChanNum_St 1;
BA_ "U_CD542_MY2021_Rx" SG_ 760 SDARS_CurrentChanNum_St 1;
BA_ "U_T6_MCA_MY2020_Rx" SG_ 760 SDARS_CurrentChanNum_St 1;
BA_ "U_CD542_MY2021_Tx" SG_ 760 SDARS_Buffer_sec_St 1;
BA_ "U_T6_MCA_MY2020_Tx" SG_ 760 SDARS_Buffer_sec_St 1;
BA_ "U_P702_MY2021_Tx" SG_ 760 SDARS_Buffer_sec_St 1;
BA_ "U_U55X_MY2022_Rx" SG_ 760 SDARS_Buffer_sec_St 1;
BA_ "U_CD542_MY2021_Rx" SG_ 760 SDARS_Buffer_sec_St 1;
BA_ "U_T6_MCA_MY2020_Rx" SG_ 760 SDARS_Buffer_sec_St 1;
BA_ "U_CD542_MY2021_Tx" SG_ 760 SDARS_Buffer_min_St 1;
BA_ "U_T6_MCA_MY2020_Tx" SG_ 760 SDARS_Buffer_min_St 1;
BA_ "U_P702_MY2021_Tx" SG_ 760 SDARS_Buffer_min_St 1;
BA_ "U_U55X_MY2022_Rx" SG_ 760 SDARS_Buffer_min_St 1;
BA_ "U_CD542_MY2021_Rx" SG_ 760 SDARS_Buffer_min_St 1;
BA_ "U_T6_MCA_MY2020_Rx" SG_ 760 SDARS_Buffer_min_St 1;
BA_ "U_CD542_MY2021_Tx" SG_ 760 SDARS_Buffer_hr_St 1;
BA_ "U_T6_MCA_MY2020_Tx" SG_ 760 SDARS_Buffer_hr_St 1;
BA_ "U_P702_MY2021_Tx" SG_ 760 SDARS_Buffer_hr_St 1;
BA_ "U_U55X_MY2022_Rx" SG_ 760 SDARS_Buffer_hr_St 1;
BA_ "U_CD542_MY2021_Rx" SG_ 760 SDARS_Buffer_hr_St 1;
BA_ "U_T6_MCA_MY2020_Rx" SG_ 760 SDARS_Buffer_hr_St 1;
BA_ "U_CD542_MY2021_Tx" SG_ 760 SDARS_Playback_St 1;
BA_ "U_T6_MCA_MY2020_Tx" SG_ 760 SDARS_Playback_St 1;
BA_ "U_P702_MY2021_Tx" SG_ 760 SDARS_Playback_St 1;
BA_ "U_U55X_MY2022_Rx" SG_ 760 SDARS_Playback_St 1;
BA_ "U_CD542_MY2021_Rx" SG_ 760 SDARS_Playback_St 1;
BA_ "U_T6_MCA_MY2020_Rx" SG_ 760 SDARS_Playback_St 1;
BA_ "U_CD542_MY2021_Tx" SG_ 760 SDARS_FillPosition_St 1;
BA_ "U_T6_MCA_MY2020_Tx" SG_ 760 SDARS_FillPosition_St 1;
BA_ "U_P702_MY2021_Tx" SG_ 760 SDARS_FillPosition_St 1;
BA_ "U_U55X_MY2022_Rx" SG_ 760 SDARS_FillPosition_St 1;
BA_ "U_CD542_MY2021_Rx" SG_ 760 SDARS_FillPosition_St 1;
BA_ "U_T6_MCA_MY2020_Rx" SG_ 760 SDARS_FillPosition_St 1;
BA_ "U_CD542_MY2021_Tx" SG_ 760 SDARS_Alert_Status 1;
BA_ "U_T6_MCA_MY2020_Tx" SG_ 760 SDARS_Alert_Status 1;
BA_ "U_P702_MY2021_Tx" SG_ 760 SDARS_Alert_Status 1;
BA_ "U_U55X_MY2022_Rx" SG_ 760 SDARS_Alert_Status 1;
BA_ "U_CD542_MY2021_Rx" SG_ 760 SDARS_Alert_Status 1;
BA_ "U_T6_MCA_MY2020_Rx" SG_ 760 SDARS_Alert_Status 1;
BA_ "GenSigSendType" SG_ 760 SDARS_Alert_Status 3;
BA_ "U_CD542_MY2021_Tx" SG_ 760 SDARS_Channel_Lock 1;
BA_ "U_T6_MCA_MY2020_Tx" SG_ 760 SDARS_Channel_Lock 1;
BA_ "U_P702_MY2021_Tx" SG_ 760 SDARS_Channel_Lock 1;
BA_ "U_U55X_MY2022_Rx" SG_ 760 SDARS_Channel_Lock 1;
BA_ "U_CD542_MY2021_Rx" SG_ 760 SDARS_Channel_Lock 1;
BA_ "U_T6_MCA_MY2020_Rx" SG_ 760 SDARS_Channel_Lock 1;
BA_ "GenSigSendType" SG_ 760 SDARS_Channel_Lock 3;
BA_ "U_U55X_MY2022_Tx" SG_ 705 SDARS_RDISP_WORD_Tx 1;
BA_ "U_CD542_MY2021_Tx" SG_ 705 SDARS_RDISP_WORD_Tx 1;
BA_ "U_T6_MCA_MY2020_Tx" SG_ 705 SDARS_RDISP_WORD_Tx 1;
BA_ "U_P702_MY2021_Tx" SG_ 705 SDARS_RDISP_WORD_Tx 1;
BA_ "U_U55X_MY2022_Rx" SG_ 705 SDARS_RDISP_WORD_Tx 1;
BA_ "U_CD542_MY2021_Rx" SG_ 705 SDARS_RDISP_WORD_Tx 1;
BA_ "U_T6_MCA_MY2020_Rx" SG_ 705 SDARS_RDISP_WORD_Tx 1;
BA_ "U_P702_MY2021_Rx" SG_ 705 SDARS_RDISP_WORD_Tx 1;
BA_ "U_U55X_MY2022_Tx" SG_ 692 AUDIO_RDISP_WORD_Tx 1;
BA_ "U_CD542_MY2021_Tx" SG_ 692 AUDIO_RDISP_WORD_Tx 1;
BA_ "U_T6_MCA_MY2020_Tx" SG_ 692 AUDIO_RDISP_WORD_Tx 1;
BA_ "U_P702_MY2021_Tx" SG_ 692 AUDIO_RDISP_WORD_Tx 1;
BA_ "U_U55X_MY2022_Rx" SG_ 692 AUDIO_RDISP_WORD_Tx 1;
BA_ "U_CD542_MY2021_Rx" SG_ 692 AUDIO_RDISP_WORD_Tx 1;
BA_ "U_T6_MCA_MY2020_Rx" SG_ 692 AUDIO_RDISP_WORD_Tx 1;
BA_ "U_P702_MY2021_Rx" SG_ 692 AUDIO_RDISP_WORD_Tx 1;
BA_ "U_U55X_MY2022_Tx" SG_ 1837 TesterPhysicalResWCM 1;
BA_ "U_CD542_MY2021_Tx" SG_ 1837 TesterPhysicalResWCM 1;
BA_ "U_T6_MCA_MY2020_Tx" SG_ 1837 TesterPhysicalResWCM 1;
BA_ "U_P702_MY2021_Tx" SG_ 1837 TesterPhysicalResWCM 1;
BA_ "U_CX727_MY2021_Tx" SG_ 1837 TesterPhysicalResWCM 1;
BA_ "GenSigSendType" SG_ 1837 TesterPhysicalResWCM 3;
BA_ "U_CD542_MY2021_Rx" SG_ 523 WaterInFuel_B_Falt_UB 1;
BA_ "U_T6_MCA_MY2020_Rx" SG_ 523 WaterInFuel_B_Falt_UB 1;
BA_ "U_P702_MY2021_Rx" SG_ 523 WaterInFuel_B_Falt_UB 1;
BA_ "U_CD542_MY2021_Rx" SG_ 523 WaterInFuel_B_Falt 1;
BA_ "U_T6_MCA_MY2020_Rx" SG_ 523 WaterInFuel_B_Falt 1;
BA_ "U_P702_MY2021_Rx" SG_ 523 WaterInFuel_B_Falt 1;
BA_ "U_CD542_MY2021_Rx" SG_ 523 UreaMxAdd_L2_Actl_UB 1;
BA_ "U_T6_MCA_MY2020_Rx" SG_ 523 UreaMxAdd_L2_Actl_UB 1;
BA_ "U_P702_MY2021_Rx" SG_ 523 UreaMxAdd_L2_Actl_UB 1;
BA_ "U_CD542_MY2021_Rx" SG_ 523 VehUreaRnge3_L_DsplyMx_UB 1;
BA_ "U_T6_MCA_MY2020_Rx" SG_ 523 VehUreaRnge3_L_DsplyMx_UB 1;
BA_ "U_P702_MY2021_Rx" SG_ 523 VehUreaRnge3_L_DsplyMx_UB 1;
BA_ "U_CD542_MY2021_Rx" SG_ 523 UreaMnAdd_L2_Actl_UB 1;
BA_ "U_T6_MCA_MY2020_Rx" SG_ 523 UreaMnAdd_L2_Actl_UB 1;
BA_ "U_P702_MY2021_Rx" SG_ 523 UreaMnAdd_L2_Actl_UB 1;
BA_ "U_CD542_MY2021_Rx" SG_ 523 UreaMnAdd_L2_Actl 1;
BA_ "U_T6_MCA_MY2020_Rx" SG_ 523 UreaMnAdd_L2_Actl 1;
BA_ "U_P702_MY2021_Rx" SG_ 523 UreaMnAdd_L2_Actl 1;
BA_ "U_CD542_MY2021_Rx" SG_ 523 VehUreaRnge3_L_DsplyMx 1;
BA_ "U_T6_MCA_MY2020_Rx" SG_ 523 VehUreaRnge3_L_DsplyMx 1;
BA_ "U_P702_MY2021_Rx" SG_ 523 VehUreaRnge3_L_DsplyMx 1;
BA_ "U_CD542_MY2021_Rx" SG_ 523 UreaMxAdd_L2_Actl 1;
BA_ "U_T6_MCA_MY2020_Rx" SG_ 523 UreaMxAdd_L2_Actl 1;
BA_ "U_P702_MY2021_Rx" SG_ 523 UreaMxAdd_L2_Actl 1;
BA_ "GenSigStartValue" SG_ 523 UreaMxAdd_L2_Actl 510;
BA_ "GenSigStartValueInteger" SG_ 523 UreaMxAdd_L2_Actl 510;
BA_ "U_U55X_MY2022_Rx" SG_ 942 ApaOffOptnSel_B_Avail 1;
BA_ "GenSigStartValue" SG_ 942 ApaOffOptnSel_B_Avail 1;
BA_ "U_U55X_MY2022_Rx" SG_ 942 ApaDrvRq2MsgTxt_D_Rq 1;
BA_ "U_U55X_MY2022_Rx" SG_ 942 ApaDrvRq1MsgTxt_D_Rq 1;
BA_ "U_U55X_MY2022_Rx" SG_ 942 ApaSys_D2_Stat 1;
BA_ "U_U55X_MY2022_Rx" SG_ 942 ApaSlotTrgt_D_Stat 1;
BA_ "U_U55X_MY2022_Rx" SG_ 942 ApaSlotOption_B_Avail 1;
BA_ "U_U55X_MY2022_Rx" SG_ 942 ApaSlotAlrtSet_B_Stat 1;
BA_ "U_U55X_MY2022_Rx" SG_ 942 ApaSlotAlrt_B_Rq 1;
BA_ "U_U55X_MY2022_Rx" SG_ 942 ApaRmtFeatSel_B_Avail 1;
BA_ "U_U55X_MY2022_Rx" SG_ 942 ApaParkOutSel_B_Avail 1;
BA_ "U_U55X_MY2022_Rx" SG_ 942 ApaParkInSel_B_Avail 1;
BA_ "U_U55X_MY2022_Rx" SG_ 942 ApaMsgTxt_D2_Stat 1;
BA_ "U_U55X_MY2022_Rx" SG_ 942 ApaDynmcSlot_B_Stat 1;
BA_ "U_U55X_MY2022_Rx" SG_ 942 ApaDisplayMode_D_Stat 1;
BA_ "U_U55X_MY2022_Rx" SG_ 942 ApaControlMode_D_Stat 1;
BA_ "U_U55X_MY2022_Rx" SG_ 942 PrkAidAcsyRear_D_Stat 1;
BA_ "U_CD542_MY2021_Rx" SG_ 942 PrkAidAcsyRear_D_Stat 1;
BA_ "U_T6_MCA_MY2020_Rx" SG_ 942 PrkAidAcsyRear_D_Stat 1;
BA_ "U_P702_MY2021_Rx" SG_ 942 PrkAidAcsyRear_D_Stat 1;
BA_ "U_U55X_MY2022_Rx" SG_ 942 PrkAidAcsyFront_D_Stat 1;
BA_ "U_CD542_MY2021_Rx" SG_ 942 PrkAidAcsyFront_D_Stat 1;
BA_ "U_T6_MCA_MY2020_Rx" SG_ 942 PrkAidAcsyFront_D_Stat 1;
BA_ "U_P702_MY2021_Rx" SG_ 942 PrkAidAcsyFront_D_Stat 1;
BA_ "U_U55X_MY2022_Rx" SG_ 942 PrkAidRdiusRight_L_Dsply 1;
BA_ "U_CD542_MY2021_Rx" SG_ 942 PrkAidRdiusRight_L_Dsply 1;
BA_ "U_T6_MCA_MY2020_Rx" SG_ 942 PrkAidRdiusRight_L_Dsply 1;
BA_ "U_P702_MY2021_Rx" SG_ 942 PrkAidRdiusRight_L_Dsply 1;
BA_ "U_U55X_MY2022_Rx" SG_ 942 PrkAidRdiusLeft_L_Dsply 1;
BA_ "U_CD542_MY2021_Rx" SG_ 942 PrkAidRdiusLeft_L_Dsply 1;
BA_ "U_T6_MCA_MY2020_Rx" SG_ 942 PrkAidRdiusLeft_L_Dsply 1;
BA_ "U_P702_MY2021_Rx" SG_ 942 PrkAidRdiusLeft_L_Dsply 1;
BA_ "U_U55X_MY2022_Rx" SG_ 942 PrkAidDrvDir_D_Stat 1;
BA_ "U_CD542_MY2021_Rx" SG_ 942 PrkAidDrvDir_D_Stat 1;
BA_ "U_T6_MCA_MY2020_Rx" SG_ 942 PrkAidDrvDir_D_Stat 1;
BA_ "U_P702_MY2021_Rx" SG_ 942 PrkAidDrvDir_D_Stat 1;
BA_ "U_U55X_MY2022_Rx" SG_ 634 EngAirFiltMsgTxt_D_Rq_UB 1;
BA_ "U_CD542_MY2021_Rx" SG_ 634 EngAirFiltMsgTxt_D_Rq_UB 1;
BA_ "U_T6_MCA_MY2020_Rx" SG_ 634 EngAirFiltMsgTxt_D_Rq_UB 1;
BA_ "U_P702_MY2021_Rx" SG_ 634 EngAirFiltMsgTxt_D_Rq_UB 1;
BA_ "U_U55X_MY2022_Rx" SG_ 634 EngAirFiltMsgTxt_D_Rq 1;
BA_ "U_CD542_MY2021_Rx" SG_ 634 EngAirFiltMsgTxt_D_Rq 1;
BA_ "U_T6_MCA_MY2020_Rx" SG_ 634 EngAirFiltMsgTxt_D_Rq 1;
BA_ "U_P702_MY2021_Rx" SG_ 634 EngAirFiltMsgTxt_D_Rq 1;
BA_ "U_U55X_MY2022_Rx" SG_ 634 AutoHoldSwMde_B_Ind_UB 1;
BA_ "U_CD542_MY2021_Rx" SG_ 634 AutoHoldSwMde_B_Ind_UB 1;
BA_ "U_T6_MCA_MY2020_Rx" SG_ 634 AutoHoldSwMde_B_Ind_UB 1;
BA_ "U_P702_MY2021_Rx" SG_ 634 AutoHoldSwMde_B_Ind_UB 1;
BA_ "U_U55X_MY2022_Rx" SG_ 634 AutoHoldSwMde_B_Ind 1;
BA_ "U_CD542_MY2021_Rx" SG_ 634 AutoHoldSwMde_B_Ind 1;
BA_ "U_T6_MCA_MY2020_Rx" SG_ 634 AutoHoldSwMde_B_Ind 1;
BA_ "U_P702_MY2021_Rx" SG_ 634 AutoHoldSwMde_B_Ind 1;
BA_ "GenSigSendType" SG_ 634 AutoHoldSwMde_B_Ind 3;
BA_ "ContentDependant" SG_ 634 AutoHoldSwMde_B_Ind 1;
BA_ "U_U55X_MY2022_Rx" SG_ 634 Ccd_B_Falt_UB 1;
BA_ "U_CD542_MY2021_Rx" SG_ 634 Ccd_B_Falt_UB 1;
BA_ "U_T6_MCA_MY2020_Rx" SG_ 634 Ccd_B_Falt_UB 1;
BA_ "U_U55X_MY2022_Rx" SG_ 634 Ccd_B_Falt 1;
BA_ "U_CD542_MY2021_Rx" SG_ 634 Ccd_B_Falt 1;
BA_ "U_T6_MCA_MY2020_Rx" SG_ 634 Ccd_B_Falt 1;
BA_ "GenSigSendType" SG_ 634 Ccd_B_Falt 3;
BA_ "U_CD542_MY2021_Rx" SG_ 634 RearDiffLckLamp_D_Rq3_UB 1;
BA_ "U_T6_MCA_MY2020_Rx" SG_ 634 RearDiffLckLamp_D_Rq3_UB 1;
BA_ "U_CD542_MY2021_Rx" SG_ 634 AwdLckLamp_D_Rq_UB 1;
BA_ "U_T6_MCA_MY2020_Rx" SG_ 634 AwdLckLamp_D_Rq_UB 1;
BA_ "U_CD542_MY2021_Rx" SG_ 634 RearDiffLckLamp_D_Rq3 1;
BA_ "U_T6_MCA_MY2020_Rx" SG_ 634 RearDiffLckLamp_D_Rq3 1;
BA_ "GenSigSendType" SG_ 634 RearDiffLckLamp_D_Rq3 3;
BA_ "U_CD542_MY2021_Rx" SG_ 634 AwdLckLamp_D_Rq 1;
BA_ "U_T6_MCA_MY2020_Rx" SG_ 634 AwdLckLamp_D_Rq 1;
BA_ "GenSigSendType" SG_ 634 AwdLckLamp_D_Rq 3;
BA_ "U_CD542_MY2021_Rx" SG_ 634 AutoTowAllw_D_StatMnu_UB 1;
BA_ "U_CD542_MY2021_Rx" SG_ 634 AutoTowAllw_D_StatMnu 1;
BA_ "GenSigSendType" SG_ 634 AutoTowAllw_D_StatMnu 3;
BA_ "U_CD542_MY2021_Rx" SG_ 634 AutoTowActv_B_Stat 1;
BA_ "GenSigSendType" SG_ 634 AutoTowActv_B_Stat 3;
BA_ "U_CD542_MY2021_Rx" SG_ 634 AutoTowActv_B_Stat_UB 1;
BA_ "U_U55X_MY2022_Rx" SG_ 634 LdwChime_B_Rq_UB 1;
BA_ "U_CD542_MY2021_Rx" SG_ 634 LdwChime_B_Rq_UB 1;
BA_ "U_T6_MCA_MY2020_Rx" SG_ 634 LdwChime_B_Rq_UB 1;
BA_ "U_P702_MY2021_Rx" SG_ 634 LdwChime_B_Rq_UB 1;
BA_ "U_U55X_MY2022_Rx" SG_ 634 HdcOn_B_Ind 1;
BA_ "U_CD542_MY2021_Rx" SG_ 634 HdcOn_B_Ind 1;
BA_ "U_T6_MCA_MY2020_Rx" SG_ 634 HdcOn_B_Ind 1;
BA_ "U_P702_MY2021_Rx" SG_ 634 HdcOn_B_Ind 1;
BA_ "GenSigSendType" SG_ 634 HdcOn_B_Ind 3;
BA_ "U_U55X_MY2022_Rx" SG_ 634 HdcOn_B_Ind_UB 1;
BA_ "U_CD542_MY2021_Rx" SG_ 634 HdcOn_B_Ind_UB 1;
BA_ "U_T6_MCA_MY2020_Rx" SG_ 634 HdcOn_B_Ind_UB 1;
BA_ "U_P702_MY2021_Rx" SG_ 634 HdcOn_B_Ind_UB 1;
BA_ "U_CD542_MY2021_Rx" SG_ 634 SuspVLimMsgTxt_B_Rq_UB 1;
BA_ "U_CD542_MY2021_Rx" SG_ 634 SuspVlimMsgTxt_B_Rq 1;
BA_ "U_T6_MCA_MY2020_Rx" SG_ 634 SuspVlimMsgTxt_B_Rq 1;
BA_ "GenSigSendType" SG_ 634 SuspVlimMsgTxt_B_Rq 3;
BA_ "U_U55X_MY2022_Rx" SG_ 634 EngExhMdeQuiet_D2_Stat_UB 1;
BA_ "U_CD542_MY2021_Rx" SG_ 634 EngExhMdeQuiet_D2_Stat_UB 1;
BA_ "U_T6_MCA_MY2020_Rx" SG_ 634 EngExhMdeQuiet_D2_Stat_UB 1;
BA_ "U_U55X_MY2022_Rx" SG_ 634 EngExhMdeQuiet_D2_Stat 1;
BA_ "U_CD542_MY2021_Rx" SG_ 634 EngExhMdeQuiet_D2_Stat 1;
BA_ "U_T6_MCA_MY2020_Rx" SG_ 634 EngExhMdeQuiet_D2_Stat 1;
BA_ "GenSigSendType" SG_ 634 EngExhMdeQuiet_D2_Stat 3;
BA_ "U_U55X_MY2022_Rx" SG_ 634 ChrgCrdLck_D_Falt_UB 1;
BA_ "U_T6_MCA_MY2020_Rx" SG_ 634 ChrgCrdLck_D_Falt_UB 1;
BA_ "U_CD542_MY2021_Rx" SG_ 634 ChrgCrdLck_D_Falt_UB 1;
BA_ "U_U55X_MY2022_Rx" SG_ 634 LdwChime_B_Rq 1;
BA_ "U_CD542_MY2021_Rx" SG_ 634 LdwChime_B_Rq 1;
BA_ "U_T6_MCA_MY2020_Rx" SG_ 634 LdwChime_B_Rq 1;
BA_ "U_P702_MY2021_Rx" SG_ 634 LdwChime_B_Rq 1;
BA_ "GenSigSendType" SG_ 634 LdwChime_B_Rq 3;
BA_ "U_U55X_MY2022_Rx" SG_ 634 ChrgCrdLck_D_Falt 1;
BA_ "U_T6_MCA_MY2020_Rx" SG_ 634 ChrgCrdLck_D_Falt 1;
BA_ "U_CD542_MY2021_Rx" SG_ 634 ChrgCrdLck_D_Falt 1;
BA_ "GenSigSendType" SG_ 634 ChrgCrdLck_D_Falt 3;
BA_ "ContentDependant" SG_ 1088 HvacPrecondMode2_D_Rq 1;
BA_ "WakeupSignal" SG_ 1088 HvacPrecondMode2_D_Rq 1;
BA_ "ContentDependant" SG_ 1088 HvacPrecondBlwr2_D_Rq 1;
BA_ "WakeupSignal" SG_ 1088 HvacPrecondBlwr2_D_Rq 1;
BA_ "GenSigStartValue" SG_ 1088 HvacPrecond_Te_Rq 2;
BA_ "GenSigStartValueInteger" SG_ 1088 HvacPrecond_Te_Rq 2;
BA_ "U_U55X_MY2022_Rx" SG_ 1088 ChrgStat_D2_Dsply 1;
BA_ "U_P702_MY2021_Rx" SG_ 1088 ChrgStat_D2_Dsply 1;
BA_ "U_CD542_MY2021_Rx" SG_ 1088 ChrgStat_D2_Dsply 1;
BA_ "U_T6_MCA_MY2020_Rx" SG_ 1088 ChrgStat_D2_Dsply 1;
BA_ "U_CD542_MY2021_Rx" SG_ 1088 ChrgTMatch_B_Stat 1;
BA_ "U_T6_MCA_MY2020_Rx" SG_ 1088 ChrgTMatch_B_Stat 1;
BA_ "GenSigStartValue" SG_ 1088 BattDcChrgRms_I_Lim 32766;
BA_ "U_U55X_MY2022_Tx" SG_ 706 SDARS_MC_WORD_Tx 1;
BA_ "U_CD542_MY2021_Tx" SG_ 706 SDARS_MC_WORD_Tx 1;
BA_ "U_T6_MCA_MY2020_Tx" SG_ 706 SDARS_MC_WORD_Tx 1;
BA_ "U_P702_MY2021_Tx" SG_ 706 SDARS_MC_WORD_Tx 1;
BA_ "U_U55X_MY2022_Rx" SG_ 706 SDARS_MC_WORD_Tx 1;
BA_ "U_CD542_MY2021_Rx" SG_ 706 SDARS_MC_WORD_Tx 1;
BA_ "U_T6_MCA_MY2020_Rx" SG_ 706 SDARS_MC_WORD_Tx 1;
BA_ "U_CD542_MY2021_Tx" SG_ 761 SDARS_Seek_Scan_St 1;
BA_ "U_T6_MCA_MY2020_Tx" SG_ 761 SDARS_Seek_Scan_St 1;
BA_ "U_P702_MY2021_Tx" SG_ 761 SDARS_Seek_Scan_St 1;
BA_ "U_U55X_MY2022_Rx" SG_ 761 SDARS_Seek_Scan_St 1;
BA_ "U_CD542_MY2021_Rx" SG_ 761 SDARS_Seek_Scan_St 1;
BA_ "U_T6_MCA_MY2020_Rx" SG_ 761 SDARS_Seek_Scan_St 1;
BA_ "GenSigSendType" SG_ 761 SDARS_Seek_Scan_St 3;
BA_ "U_CD542_MY2021_Tx" SG_ 761 SDARS_Invalid_Chan_St 1;
BA_ "U_T6_MCA_MY2020_Tx" SG_ 761 SDARS_Invalid_Chan_St 1;
BA_ "U_P702_MY2021_Tx" SG_ 761 SDARS_Invalid_Chan_St 1;
BA_ "U_U55X_MY2022_Rx" SG_ 761 SDARS_Invalid_Chan_St 1;
BA_ "U_CD542_MY2021_Rx" SG_ 761 SDARS_Invalid_Chan_St 1;
BA_ "U_T6_MCA_MY2020_Rx" SG_ 761 SDARS_Invalid_Chan_St 1;
BA_ "GenSigSendType" SG_ 761 SDARS_Invalid_Chan_St 3;
BA_ "U_CD542_MY2021_Tx" SG_ 761 SDARS_UnSubscrb_Chan_St 1;
BA_ "U_T6_MCA_MY2020_Tx" SG_ 761 SDARS_UnSubscrb_Chan_St 1;
BA_ "U_P702_MY2021_Tx" SG_ 761 SDARS_UnSubscrb_Chan_St 1;
BA_ "U_U55X_MY2022_Rx" SG_ 761 SDARS_UnSubscrb_Chan_St 1;
BA_ "U_CD542_MY2021_Rx" SG_ 761 SDARS_UnSubscrb_Chan_St 1;
BA_ "U_T6_MCA_MY2020_Rx" SG_ 761 SDARS_UnSubscrb_Chan_St 1;
BA_ "GenSigSendType" SG_ 761 SDARS_UnSubscrb_Chan_St 3;
BA_ "U_CD542_MY2021_Tx" SG_ 761 SDARS_Loss_Ant_St 1;
BA_ "U_T6_MCA_MY2020_Tx" SG_ 761 SDARS_Loss_Ant_St 1;
BA_ "U_P702_MY2021_Tx" SG_ 761 SDARS_Loss_Ant_St 1;
BA_ "U_U55X_MY2022_Rx" SG_ 761 SDARS_Loss_Ant_St 1;
BA_ "U_CD542_MY2021_Rx" SG_ 761 SDARS_Loss_Ant_St 1;
BA_ "U_T6_MCA_MY2020_Rx" SG_ 761 SDARS_Loss_Ant_St 1;
BA_ "GenSigSendType" SG_ 761 SDARS_Loss_Ant_St 3;
BA_ "U_CD542_MY2021_Tx" SG_ 761 SDARS_UnSubscrb_St 1;
BA_ "U_T6_MCA_MY2020_Tx" SG_ 761 SDARS_UnSubscrb_St 1;
BA_ "U_P702_MY2021_Tx" SG_ 761 SDARS_UnSubscrb_St 1;
BA_ "U_U55X_MY2022_Rx" SG_ 761 SDARS_UnSubscrb_St 1;
BA_ "U_CD542_MY2021_Rx" SG_ 761 SDARS_UnSubscrb_St 1;
BA_ "U_T6_MCA_MY2020_Rx" SG_ 761 SDARS_UnSubscrb_St 1;
BA_ "GenSigSendType" SG_ 761 SDARS_UnSubscrb_St 3;
BA_ "U_CD542_MY2021_Tx" SG_ 761 SDARS_Subscription_St 1;
BA_ "U_T6_MCA_MY2020_Tx" SG_ 761 SDARS_Subscription_St 1;
BA_ "U_P702_MY2021_Tx" SG_ 761 SDARS_Subscription_St 1;
BA_ "U_U55X_MY2022_Rx" SG_ 761 SDARS_Subscription_St 1;
BA_ "U_CD542_MY2021_Rx" SG_ 761 SDARS_Subscription_St 1;
BA_ "U_T6_MCA_MY2020_Rx" SG_ 761 SDARS_Subscription_St 1;
BA_ "GenSigSendType" SG_ 761 SDARS_Subscription_St 3;
BA_ "U_CD542_MY2021_Tx" SG_ 761 SDARS_GCI_Update_St 1;
BA_ "U_T6_MCA_MY2020_Tx" SG_ 761 SDARS_GCI_Update_St 1;
BA_ "U_P702_MY2021_Tx" SG_ 761 SDARS_GCI_Update_St 1;
BA_ "U_U55X_MY2022_Rx" SG_ 761 SDARS_GCI_Update_St 1;
BA_ "U_CD542_MY2021_Rx" SG_ 761 SDARS_GCI_Update_St 1;
BA_ "U_T6_MCA_MY2020_Rx" SG_ 761 SDARS_GCI_Update_St 1;
BA_ "GenSigSendType" SG_ 761 SDARS_GCI_Update_St 3;
BA_ "U_T6_MCA_MY2020_Tx" SG_ 761 SDARS_Firmware_Updat_St 1;
BA_ "U_P702_MY2021_Tx" SG_ 761 SDARS_Firmware_Updat_St 1;
BA_ "U_U55X_MY2022_Rx" SG_ 761 SDARS_Firmware_Updat_St 1;
BA_ "U_CD542_MY2021_Rx" SG_ 761 SDARS_Firmware_Updat_St 1;
BA_ "U_T6_MCA_MY2020_Rx" SG_ 761 SDARS_Firmware_Updat_St 1;
BA_ "GenSigSendType" SG_ 761 SDARS_Firmware_Updat_St 3;
BA_ "U_CD542_MY2021_Tx" SG_ 761 SDARS_Antenna_Err_St 1;
BA_ "U_T6_MCA_MY2020_Tx" SG_ 761 SDARS_Antenna_Err_St 1;
BA_ "U_P702_MY2021_Tx" SG_ 761 SDARS_Antenna_Err_St 1;
BA_ "U_U55X_MY2022_Rx" SG_ 761 SDARS_Antenna_Err_St 1;
BA_ "U_CD542_MY2021_Rx" SG_ 761 SDARS_Antenna_Err_St 1;
BA_ "U_T6_MCA_MY2020_Rx" SG_ 761 SDARS_Antenna_Err_St 1;
BA_ "GenSigSendType" SG_ 761 SDARS_Antenna_Err_St 3;
BA_ "U_CD542_MY2021_Tx" SG_ 761 SDARS_Receive_Err_St 1;
BA_ "U_T6_MCA_MY2020_Tx" SG_ 761 SDARS_Receive_Err_St 1;
BA_ "U_P702_MY2021_Tx" SG_ 761 SDARS_Receive_Err_St 1;
BA_ "U_U55X_MY2022_Rx" SG_ 761 SDARS_Receive_Err_St 1;
BA_ "U_CD542_MY2021_Rx" SG_ 761 SDARS_Receive_Err_St 1;
BA_ "U_T6_MCA_MY2020_Rx" SG_ 761 SDARS_Receive_Err_St 1;
BA_ "GenSigSendType" SG_ 761 SDARS_Receive_Err_St 3;
BA_ "U_CD542_MY2021_Tx" SG_ 761 SDARS_Error_Conf_St 1;
BA_ "U_T6_MCA_MY2020_Tx" SG_ 761 SDARS_Error_Conf_St 1;
BA_ "U_P702_MY2021_Tx" SG_ 761 SDARS_Error_Conf_St 1;
BA_ "U_U55X_MY2022_Rx" SG_ 761 SDARS_Error_Conf_St 1;
BA_ "U_CD542_MY2021_Rx" SG_ 761 SDARS_Error_Conf_St 1;
BA_ "U_T6_MCA_MY2020_Rx" SG_ 761 SDARS_Error_Conf_St 1;
BA_ "GenSigSendType" SG_ 761 SDARS_Error_Conf_St 3;
BA_ "U_U55X_MY2022_Tx" SG_ 694 PHONE_MC_WORD_Tx 1;
BA_ "U_CD542_MY2021_Tx" SG_ 694 PHONE_MC_WORD_Tx 1;
BA_ "U_T6_MCA_MY2020_Tx" SG_ 694 PHONE_MC_WORD_Tx 1;
BA_ "U_U55X_MY2022_Rx" SG_ 694 PHONE_MC_WORD_Tx 1;
BA_ "U_CD542_MY2021_Rx" SG_ 694 PHONE_MC_WORD_Tx 1;
BA_ "U_T6_MCA_MY2020_Rx" SG_ 694 PHONE_MC_WORD_Tx 1;
BA_ "U_U55X_MY2022_Tx" SG_ 750 LoclFuelEffUnit_D_Stat 1;
BA_ "U_CD542_MY2021_Tx" SG_ 750 LoclFuelEffUnit_D_Stat 1;
BA_ "U_T6_MCA_MY2020_Tx" SG_ 750 LoclFuelEffUnit_D_Stat 1;
BA_ "U_P702_MY2021_Tx" SG_ 750 LoclFuelEffUnit_D_Stat 1;
BA_ "U_U55X_MY2022_Rx" SG_ 750 LoclFuelEffUnit_D_Stat 1;
BA_ "U_CD542_MY2021_Rx" SG_ 750 LoclFuelEffUnit_D_Stat 1;
BA_ "U_T6_MCA_MY2020_Rx" SG_ 750 LoclFuelEffUnit_D_Stat 1;
BA_ "GenSigSendType" SG_ 750 LoclFuelEffUnit_D_Stat 3;
BA_ "U_U55X_MY2022_Tx" SG_ 750 RoadsideAsstAvail_D_St 1;
BA_ "U_CD542_MY2021_Tx" SG_ 750 RoadsideAsstAvail_D_St 1;
BA_ "U_T6_MCA_MY2020_Tx" SG_ 750 RoadsideAsstAvail_D_St 1;
BA_ "U_P702_MY2021_Tx" SG_ 750 RoadsideAsstAvail_D_St 1;
BA_ "U_U55X_MY2022_Rx" SG_ 750 RoadsideAsstAvail_D_St 1;
BA_ "U_CD542_MY2021_Rx" SG_ 750 RoadsideAsstAvail_D_St 1;
BA_ "U_T6_MCA_MY2020_Rx" SG_ 750 RoadsideAsstAvail_D_St 1;
BA_ "GenSigSendType" SG_ 750 RoadsideAsstAvail_D_St 3;
BA_ "U_U55X_MY2022_Tx" SG_ 750 EmbedNavActive_D_Stat 1;
BA_ "U_CD542_MY2021_Tx" SG_ 750 EmbedNavActive_D_Stat 1;
BA_ "U_T6_MCA_MY2020_Tx" SG_ 750 EmbedNavActive_D_Stat 1;
BA_ "U_P702_MY2021_Tx" SG_ 750 EmbedNavActive_D_Stat 1;
BA_ "U_U55X_MY2022_Rx" SG_ 750 EmbedNavActive_D_Stat 1;
BA_ "U_CD542_MY2021_Rx" SG_ 750 EmbedNavActive_D_Stat 1;
BA_ "U_T6_MCA_MY2020_Rx" SG_ 750 EmbedNavActive_D_Stat 1;
BA_ "GenSigSendType" SG_ 750 EmbedNavActive_D_Stat 3;
BA_ "U_U55X_MY2022_Tx" SG_ 750 UnitOfLength_St 1;
BA_ "U_CD542_MY2021_Tx" SG_ 750 UnitOfLength_St 1;
BA_ "U_T6_MCA_MY2020_Tx" SG_ 750 UnitOfLength_St 1;
BA_ "U_P702_MY2021_Tx" SG_ 750 UnitOfLength_St 1;
BA_ "U_CD542_MY2021_Rx" SG_ 750 UnitOfLength_St 1;
BA_ "U_T6_MCA_MY2020_Rx" SG_ 750 UnitOfLength_St 1;
BA_ "GenSigSendType" SG_ 750 UnitOfLength_St 3;
BA_ "U_U55X_MY2022_Tx" SG_ 750 RouteActive_St 1;
BA_ "U_CD542_MY2021_Tx" SG_ 750 RouteActive_St 1;
BA_ "U_T6_MCA_MY2020_Tx" SG_ 750 RouteActive_St 1;
BA_ "U_P702_MY2021_Tx" SG_ 750 RouteActive_St 1;
BA_ "U_U55X_MY2022_Rx" SG_ 750 RouteActive_St 1;
BA_ "U_CD542_MY2021_Rx" SG_ 750 RouteActive_St 1;
BA_ "U_T6_MCA_MY2020_Rx" SG_ 750 RouteActive_St 1;
BA_ "GenSigSendType" SG_ 750 RouteActive_St 3;
BA_ "U_U55X_MY2022_Tx" SG_ 750 CancelCurrWaypt_St 1;
BA_ "U_CD542_MY2021_Tx" SG_ 750 CancelCurrWaypt_St 1;
BA_ "U_T6_MCA_MY2020_Tx" SG_ 750 CancelCurrWaypt_St 1;
BA_ "U_P702_MY2021_Tx" SG_ 750 CancelCurrWaypt_St 1;
BA_ "U_CD542_MY2021_Rx" SG_ 750 CancelCurrWaypt_St 1;
BA_ "U_T6_MCA_MY2020_Rx" SG_ 750 CancelCurrWaypt_St 1;
BA_ "GenSigSendType" SG_ 750 CancelCurrWaypt_St 3;
BA_ "U_U55X_MY2022_Tx" SG_ 750 Nav_RemainTTDestDays_St 1;
BA_ "U_CD542_MY2021_Tx" SG_ 750 Nav_RemainTTDestDays_St 1;
BA_ "U_T6_MCA_MY2020_Tx" SG_ 750 Nav_RemainTTDestDays_St 1;
BA_ "U_P702_MY2021_Tx" SG_ 750 Nav_RemainTTDestDays_St 1;
BA_ "U_U55X_MY2022_Rx" SG_ 750 Nav_RemainTTDestDays_St 1;
BA_ "U_CD542_MY2021_Rx" SG_ 750 Nav_RemainTTDestDays_St 1;
BA_ "U_T6_MCA_MY2020_Rx" SG_ 750 Nav_RemainTTDestDays_St 1;
BA_ "GenSigSendType" SG_ 750 Nav_RemainTTDestDays_St 3;
BA_ "U_U55X_MY2022_Tx" SG_ 750 WaypointsActive_St 1;
BA_ "U_CD542_MY2021_Tx" SG_ 750 WaypointsActive_St 1;
BA_ "U_T6_MCA_MY2020_Tx" SG_ 750 WaypointsActive_St 1;
BA_ "U_P702_MY2021_Tx" SG_ 750 WaypointsActive_St 1;
BA_ "U_U55X_MY2022_Rx" SG_ 750 WaypointsActive_St 1;
BA_ "U_CD542_MY2021_Rx" SG_ 750 WaypointsActive_St 1;
BA_ "U_T6_MCA_MY2020_Rx" SG_ 750 WaypointsActive_St 1;
BA_ "GenSigSendType" SG_ 750 WaypointsActive_St 3;
BA_ "U_U55X_MY2022_Tx" SG_ 750 Nav_RemainTTDestHour_St 1;
BA_ "U_CD542_MY2021_Tx" SG_ 750 Nav_RemainTTDestHour_St 1;
BA_ "U_T6_MCA_MY2020_Tx" SG_ 750 Nav_RemainTTDestHour_St 1;
BA_ "U_P702_MY2021_Tx" SG_ 750 Nav_RemainTTDestHour_St 1;
BA_ "U_U55X_MY2022_Rx" SG_ 750 Nav_RemainTTDestHour_St 1;
BA_ "U_CD542_MY2021_Rx" SG_ 750 Nav_RemainTTDestHour_St 1;
BA_ "U_T6_MCA_MY2020_Rx" SG_ 750 Nav_RemainTTDestHour_St 1;
BA_ "GenSigSendType" SG_ 750 Nav_RemainTTDestHour_St 3;
BA_ "U_U55X_MY2022_Tx" SG_ 750 Nav_RemainTTDestMin_St 1;
BA_ "U_CD542_MY2021_Tx" SG_ 750 Nav_RemainTTDestMin_St 1;
BA_ "U_T6_MCA_MY2020_Tx" SG_ 750 Nav_RemainTTDestMin_St 1;
BA_ "U_P702_MY2021_Tx" SG_ 750 Nav_RemainTTDestMin_St 1;
BA_ "U_U55X_MY2022_Rx" SG_ 750 Nav_RemainTTDestMin_St 1;
BA_ "U_CD542_MY2021_Rx" SG_ 750 Nav_RemainTTDestMin_St 1;
BA_ "U_T6_MCA_MY2020_Rx" SG_ 750 Nav_RemainTTDestMin_St 1;
BA_ "GenSigSendType" SG_ 750 Nav_RemainTTDestMin_St 3;
BA_ "U_U55X_MY2022_Tx" SG_ 750 Nav_DistanToDestUnit_St 1;
BA_ "U_CD542_MY2021_Tx" SG_ 750 Nav_DistanToDestUnit_St 1;
BA_ "U_T6_MCA_MY2020_Tx" SG_ 750 Nav_DistanToDestUnit_St 1;
BA_ "U_P702_MY2021_Tx" SG_ 750 Nav_DistanToDestUnit_St 1;
BA_ "U_U55X_MY2022_Rx" SG_ 750 Nav_DistanToDestUnit_St 1;
BA_ "U_CD542_MY2021_Rx" SG_ 750 Nav_DistanToDestUnit_St 1;
BA_ "U_T6_MCA_MY2020_Rx" SG_ 750 Nav_DistanToDestUnit_St 1;
BA_ "U_U55X_MY2022_Tx" SG_ 750 Nav_DistancToDestVal_St 1;
BA_ "U_CD542_MY2021_Tx" SG_ 750 Nav_DistancToDestVal_St 1;
BA_ "U_T6_MCA_MY2020_Tx" SG_ 750 Nav_DistancToDestVal_St 1;
BA_ "U_P702_MY2021_Tx" SG_ 750 Nav_DistancToDestVal_St 1;
BA_ "U_U55X_MY2022_Rx" SG_ 750 Nav_DistancToDestVal_St 1;
BA_ "U_CD542_MY2021_Rx" SG_ 750 Nav_DistancToDestVal_St 1;
BA_ "U_T6_MCA_MY2020_Rx" SG_ 750 Nav_DistancToDestVal_St 1;
BA_ "GenSigSendType" SG_ 750 Nav_DistancToDestVal_St 3;
BA_ "U_U55X_MY2022_Tx" SG_ 750 NavError_Waypoint_St 1;
BA_ "U_CD542_MY2021_Tx" SG_ 750 NavError_Waypoint_St 1;
BA_ "U_T6_MCA_MY2020_Tx" SG_ 750 NavError_Waypoint_St 1;
BA_ "U_P702_MY2021_Tx" SG_ 750 NavError_Waypoint_St 1;
BA_ "U_U55X_MY2022_Rx" SG_ 750 NavError_Waypoint_St 1;
BA_ "U_CD542_MY2021_Rx" SG_ 750 NavError_Waypoint_St 1;
BA_ "U_T6_MCA_MY2020_Rx" SG_ 750 NavError_Waypoint_St 1;
BA_ "U_U55X_MY2022_Tx" SG_ 704 NAV_MC_WORD_Tx 1;
BA_ "U_CD542_MY2021_Tx" SG_ 704 NAV_MC_WORD_Tx 1;
BA_ "U_T6_MCA_MY2020_Tx" SG_ 704 NAV_MC_WORD_Tx 1;
BA_ "U_CD542_MY2021_Rx" SG_ 704 NAV_MC_WORD_Tx 1;
BA_ "U_T6_MCA_MY2020_Rx" SG_ 704 NAV_MC_WORD_Tx 1;
BA_ "U_U55X_MY2022_Tx" SG_ 725 InfotainmentAudio_St 1;
BA_ "U_CD542_MY2021_Tx" SG_ 725 InfotainmentAudio_St 1;
BA_ "U_T6_MCA_MY2020_Tx" SG_ 725 InfotainmentAudio_St 1;
BA_ "U_P702_MY2021_Tx" SG_ 725 InfotainmentAudio_St 1;
BA_ "U_P702_MY2021_Rx" SG_ 725 InfotainmentAudio_St 1;
BA_ "U_U55X_MY2022_Rx" SG_ 725 InfotainmentAudio_St 1;
BA_ "U_CD542_MY2021_Rx" SG_ 725 InfotainmentAudio_St 1;
BA_ "U_T6_MCA_MY2020_Rx" SG_ 725 InfotainmentAudio_St 1;
BA_ "GenSigSendType" SG_ 725 InfotainmentAudio_St 3;
BA_ "U_U55X_MY2022_Tx" SG_ 725 ACU_CompLogic_St 1;
BA_ "U_T6_MCA_MY2020_Tx" SG_ 725 ACU_CompLogic_St 1;
BA_ "U_P702_MY2021_Tx" SG_ 725 ACU_CompLogic_St 1;
BA_ "GenSigSendType" SG_ 725 ACU_CompLogic_St 3;
BA_ "U_U55X_MY2022_Tx" SG_ 725 ACU_RadioError_St 1;
BA_ "U_CD542_MY2021_Tx" SG_ 725 ACU_RadioError_St 1;
BA_ "U_T6_MCA_MY2020_Tx" SG_ 725 ACU_RadioError_St 1;
BA_ "U_P702_MY2021_Tx" SG_ 725 ACU_RadioError_St 1;
BA_ "U_U55X_MY2022_Rx" SG_ 725 ACU_RadioError_St 1;
BA_ "U_P702_MY2021_Rx" SG_ 725 ACU_RadioError_St 1;
BA_ "U_CD542_MY2021_Rx" SG_ 725 ACU_RadioError_St 1;
BA_ "U_T6_MCA_MY2020_Rx" SG_ 725 ACU_RadioError_St 1;
BA_ "GenSigSendType" SG_ 725 ACU_RadioError_St 3;
BA_ "U_U55X_MY2022_Tx" SG_ 725 ACU_HardwareError_St 1;
BA_ "U_CD542_MY2021_Tx" SG_ 725 ACU_HardwareError_St 1;
BA_ "U_T6_MCA_MY2020_Tx" SG_ 725 ACU_HardwareError_St 1;
BA_ "U_P702_MY2021_Tx" SG_ 725 ACU_HardwareError_St 1;
BA_ "U_U55X_MY2022_Rx" SG_ 725 ACU_HardwareError_St 1;
BA_ "U_P702_MY2021_Rx" SG_ 725 ACU_HardwareError_St 1;
BA_ "U_CD542_MY2021_Rx" SG_ 725 ACU_HardwareError_St 1;
BA_ "U_T6_MCA_MY2020_Rx" SG_ 725 ACU_HardwareError_St 1;
BA_ "GenSigSendType" SG_ 725 ACU_HardwareError_St 3;
BA_ "U_U55X_MY2022_Tx" SG_ 725 ACU_CurrentRadioBand_St 1;
BA_ "U_CD542_MY2021_Tx" SG_ 725 ACU_CurrentRadioBand_St 1;
BA_ "U_T6_MCA_MY2020_Tx" SG_ 725 ACU_CurrentRadioBand_St 1;
BA_ "U_P702_MY2021_Tx" SG_ 725 ACU_CurrentRadioBand_St 1;
BA_ "U_U55X_MY2022_Rx" SG_ 725 ACU_CurrentRadioBand_St 1;
BA_ "U_CD542_MY2021_Rx" SG_ 725 ACU_CurrentRadioBand_St 1;
BA_ "U_T6_MCA_MY2020_Rx" SG_ 725 ACU_CurrentRadioBand_St 1;
BA_ "GenSigSendType" SG_ 725 ACU_CurrentRadioBand_St 3;
BA_ "U_U55X_MY2022_Tx" SG_ 725 ACU_CurrentPTYCode_St 1;
BA_ "U_CD542_MY2021_Tx" SG_ 725 ACU_CurrentPTYCode_St 1;
BA_ "U_T6_MCA_MY2020_Tx" SG_ 725 ACU_CurrentPTYCode_St 1;
BA_ "U_P702_MY2021_Tx" SG_ 725 ACU_CurrentPTYCode_St 1;
BA_ "U_P702_MY2021_Rx" SG_ 725 ACU_CurrentPTYCode_St 1;
BA_ "U_U55X_MY2022_Rx" SG_ 725 ACU_CurrentPTYCode_St 1;
BA_ "U_CD542_MY2021_Rx" SG_ 725 ACU_CurrentPTYCode_St 1;
BA_ "U_T6_MCA_MY2020_Rx" SG_ 725 ACU_CurrentPTYCode_St 1;
BA_ "GenSigSendType" SG_ 725 ACU_CurrentPTYCode_St 3;
BA_ "U_U55X_MY2022_Tx" SG_ 725 ACU_CurrentPICode_St 1;
BA_ "U_CD542_MY2021_Tx" SG_ 725 ACU_CurrentPICode_St 1;
BA_ "U_T6_MCA_MY2020_Tx" SG_ 725 ACU_CurrentPICode_St 1;
BA_ "U_P702_MY2021_Tx" SG_ 725 ACU_CurrentPICode_St 1;
BA_ "U_U55X_MY2022_Rx" SG_ 725 ACU_CurrentPICode_St 1;
BA_ "U_CD542_MY2021_Rx" SG_ 725 ACU_CurrentPICode_St 1;
BA_ "U_T6_MCA_MY2020_Rx" SG_ 725 ACU_CurrentPICode_St 1;
BA_ "U_P702_MY2021_Rx" SG_ 725 ACU_CurrentPICode_St 1;
BA_ "GenSigSendType" SG_ 725 ACU_CurrentPICode_St 3;
BA_ "U_U55X_MY2022_Tx" SG_ 725 ACU_CurrentFreq_St 1;
BA_ "U_CD542_MY2021_Tx" SG_ 725 ACU_CurrentFreq_St 1;
BA_ "U_T6_MCA_MY2020_Tx" SG_ 725 ACU_CurrentFreq_St 1;
BA_ "U_P702_MY2021_Tx" SG_ 725 ACU_CurrentFreq_St 1;
BA_ "U_CX727_MY2021_Rx" SG_ 725 ACU_CurrentFreq_St 1;
BA_ "U_P702_MY2021_Rx" SG_ 725 ACU_CurrentFreq_St 1;
BA_ "U_U55X_MY2022_Rx" SG_ 725 ACU_CurrentFreq_St 1;
BA_ "U_CD542_MY2021_Rx" SG_ 725 ACU_CurrentFreq_St 1;
BA_ "U_T6_MCA_MY2020_Rx" SG_ 725 ACU_CurrentFreq_St 1;
BA_ "GenSigSendType" SG_ 725 ACU_CurrentFreq_St 3;
BA_ "U_U55X_MY2022_Tx" SG_ 725 ACU_AFMode_St 1;
BA_ "U_CD542_MY2021_Tx" SG_ 725 ACU_AFMode_St 1;
BA_ "U_T6_MCA_MY2020_Tx" SG_ 725 ACU_AFMode_St 1;
BA_ "U_P702_MY2021_Tx" SG_ 725 ACU_AFMode_St 1;
BA_ "U_U55X_MY2022_Rx" SG_ 725 ACU_AFMode_St 1;
BA_ "U_CD542_MY2021_Rx" SG_ 725 ACU_AFMode_St 1;
BA_ "U_T6_MCA_MY2020_Rx" SG_ 725 ACU_AFMode_St 1;
BA_ "U_P702_MY2021_Rx" SG_ 725 ACU_AFMode_St 1;
BA_ "GenSigSendType" SG_ 725 ACU_AFMode_St 3;
BA_ "GenSigSendType" SG_ 1074 TrlrTireDual_D_Stat 3;
BA_ "U_U55X_MY2022_Rx" SG_ 1074 PwLftgtIntSw_B_Stat_UB 1;
BA_ "U_CD542_MY2021_Rx" SG_ 1074 PwLftgtIntSw_B_Stat_UB 1;
BA_ "U_T6_MCA_MY2020_Rx" SG_ 1074 PwLftgtIntSw_B_Stat_UB 1;
BA_ "U_U55X_MY2022_Rx" SG_ 1074 PwLftgtIntSw_B_Stat 1;
BA_ "U_CD542_MY2021_Rx" SG_ 1074 PwLftgtIntSw_B_Stat 1;
BA_ "U_T6_MCA_MY2020_Rx" SG_ 1074 PwLftgtIntSw_B_Stat 1;
BA_ "GenSigSendType" SG_ 1074 PwLftgtIntSw_B_Stat 3;
BA_ "WakeupSignal" SG_ 1074 PwLftgtIntSw_B_Stat 1;
BA_ "U_U55X_MY2022_Rx" SG_ 1074 E_Frt_Btn_Status_1st_UB 1;
BA_ "U_CD542_MY2021_Rx" SG_ 1074 E_Frt_Btn_Status_1st_UB 1;
BA_ "U_T6_MCA_MY2020_Rx" SG_ 1074 E_Frt_Btn_Status_1st_UB 1;
BA_ "U_U55X_MY2022_Rx" SG_ 1074 E_Frt_Btn_Status_2nd_UB 1;
BA_ "U_CD542_MY2021_Rx" SG_ 1074 E_Frt_Btn_Status_2nd_UB 1;
BA_ "U_T6_MCA_MY2020_Rx" SG_ 1074 E_Frt_Btn_Status_2nd_UB 1;
BA_ "U_U55X_MY2022_Rx" SG_ 1074 E_Frt_Btn_Status_2nd 1;
BA_ "U_CD542_MY2021_Rx" SG_ 1074 E_Frt_Btn_Status_2nd 1;
BA_ "U_T6_MCA_MY2020_Rx" SG_ 1074 E_Frt_Btn_Status_2nd 1;
BA_ "GenSigSendType" SG_ 1074 E_Frt_Btn_Status_2nd 3;
BA_ "U_U55X_MY2022_Rx" SG_ 1074 E_Frt_Btn_Status_1st 1;
BA_ "U_CD542_MY2021_Rx" SG_ 1074 E_Frt_Btn_Status_1st 1;
BA_ "U_T6_MCA_MY2020_Rx" SG_ 1074 E_Frt_Btn_Status_1st 1;
BA_ "GenSigSendType" SG_ 1074 E_Frt_Btn_Status_1st 3;
BA_ "U_CD542_MY2021_Rx" SG_ 1074 DrLatchRrMsgTxt_D_Rq_UB 1;
BA_ "U_T6_MCA_MY2020_Rx" SG_ 1074 DrLatchRrMsgTxt_D_Rq_UB 1;
BA_ "U_CD542_MY2021_Rx" SG_ 1074 DrLatchRrMsgTxt_D_Rq 1;
BA_ "U_T6_MCA_MY2020_Rx" SG_ 1074 DrLatchRrMsgTxt_D_Rq 1;
BA_ "GenSigSendType" SG_ 1074 DrLatchRrMsgTxt_D_Rq 3;
BA_ "U_CD542_MY2021_Rx" SG_ 1074 DrLatchRlMsgTxt_D_Rq_UB 1;
BA_ "U_T6_MCA_MY2020_Rx" SG_ 1074 DrLatchRlMsgTxt_D_Rq_UB 1;
BA_ "U_CD542_MY2021_Rx" SG_ 1074 DrLatchRlMsgTxt_D_Rq 1;
BA_ "U_T6_MCA_MY2020_Rx" SG_ 1074 DrLatchRlMsgTxt_D_Rq 1;
BA_ "GenSigSendType" SG_ 1074 DrLatchRlMsgTxt_D_Rq 3;
BA_ "U_CD542_MY2021_Rx" SG_ 1074 DrLatchFrMsgTxt_D_Rq_UB 1;
BA_ "U_T6_MCA_MY2020_Rx" SG_ 1074 DrLatchFrMsgTxt_D_Rq_UB 1;
BA_ "U_CD542_MY2021_Rx" SG_ 1074 DrLatchFrMsgTxt_D_Rq 1;
BA_ "U_T6_MCA_MY2020_Rx" SG_ 1074 DrLatchFrMsgTxt_D_Rq 1;
BA_ "GenSigSendType" SG_ 1074 DrLatchFrMsgTxt_D_Rq 3;
BA_ "U_CD542_MY2021_Rx" SG_ 1074 DrLatchFlMsgTxt_D_Rq_UB 1;
BA_ "U_T6_MCA_MY2020_Rx" SG_ 1074 DrLatchFlMsgTxt_D_Rq_UB 1;
BA_ "U_CD542_MY2021_Rx" SG_ 1074 DrLatchFlMsgTxt_D_Rq 1;
BA_ "U_T6_MCA_MY2020_Rx" SG_ 1074 DrLatchFlMsgTxt_D_Rq 1;
BA_ "GenSigSendType" SG_ 1074 DrLatchFlMsgTxt_D_Rq 3;
BA_ "U_U55X_MY2022_Rx" SG_ 1074 TrlrTireThresh_D_Stat_UB 1;
BA_ "U_CD542_MY2021_Rx" SG_ 1074 TrlrTireThresh_D_Stat_UB 1;
BA_ "U_T6_MCA_MY2020_Rx" SG_ 1074 TrlrTireThresh_D_Stat_UB 1;
BA_ "U_P702_MY2021_Rx" SG_ 1074 TrlrTireThresh_D_Stat_UB 1;
BA_ "U_U55X_MY2022_Rx" SG_ 1074 TrlrTireThresh_D_Stat 1;
BA_ "U_CD542_MY2021_Rx" SG_ 1074 TrlrTireThresh_D_Stat 1;
BA_ "U_T6_MCA_MY2020_Rx" SG_ 1074 TrlrTireThresh_D_Stat 1;
BA_ "U_P702_MY2021_Rx" SG_ 1074 TrlrTireThresh_D_Stat 1;
BA_ "U_U55X_MY2022_Rx" SG_ 1074 TrlrTireSys_D_Stat_UB 1;
BA_ "U_CD542_MY2021_Rx" SG_ 1074 TrlrTireSys_D_Stat_UB 1;
BA_ "U_T6_MCA_MY2020_Rx" SG_ 1074 TrlrTireSys_D_Stat_UB 1;
BA_ "U_P702_MY2021_Rx" SG_ 1074 TrlrTireSys_D_Stat_UB 1;
BA_ "U_U55X_MY2022_Rx" SG_ 1074 TrlrTireSys_D_Stat 1;
BA_ "U_CD542_MY2021_Rx" SG_ 1074 TrlrTireSys_D_Stat 1;
BA_ "U_T6_MCA_MY2020_Rx" SG_ 1074 TrlrTireSys_D_Stat 1;
BA_ "U_P702_MY2021_Rx" SG_ 1074 TrlrTireSys_D_Stat 1;
BA_ "GenSigSendType" SG_ 1074 TrlrTireSys_D_Stat 3;
BA_ "U_U55X_MY2022_Rx" SG_ 1074 TrlrTireCnt_D_Stat_UB 1;
BA_ "U_CD542_MY2021_Rx" SG_ 1074 TrlrTireCnt_D_Stat_UB 1;
BA_ "U_T6_MCA_MY2020_Rx" SG_ 1074 TrlrTireCnt_D_Stat_UB 1;
BA_ "U_P702_MY2021_Rx" SG_ 1074 TrlrTireCnt_D_Stat_UB 1;
BA_ "U_U55X_MY2022_Rx" SG_ 1074 TrlrTireCnt_D_Stat 1;
BA_ "U_CD542_MY2021_Rx" SG_ 1074 TrlrTireCnt_D_Stat 1;
BA_ "U_T6_MCA_MY2020_Rx" SG_ 1074 TrlrTireCnt_D_Stat 1;
BA_ "U_P702_MY2021_Rx" SG_ 1074 TrlrTireCnt_D_Stat 1;
BA_ "GenSigSendType" SG_ 1074 TrlrTireCnt_D_Stat 3;
BA_ "U_U55X_MY2022_Rx" SG_ 1074 BrkMdeInhbt_B_RqDsply_UB 1;
BA_ "U_CD542_MY2021_Rx" SG_ 1074 BrkMdeInhbt_B_RqDsply_UB 1;
BA_ "U_T6_MCA_MY2020_Rx" SG_ 1074 BrkMdeInhbt_B_RqDsply_UB 1;
BA_ "U_P702_MY2021_Rx" SG_ 1074 BrkMdeInhbt_B_RqDsply_UB 1;
BA_ "U_U55X_MY2022_Rx" SG_ 1074 BrkMdeInhbt_B_RqDsply 1;
BA_ "U_CD542_MY2021_Rx" SG_ 1074 BrkMdeInhbt_B_RqDsply 1;
BA_ "U_T6_MCA_MY2020_Rx" SG_ 1074 BrkMdeInhbt_B_RqDsply 1;
BA_ "U_P702_MY2021_Rx" SG_ 1074 BrkMdeInhbt_B_RqDsply 1;
BA_ "GenSigSendType" SG_ 1074 BrkMdeInhbt_B_RqDsply 3;
BA_ "WakeupSignal" SG_ 1074 BrkMdeInhbt_B_RqDsply 1;
BA_ "U_CD542_MY2021_Tx" SG_ 1014 WrlssAcsyChrg_Pc_Actl 1;
BA_ "U_U55X_MY2022_Rx" SG_ 1014 WrlssAcsyChrg_Pc_Actl 1;
BA_ "GenSigStartValue" SG_ 1014 WrlssAcsyChrg_Pc_Actl 126;
BA_ "U_U55X_MY2022_Tx" SG_ 1014 WrlssAcsyChrgr_D_Stat 1;
BA_ "U_CD542_MY2021_Tx" SG_ 1014 WrlssAcsyChrgr_D_Stat 1;
BA_ "U_T6_MCA_MY2020_Tx" SG_ 1014 WrlssAcsyChrgr_D_Stat 1;
BA_ "U_P702_MY2021_Tx" SG_ 1014 WrlssAcsyChrgr_D_Stat 1;
BA_ "U_CX727_MY2021_Tx" SG_ 1014 WrlssAcsyChrgr_D_Stat 1;
BA_ "U_U55X_MY2022_Rx" SG_ 1014 WrlssAcsyChrgr_D_Stat 1;
BA_ "U_CD542_MY2021_Rx" SG_ 1014 WrlssAcsyChrgr_D_Stat 1;
BA_ "U_T6_MCA_MY2020_Rx" SG_ 1014 WrlssAcsyChrgr_D_Stat 1;
BA_ "U_P702_MY2021_Rx" SG_ 1014 WrlssAcsyChrgr_D_Stat 1;
BA_ "GenSigSendType" SG_ 1014 WrlssAcsyChrgr_D_Stat 3;
BA_ "GenSigStartValue" SG_ 1014 WrlssAcsyChrgr_D_Stat 1;
BA_ "GenSigStartValueInteger" SG_ 1014 WrlssAcsyChrgr_D_Stat 1;
BA_ "U_U55X_MY2022_Tx" SG_ 548 DSP_AHU_ChmTstTone_Rq 1;
BA_ "U_CD542_MY2021_Tx" SG_ 548 DSP_AHU_ChmTstTone_Rq 1;
BA_ "U_T6_MCA_MY2020_Tx" SG_ 548 DSP_AHU_ChmTstTone_Rq 1;
BA_ "U_P702_MY2021_Tx" SG_ 548 DSP_AHU_ChmTstTone_Rq 1;
BA_ "U_U55X_MY2022_Rx" SG_ 548 DSP_AHU_ChmTstTone_Rq 1;
BA_ "U_CD542_MY2021_Rx" SG_ 548 DSP_AHU_ChmTstTone_Rq 1;
BA_ "U_T6_MCA_MY2020_Rx" SG_ 548 DSP_AHU_ChmTstTone_Rq 1;
BA_ "U_P702_MY2021_Rx" SG_ 548 DSP_AHU_ChmTstTone_Rq 1;
BA_ "GenSigSendType" SG_ 548 DSP_AHU_ChmTstTone_Rq 3;
BA_ "U_U55X_MY2022_Tx" SG_ 548 DSP_ChimeChanState_St 1;
BA_ "U_CD542_MY2021_Tx" SG_ 548 DSP_ChimeChanState_St 1;
BA_ "U_T6_MCA_MY2020_Tx" SG_ 548 DSP_ChimeChanState_St 1;
BA_ "U_P702_MY2021_Tx" SG_ 548 DSP_ChimeChanState_St 1;
BA_ "U_U55X_MY2022_Rx" SG_ 548 DSP_ChimeChanState_St 1;
BA_ "U_CD542_MY2021_Rx" SG_ 548 DSP_ChimeChanState_St 1;
BA_ "U_T6_MCA_MY2020_Rx" SG_ 548 DSP_ChimeChanState_St 1;
BA_ "U_P702_MY2021_Rx" SG_ 548 DSP_ChimeChanState_St 1;
BA_ "GenSigSendType" SG_ 548 DSP_ChimeChanState_St 3;
BA_ "U_U55X_MY2022_Tx" SG_ 548 DSP_Chime2_Not_Recgnizd 1;
BA_ "U_CD542_MY2021_Tx" SG_ 548 DSP_Chime2_Not_Recgnizd 1;
BA_ "U_T6_MCA_MY2020_Tx" SG_ 548 DSP_Chime2_Not_Recgnizd 1;
BA_ "U_P702_MY2021_Tx" SG_ 548 DSP_Chime2_Not_Recgnizd 1;
BA_ "U_U55X_MY2022_Rx" SG_ 548 DSP_Chime2_Not_Recgnizd 1;
BA_ "U_CD542_MY2021_Rx" SG_ 548 DSP_Chime2_Not_Recgnizd 1;
BA_ "U_T6_MCA_MY2020_Rx" SG_ 548 DSP_Chime2_Not_Recgnizd 1;
BA_ "GenSigSendType" SG_ 548 DSP_Chime2_Not_Recgnizd 3;
BA_ "U_U55X_MY2022_Tx" SG_ 548 DSP_Chime_Not_Recgnizd 1;
BA_ "U_CD542_MY2021_Tx" SG_ 548 DSP_Chime_Not_Recgnizd 1;
BA_ "U_T6_MCA_MY2020_Tx" SG_ 548 DSP_Chime_Not_Recgnizd 1;
BA_ "U_P702_MY2021_Tx" SG_ 548 DSP_Chime_Not_Recgnizd 1;
BA_ "U_U55X_MY2022_Rx" SG_ 548 DSP_Chime_Not_Recgnizd 1;
BA_ "U_CD542_MY2021_Rx" SG_ 548 DSP_Chime_Not_Recgnizd 1;
BA_ "U_T6_MCA_MY2020_Rx" SG_ 548 DSP_Chime_Not_Recgnizd 1;
BA_ "GenSigSendType" SG_ 548 DSP_Chime_Not_Recgnizd 3;
BA_ "U_U55X_MY2022_Tx" SG_ 548 DSP_Alert_Channel3 1;
BA_ "U_CD542_MY2021_Tx" SG_ 548 DSP_Alert_Channel3 1;
BA_ "U_T6_MCA_MY2020_Tx" SG_ 548 DSP_Alert_Channel3 1;
BA_ "U_P702_MY2021_Tx" SG_ 548 DSP_Alert_Channel3 1;
BA_ "U_U55X_MY2022_Rx" SG_ 548 DSP_Alert_Channel3 1;
BA_ "U_CD542_MY2021_Rx" SG_ 548 DSP_Alert_Channel3 1;
BA_ "U_T6_MCA_MY2020_Rx" SG_ 548 DSP_Alert_Channel3 1;
BA_ "GenSigSendType" SG_ 548 DSP_Alert_Channel3 3;
BA_ "U_U55X_MY2022_Tx" SG_ 548 DSP_Alert_Channel2 1;
BA_ "U_CD542_MY2021_Tx" SG_ 548 DSP_Alert_Channel2 1;
BA_ "U_T6_MCA_MY2020_Tx" SG_ 548 DSP_Alert_Channel2 1;
BA_ "U_P702_MY2021_Tx" SG_ 548 DSP_Alert_Channel2 1;
BA_ "U_P702_MY2021_Rx" SG_ 548 DSP_Alert_Channel2 1;
BA_ "U_U55X_MY2022_Rx" SG_ 548 DSP_Alert_Channel2 1;
BA_ "U_CD542_MY2021_Rx" SG_ 548 DSP_Alert_Channel2 1;
BA_ "U_T6_MCA_MY2020_Rx" SG_ 548 DSP_Alert_Channel2 1;
BA_ "GenSigSendType" SG_ 548 DSP_Alert_Channel2 3;
BA_ "U_U55X_MY2022_Tx" SG_ 548 DSP_Alert_Channel1 1;
BA_ "U_CD542_MY2021_Tx" SG_ 548 DSP_Alert_Channel1 1;
BA_ "U_T6_MCA_MY2020_Tx" SG_ 548 DSP_Alert_Channel1 1;
BA_ "U_P702_MY2021_Tx" SG_ 548 DSP_Alert_Channel1 1;
BA_ "U_U55X_MY2022_Rx" SG_ 548 DSP_Alert_Channel1 1;
BA_ "U_CD542_MY2021_Rx" SG_ 548 DSP_Alert_Channel1 1;
BA_ "U_T6_MCA_MY2020_Rx" SG_ 548 DSP_Alert_Channel1 1;
BA_ "U_P702_MY2021_Rx" SG_ 548 DSP_Alert_Channel1 1;
BA_ "GenSigSendType" SG_ 548 DSP_Alert_Channel1 3;
BA_ "U_U55X_MY2022_Tx" SG_ 548 DSP_Chimes_Supported 1;
BA_ "U_T6_MCA_MY2020_Tx" SG_ 548 DSP_Chimes_Supported 1;
BA_ "U_P702_MY2021_Tx" SG_ 548 DSP_Chimes_Supported 1;
BA_ "U_P702_MY2021_Rx" SG_ 548 DSP_Chimes_Supported 1;
BA_ "U_U55X_MY2022_Rx" SG_ 548 DSP_Chimes_Supported 1;
BA_ "U_CD542_MY2021_Rx" SG_ 548 DSP_Chimes_Supported 1;
BA_ "U_T6_MCA_MY2020_Rx" SG_ 548 DSP_Chimes_Supported 1;
BA_ "GenSigSendType" SG_ 548 DSP_Chimes_Supported 3;
BA_ "U_U55X_MY2022_Tx" SG_ 548 DSP_AdjChimVolSupp_St 1;
BA_ "U_CD542_MY2021_Tx" SG_ 548 DSP_AdjChimVolSupp_St 1;
BA_ "U_T6_MCA_MY2020_Tx" SG_ 548 DSP_AdjChimVolSupp_St 1;
BA_ "U_P702_MY2021_Tx" SG_ 548 DSP_AdjChimVolSupp_St 1;
BA_ "U_U55X_MY2022_Rx" SG_ 548 DSP_AdjChimVolSupp_St 1;
BA_ "U_T6_MCA_MY2020_Rx" SG_ 548 DSP_AdjChimVolSupp_St 1;
BA_ "GenSigSendType" SG_ 548 DSP_AdjChimVolSupp_St 3;
BA_ "U_U55X_MY2022_Tx" SG_ 548 DSP_AdjChimVolSupp2_St 1;
BA_ "U_CD542_MY2021_Tx" SG_ 548 DSP_AdjChimVolSupp2_St 1;
BA_ "U_T6_MCA_MY2020_Tx" SG_ 548 DSP_AdjChimVolSupp2_St 1;
BA_ "U_P702_MY2021_Tx" SG_ 548 DSP_AdjChimVolSupp2_St 1;
BA_ "U_U55X_MY2022_Rx" SG_ 548 DSP_AdjChimVolSupp2_St 1;
BA_ "U_T6_MCA_MY2020_Rx" SG_ 548 DSP_AdjChimVolSupp2_St 1;
BA_ "GenSigSendType" SG_ 548 DSP_AdjChimVolSupp2_St 3;
BA_ "U_U55X_MY2022_Tx" SG_ 548 DSP_AHU_ChmTstT 1;
BA_ "U_T6_MCA_MY2020_Tx" SG_ 548 DSP_AHU_ChmTstT 1;
BA_ "U_CD542_MY2021_Rx" SG_ 548 DSP_AHU_ChmTstT 1;
BA_ "U_U55X_MY2022_Rx" SG_ 548 DSP_AHU_ChmTstT 1;
BA_ "U_T6_MCA_MY2020_Rx" SG_ 548 DSP_AHU_ChmTstT 1;
BA_ "U_P702_MY2021_Rx" SG_ 548 DSP_AHU_ChmTstT 1;
BA_ "GenSigSendType" SG_ 548 DSP_AHU_ChmTstT 3;
BA_ "U_U55X_MY2022_Tx" SG_ 548 DspDgtlChime_D_Stat 1;
BA_ "U_T6_MCA_MY2020_Tx" SG_ 548 DspDgtlChime_D_Stat 1;
BA_ "U_CD542_MY2021_Rx" SG_ 548 DspDgtlChime_D_Stat 1;
BA_ "U_U55X_MY2022_Rx" SG_ 548 DspDgtlChime_D_Stat 1;
BA_ "U_T6_MCA_MY2020_Rx" SG_ 548 DspDgtlChime_D_Stat 1;
BA_ "U_P702_MY2021_Rx" SG_ 548 DspDgtlChime_D_Stat 1;
BA_ "GenSigSendType" SG_ 548 DspDgtlChime_D_Stat 3;
BA_ "U_T6_MCA_MY2020_Tx" SG_ 404 Dsp_LangUpdate_Rsp 1;
BA_ "U_P702_MY2021_Tx" SG_ 404 Dsp_LangUpdate_Rsp 1;
BA_ "U_U55X_MY2022_Tx" SG_ 404 Dsp_LangUpdate_Rsp 1;
BA_ "U_CD542_MY2021_Tx" SG_ 404 Dsp_LangUpdate_Rsp 1;
BA_ "U_U55X_MY2022_Rx" SG_ 404 Dsp_LangUpdate_Rsp 1;
BA_ "U_CD542_MY2021_Rx" SG_ 404 Dsp_LangUpdate_Rsp 1;
BA_ "U_T6_MCA_MY2020_Rx" SG_ 404 Dsp_LangUpdate_Rsp 1;
BA_ "GenSigSendType" SG_ 404 Dsp_LangUpdate_Rsp 3;
BA_ "U_U55X_MY2022_Tx" SG_ 689 AUDIO_MC_WORD_Tx 1;
BA_ "U_CD542_MY2021_Tx" SG_ 689 AUDIO_MC_WORD_Tx 1;
BA_ "U_T6_MCA_MY2020_Tx" SG_ 689 AUDIO_MC_WORD_Tx 1;
BA_ "U_P702_MY2021_Tx" SG_ 689 AUDIO_MC_WORD_Tx 1;
BA_ "U_U55X_MY2022_Rx" SG_ 689 AUDIO_MC_WORD_Tx 1;
BA_ "U_CD542_MY2021_Rx" SG_ 689 AUDIO_MC_WORD_Tx 1;
BA_ "U_T6_MCA_MY2020_Rx" SG_ 689 AUDIO_MC_WORD_Tx 1;
VAL_ 643 StrtInGearMsgTxt_D_Rq_UB 1 "Fresh_data" 0 "Unchanged_data" ;
VAL_ 643 StrtInGearMsgTxt_D_Rq 15 "Message15" 14 "Message14" 13 "Message13" 12 "Message12" 11 "Message11" 10 "Message10" 9 "Message9" 8 "Message8" 7 "Message7" 6 "Message6" 5 "Message5" 4 "Message4" 3 "Message3" 2 "Message2" 1 "Message1" 0 "NoMessage" ;
VAL_ 643 StabBarCnnct_D_Stat_UB 1 "Fresh_data" 0 "Unchanged_data" ;
VAL_ 643 StabBarCnnct_D_Stat 15 "Faulty" 14 "NotUsed_7" 13 "NotUsed_6" 12 "NotUsed_5" 11 "NotUsed_4" 10 "NotUsed_3" 9 "NotUsed_2" 8 "NotUsed_1" 7 "SbdFailure2" 6 "SbdFailure1" 5 "Shutdown" 4 "NormalClosing" 3 "NormalOpen" 2 "NormalOpening" 1 "NormalClosed" 0 "Initialize" ;
VAL_ 643 GearPos_D_Trg_UB 1 "Fresh_data" 0 "Unchanged_data" ;
VAL_ 643 GearPos_D_Trg 15 "Unknown" 14 "Reverse" 13 "Undefined_5" 12 "Undefined_4" 11 "Undefined_3" 10 "Tenth" 9 "Ninth" 8 "Eighth" 7 "Seventh" 6 "Sixth" 5 "Fifth" 4 "Fourth" 3 "Third" 2 "Second" 1 "First" 0 "Neutral" ;
VAL_ 643 PwTgateStepMsgTxt_B_Rq 1 "DisplayMessage" 0 "NoMessage" ;
VAL_ 643 PwTgateStepMsgTxt_B_Rq_UB 1 "Fresh_data" 0 "Unchanged_data" ;
VAL_ 643 PwTgateMsgTxt_B_Rq_UB 1 "Fresh_data" 0 "Unchanged_data" ;
VAL_ 643 PwTgateLamp_B_Rq_UB 1 "Fresh_data" 0 "Unchanged_data" ;
VAL_ 643 PwTgateMsgTxt_B_Rq 1 "DisplayMessage" 0 "NoMessage" ;
VAL_ 643 PwTgateLamp_B_Rq 1 "On" 0 "Off" ;
VAL_ 643 PwRnngBoardSwtch_D_Stat_UB 1 "Fresh_data" 0 "Unchanged_data" ;
VAL_ 643 PwRnngBoardT_D_Stat_UB 1 "Fresh_data" 0 "Unchanged_data" ;
VAL_ 643 PwRnngBoardT_D_Stat 3 "NotUsed" 2 "Timer2" 1 "Timer1" 0 "Inactive" ;
VAL_ 643 PwRnngBoardSwtch_D_Stat 3 "NotUsed" 2 "DeployUnlocked" 1 "AlwaysActive" 0 "Inactive" ;
VAL_ 643 OnePdlDrvLamp_B_Rq_UB 1 "Fresh_data" 0 "Unchanged_data" ;
VAL_ 643 OnePdlDrv_D_Dsply_UB 1 "Fresh_data" 0 "Unchanged_data" ;
VAL_ 643 OnePdlDrvLamp_B_Rq 1 "On" 0 "Off" ;
VAL_ 643 OnePdlDrv_D_Dsply 3 "Faulty" 2 "Suspended" 1 "On" 0 "Off" ;
VAL_ 643 SeatSlprPosMsgTxt_B_Rq_UB 1 "Fresh_data" 0 "Unchanged_data" ;
VAL_ 643 SeatSlprPosMsgTxt_B_Rq 1 "On" 0 "Off" ;
VAL_ 643 DrPrsntRearPsngr_D_Stat_UB 1 "Fresh_data" 0 "Unchanged_data" ;
VAL_ 643 DrPrsntPsngr_D_Stat_UB 1 "Fresh_data" 0 "Unchanged_data" ;
VAL_ 643 DrPsngrMsgTxt_B_Rq_UB 1 "Fresh_data" 0 "Unchanged_data" ;
VAL_ 643 DrPsngrMsgTxt_B_Rq 1 "Yes" 0 "No" ;
VAL_ 643 DrPrsntRearPsngr_D_Stat 3 "Faulty" 2 "Present" 1 "NotPresent" 0 "NotDetermined" ;
VAL_ 643 DrPrsntPsngr_D_Stat 3 "Faulty" 2 "Present" 1 "NotPresent" 0 "NotDetermined" ;
VAL_ 643 DrPrsntRearDrv_D_Stat_UB 1 "Fresh_data" 0 "Unchanged_data" ;
VAL_ 643 DrDrvMsgTxt_B_Rq_UB 1 "Fresh_data" 0 "Unchanged_data" ;
VAL_ 643 DrPrsntDrv_D_Stat_UB 1 "Fresh_data" 0 "Unchanged_data" ;
VAL_ 643 DrPrsntDrv_D_Stat 3 "Faulty" 2 "Present" 1 "NotPresent" 0 "NotDetermined" ;
VAL_ 643 DrPrsntRearDrv_D_Stat 3 "Faulty" 2 "Present" 1 "NotPresent" 0 "NotDetermined" ;
VAL_ 643 DrDrvMsgTxt_B_Rq 1 "Yes" 0 "No" ;
VAL_ 643 FstChrgCmplt_T_Est_UB 1 "Fresh_data" 0 "Unchanged_data" ;
VAL_ 643 TrunkFrontOpen_D_Stat_UB 1 "Fresh_data" 0 "Unchanged_data" ;
VAL_ 643 TrunkFrontOpen_D_Stat 3 "NotUsed" 2 "NotRestricted" 1 "Restricted" 0 "Null" ;
VAL_ 876 SeatIntnsPsngrRr_D_Stat 7 "NotUsed_3" 6 "NotUsed_2" 5 "NotUsed_1" 4 "High" 3 "Medium" 2 "Low" 1 "Off" 0 "Null" ;
VAL_ 876 SeatMasgPsngrRr_D_Stat 15 "NotUsed_10" 14 "NotUsed_9" 13 "NotUsed_8" 12 "NotUsed_7" 11 "NotUsed_6" 10 "NotUsed_5" 9 "NotUsed_4" 8 "NotUsed_3" 7 "NotUsed_2" 6 "NotUsed_1" 5 "Pattern5" 4 "Pattern4" 3 "Pattern3" 2 "Pattern2" 1 "Pattern1" 0 "Null" ;
VAL_ 876 SeatSwtchRr_B_Stat 1 "On" 0 "Off" ;
VAL_ 876 SeatPRr_B_Stat 1 "Updating" 0 "NotUpdating" ;
VAL_ 876 SeatFnRr_D_Stat 7 "CushionMassage" 6 "LumbarMassage" 5 "UpperBolster" 4 "LowerBolster" 3 "UpperLumbar" 2 "MiddleLumbar" 1 "LowerLumbar" 0 "Null" ;
VAL_ 876 StmsCshnPsgr_D_Stat2 3 "High" 2 "Low" 1 "Off" 0 "Null" ;
VAL_ 876 StmsLmbrPsgr_D_Stat2 3 "High" 2 "Low" 1 "Off" 0 "Null" ;
VAL_ 875 SeatIntnsDrvRr_D_Stat 7 "NotUsed_3" 6 "NotUsed_2" 5 "NotUsed_1" 4 "High" 3 "Medium" 2 "Low" 1 "Off" 0 "Null" ;
VAL_ 875 SeatMasgDrvRr_D_Stat 15 "NotUsed_10" 14 "NotUsed_9" 13 "NotUsed_8" 12 "NotUsed_7" 11 "NotUsed_6" 10 "NotUsed_5" 9 "NotUsed_4" 8 "NotUsed_3" 7 "NotUsed_2" 6 "NotUsed_1" 5 "Pattern5" 4 "Pattern4" 3 "Pattern3" 2 "Pattern2" 1 "Pattern1" 0 "Null" ;
VAL_ 875 SeatSwtchRl_B_Stat 1 "On" 0 "Off" ;
VAL_ 875 SeatPRl_B_Stat 1 "Updating" 0 "NotUpdating" ;
VAL_ 875 SeatFnRl_D_Stat 7 "CushionMassage" 6 "LumbarMassage" 5 "UpperBolster" 4 "LowerBolster" 3 "UpperLumbar" 2 "MiddleLumbar" 1 "LowerLumbar" 0 "Null" ;
VAL_ 875 StmsLmbrDrv_D_Stat2 3 "High" 2 "Low" 1 "Off" 0 "Null" ;
VAL_ 875 StmsCshnDrv_D_Stat2 3 "High" 2 "Low" 1 "Off" 0 "Null" ;
VAL_ 841 FohAddHeater_D_Stat 3 "NotUsed" 2 "On" 1 "Off" 0 "NoModeSelected" ;
VAL_ 545 SpkrDgtlRight_D_Stat 3 "Faulty" 2 "Normal" 1 "NotPresent" 0 "Null" ;
VAL_ 545 SpkrDgtlLeft_D_Stat 3 "Faulty" 2 "Normal" 1 "NotPresent" 0 "Null" ;
VAL_ 545 SpkrDgtlCntr_D_Stat 3 "Faulty" 2 "Normal" 1 "NotPresent" 0 "Null" ;
VAL_ 545 SurndSndUpmix2_D_Stat 4 "Audience" 3 "On_Stage" 2 "Surround" 1 "Stereo" 0 "Inactive" ;
VAL_ 545 DSP_Bezel_Diag_St 15 "NotUsed_11" 14 "NotUsed_10" 13 "NotUsed_9" 12 "NotUsed_8" 11 "NotUsed_7" 10 "NotUsed_6" 9 "NotUsed_5" 8 "NotUsed_4" 7 "NotUsed_3" 6 "NotUsed_2" 5 "NotUsed_1" 4 "SpeakerWalkAround" 3 "CalibrationPartNumber" 2 "HardwarePartNumber" 1 "SoftwarePartNumber" 0 "Inactive_NOP" ;
VAL_ 545 SndImmrsnLvl_D_Stat 255 "NotUsed_127" 254 "NotUsed_126" 253 "NotUsed_125" 252 "NotUsed_124" 251 "NotUsed_123" 250 "NotUsed_122" 249 "NotUsed_121" 248 "NotUsed_120" 247 "NotUsed_119" 246 "NotUsed_118" 245 "NotUsed_117" 244 "NotUsed_116" 243 "NotUsed_115" 242 "NotUsed_114" 241 "NotUsed_113" 240 "NotUsed_112" 239 "NotUsed_111" 238 "NotUsed_110" 237 "NotUsed_109" 236 "NotUsed_108" 235 "NotUsed_107" 234 "NotUsed_106" 233 "NotUsed_105" 232 "NotUsed_104" 231 "NotUsed_103" 230 "NotUsed_102" 229 "NotUsed_101" 228 "NotUsed_100" 227 "NotUsed_99" 226 "NotUsed_98" 225 "NotUsed_97" 224 "NotUsed_96" 223 "NotUsed_95" 222 "NotUsed_94" 221 "NotUsed_93" 220 "NotUsed_92" 219 "NotUsed_91" 218 "NotUsed_90" 217 "NotUsed_89" 216 "NotUsed_88" 215 "NotUsed_87" 214 "NotUsed_86" 213 "NotUsed_85" 212 "NotUsed_84" 211 "NotUsed_83" 210 "NotUsed_82" 209 "NotUsed_81" 208 "NotUsed_80" 207 "NotUsed_79" 206 "NotUsed_78" 205 "NotUsed_77" 204 "NotUsed_76" 203 "NotUsed_75" 202 "NotUsed_74" 201 "NotUsed_73" 200 "NotUsed_72" 199 "NotUsed_71" 198 "NotUsed_70" 197 "NotUsed_69" 196 "NotUsed_68" 195 "NotUsed_67" 194 "NotUsed_66" 193 "NotUsed_65" 192 "NotUsed_64" 191 "NotUsed_63" 190 "NotUsed_62" 189 "NotUsed_61" 188 "NotUsed_60" 187 "NotUsed_59" 186 "NotUsed_58" 185 "NotUsed_57" 184 "NotUsed_56" 183 "NotUsed_55" 182 "NotUsed_54" 181 "NotUsed_53" 180 "NotUsed_52" 179 "NotUsed_51" 178 "NotUsed_50" 177 "NotUsed_49" 176 "NotUsed_48" 175 "NotUsed_47" 174 "NotUsed_46" 173 "NotUsed_45" 172 "NotUsed_44" 171 "NotUsed_43" 170 "NotUsed_42" 169 "NotUsed_41" 168 "NotUsed_40" 167 "NotUsed_39" 166 "NotUsed_38" 165 "NotUsed_37" 164 "NotUsed_36" 163 "NotUsed_35" 162 "NotUsed_34" 161 "NotUsed_33" 160 "NotUsed_32" 159 "NotUsed_31" 158 "NotUsed_30" 157 "NotUsed_29" 156 "NotUsed_28" 155 "NotUsed_27" 154 "NotUsed_26" 153 "NotUsed_25" 152 "NotUsed_24" 151 "NotUsed_23" 150 "NotUsed_22" 149 "NotUsed_21" 148 "NotUsed_20" 147 "NotUsed_19" 146 "NotUsed_18" 145 "NotUsed_17" 144 "NotUsed_16" 143 "NotUsed_15" 142 "NotUsed_14" 141 "NotUsed_13" 140 "NotUsed_12" 139 "NotUsed_11" 138 "NotUsed_10" 137 "NotUsed_9" 136 "NotUsed_8" 135 "NotUsed_7" 134 "NotUsed_6" 133 "NotUsed_5" 132 "NotUsed_4" 131 "NotUsed_3" 130 "NotUsed_2" 129 "NotUsed_1" 128 "Level127" 127 "Level126" 126 "Level125" 125 "Level124" 124 "Level123" 123 "Level122" 122 "Level121" 121 "Level120" 120 "Level119" 119 "Level118" 118 "Level117" 117 "Level116" 116 "Level115" 115 "Level114" 114 "Level113" 113 "Level112" 112 "Level111" 111 "Level110" 110 "Level109" 109 "Level108" 108 "Level107" 107 "Level106" 106 "Level105" 105 "Level104" 104 "Level103" 103 "Level102" 102 "Level101" 101 "Level100" 100 "Level99" 99 "Level98" 98 "Level97" 97 "Level96" 96 "Level95" 95 "Level94" 94 "Level93" 93 "Level92" 92 "Level91" 91 "Level90" 90 "Level89" 89 "Level88" 88 "Level87" 87 "Level86" 86 "Level85" 85 "Level84" 84 "Level83" 83 "Level82" 82 "Level81" 81 "Level80" 80 "Level79" 79 "Level78" 78 "Level77" 77 "Level76" 76 "Level75" 75 "Level74" 74 "Level73" 73 "Level72" 72 "Level71" 71 "Level70" 70 "Level69" 69 "Level68" 68 "Level67" 67 "Level66" 66 "Level65" 65 "Level64" 64 "Level63" 63 "Level62" 62 "Level61" 61 "Level60" 60 "Level59" 59 "Level58" 58 "Level57" 57 "Level56" 56 "Level55" 55 "Level54" 54 "Level53" 53 "Level52" 52 "Level51" 51 "Level50" 50 "Level49" 49 "Level48" 48 "Level47" 47 "Level46" 46 "Level45" 45 "Level44" 44 "Level43" 43 "Level42" 42 "Level41" 41 "Level40" 40 "Level39" 39 "Level38" 38 "Level37" 37 "Level36" 36 "Level35" 35 "Level34" 34 "Level33" 33 "Level32" 32 "Level31" 31 "Level30" 30 "Level29" 29 "Level28" 28 "Level27" 27 "Level26" 26 "Level25" 25 "Level24" 24 "Level23" 23 "Level22" 22 "Level21" 21 "Level20" 20 "Level19" 19 "Level18" 18 "Level17" 17 "Level16" 16 "Level15" 15 "Level14" 14 "Level13" 13 "Level12" 12 "Level11" 11 "Level10" 10 "Level9" 9 "Level8" 8 "Level7" 7 "Level6" 6 "Level5" 5 "Level4" 4 "Level3" 3 "Level2" 2 "Level1" 1 "Level0" 0 "Inactive" ;
VAL_ 545 DSP_Sur_Sound_st 2 "Surround" 1 "Stereo" 0 "Inactive" ;
VAL_ 545 DSP_MyKeyVolLimitUp_St 2 "NotUpdated" 1 "Updated" 0 "Invalid" ;
VAL_ 545 DSP_MyKeyVolLim_St 0 "Invalid" 1 "Off" 2 "On" ;
VAL_ 545 DSP_BeltminderAudio_St 0 "Invalid" 1 "Off" 2 "On" ;
VAL_ 545 DSP_Audio_Volume_Up_St 1 "Update" 0 "NoUpdate" ;
VAL_ 545 AutoConfigOcc_Rear 1 "Supported" 0 "Not_Supported" ;
VAL_ 545 AutoConfigOcc_Front 1 "Supported" 0 "Not_Supported" ;
VAL_ 545 AutoConfigOcc_Driver 1 "Supported" 0 "Not_Supported" ;
VAL_ 545 AutoConfigOcc_AllSeats 1 "Supported" 0 "Not_Supported" ;
VAL_ 545 AudioOccMde_D_Stat 15 "Reserved9" 14 "Reserved8" 13 "Reserved7" 12 "Reserved6" 11 "Reserved5" 10 "Reserved4" 9 "Convertible" 8 "RearSeats" 7 "FrontSeats" 6 "Reserved3" 5 "Reserved2" 4 "Reserved1" 3 "Passenger" 2 "Driver" 1 "All" 0 "Invalid" ;
VAL_ 1058 StopStrtVThres_D_Stat_UB 1 "Fresh_data" 0 "Unchanged_data" ;
VAL_ 1058 StopStrtVThres_D_Stat 3 "High" 2 "Medium" 1 "Low" 0 "NoSelection" ;
VAL_ 1058 ChrgPortDrOpen_B_Stat 1 "True" 0 "False" ;
VAL_ 1058 ChrgPortDrOpen_B_Stat_UB 1 "Fresh_data" 0 "Unchanged_data" ;
VAL_ 633 RearDiffLckMsg2_D_Rq_UB 1 "Fresh_data" 0 "Unchanged_data" ;
VAL_ 633 RearDiffLckMsg2_D_Rq 15 "NotUsed_3" 14 "NotUsed_2" 13 "NotUsed_1" 12 "ElsdReduced" 11 "LockingFeatureNotAvailable" 10 "EsldOff" 9 "ElsdRestored" 8 "ElsdOverheated" 7 "Locker_Disabled" 6 "Locker_Enabled" 5 "LockerSpeed5" 4 "LockerSpeed4" 3 "LockerSpeed3" 2 "LockerSpeed2" 1 "LockerSpeed1" 0 "NormalNoMessage " ;
VAL_ 633 PwStepMsgTxt_D_Rq_UB 1 "Fresh_data" 0 "Unchanged_data" ;
VAL_ 633 PwStepMsgTxt_D_Rq 1 "DriveInhibited" 0 "NoMessage" 3 "NotUsed" 2 "Malfunction" ;
VAL_ 633 RearDiffLck_D_RqDrv 3 "Faulty" 2 "NoRequest" 1 "On" 0 "Off" ;
VAL_ 633 AwdMde_D_RqDrv 7 "Faulty" 6 "NotUsed2" 5 "NoRequest" 4 "Neutral" 3 "FourByFourLow" 2 "FourByFourHigh" 1 "FourByFourAuto" 0 "FourByTwo" ;
VAL_ 633 RearDiffLck_D_RqDrv_UB 1 "Fresh_data" 0 "Unchanged_data" ;
VAL_ 633 TsrRegionTxt_D_Stat_UB 1 "Fresh_data" 0 "Unchanged_data" ;
VAL_ 633 AwdMde_D_RqDrv_UB 1 "Fresh_data" 0 "Unchanged_data" ;
VAL_ 633 TsrRegionTxt_D_Stat 31 "Faulty" 30 "NotUsed_8" 29 "NotUsed_7" 28 "NotUsed_6" 27 "NotUsed_5" 26 "NotUsed_4" 25 "NotUsed_3" 24 "NotUsed_2" 23 "NotUsed_1" 22 "Region_22" 21 "Region_21" 20 "Region_20" 19 "Region_19" 18 "Region_18" 17 "Region_17" 16 "Region_16" 15 "Region_15" 14 "Region_14" 13 "Region_13" 12 "Region_12" 11 "Region_11" 10 "Region_10" 9 "Region_09" 8 "Region_08" 7 "Region_07" 6 "Region_06" 5 "Region_05" 4 "Region_04" 3 "Region_03" 2 "Region_02" 1 "Region_01" 0 "NotDetermined" ;
VAL_ 633 GsmGearMsgTxt_D_Rq_UB 1 "Fresh_data" 0 "Unchanged_data" ;
VAL_ 633 GsmGearMsgTxt_D_Rq 3 "Message3" 2 "Message2" 1 "Message1" 0 "NoMessage" ;
VAL_ 633 RearDiffLckLamp_D_Rq2_UB 1 "Fresh_data" 0 "Unchanged_data" ;
VAL_ 633 RearDiffLckLamp_D_Rq2 3 "Triggered" 2 "Flash" 1 "On" 0 "Off" ;
VAL_ 633 DasAlrtInfo_D_Dsply_UB 1 "Fresh_data" 0 "Unchanged_data" ;
VAL_ 633 DasAlrtInfo_D_Dsply 3 "NotUsed" 2 "On" 1 "Off" 0 "Null" ;
VAL_ 633 Shed_Feature_Group_ID_UB 1 "Fresh_data" 0 "Unchanged_data" ;
VAL_ 633 Shed_Feature_Group_ID 16 "PtcHeater" 30 "NotUsed_7" 29 "NotUsed_6" 28 "NotUsed_5" 27 "NotUsed_4" 26 "NotUsed_3" 25 "NotUsed_2" 24 "NotUsed_1" 23 "Dcac" 22 "UpFitter_6" 21 "UpFitter_5" 20 "UpFitter_4" 19 "UpFitter_3" 18 "UpFitter_2" 17 "UpFitter_1" 14 "HtdMirr" 13 "HvacRearBlwr_Third" 12 "HvacRearBlwr_Second" 11 "HvacRearBlwr_First" 31 "All LSHED1 Features" 10 "Htd_Windscrn" 9 "SpltHtdBcklight_HtdMirr" 8 "HtdBcklight_HtdMirr" 7 "HtdCoolSeat_FrtDriver" 6 "HtdCoolSeat_FrtPass" 5 "HtdCoolSeat_RearPass" 4 "HtdCoolSeat_RearDriver" 3 "SmartTrlrTowBattCharge" 2 "Htd_StrWhl" 1 "Htd_Washer_Fluid" 0 "No_LSHED1_Features" 15 "Engine_Coolant_Fan" ;
VAL_ 936 ApaButtnPrssd_B_Stat 1 "Pressed" 0 "Not_Pressed" ;
VAL_ 936 ApaSys_D_Stat 7 "Faulty" 6 "Finished" 5 "NotAccessible" 4 "ApaCancelled" 3 "Overspeed" 2 "On" 1 "Off" 0 "Null" ;
VAL_ 936 ApaSteWhl_D_RqDrv 3 "TakeControl" 2 "RemoveHands" 1 "NoRequest" 0 "Null" ;
VAL_ 936 ApaSteScanMde_D_Stat 3 "Steering" 2 "Scanning" 1 "NotScanning" 0 "Null" ;
VAL_ 936 ApaSelSapp_D_Stat 3 "NotConfigured" 2 "NotSelectable" 1 "Selectable" 0 "Null" ;
VAL_ 936 ApaSelPpa_D_Stat 3 "NotConfigured" 2 "NotSelectable" 1 "Selectable" 0 "Null" ;
VAL_ 936 ApaSelPoa_D_Stat 3 "NotConfigured" 2 "NotSelectable" 1 "Selectable" 0 "Null" ;
VAL_ 936 ApaScan_D_Stat 3 "ParkSlotReady" 2 "ParkSlotFound" 1 "NoParkSlot" 0 "Null" ;
VAL_ 936 ApaLongCtl_D_RqDrv 7 "NotUsed3" 6 "NotUsed2" 5 "ReleaseBrake" 4 "DriveBackward" 3 "DriveForward" 2 "Stop" 1 "NoRequest" 0 "Null" ;
VAL_ 936 ApaGearShif_D_RqDrv 7 "NotUSed2" 6 "NotUsed1" 5 "ShiftToP" 4 "ShiftToN" 3 "ShiftToD" 2 "ShiftToR" 1 "NoRequest" 0 "Null" ;
VAL_ 936 ApaActvSide2_D_Stat 3 "NoSide" 2 "Right" 1 "Left" 0 "Null" ;
VAL_ 936 ApaAcsy_D_RqDrv 7 "CloseDoor" 6 "SelectSideRight" 5 "SelectSideLeft" 4 "CheckForObject" 3 "PressApaButton" 2 "SelectSide" 1 "NoRequest" 0 "Null" ;
VAL_ 936 ApaChime_D_Rq 7 "NotUsed2" 6 "NotUsed1" 5 "Warning_Chime" 4 "Finish_Chime" 3 "Stop_Now_Chime" 2 "Spot_Ready_Chime" 1 "Spot_Found_Chime" 0 "No_Chime" ;
VAL_ 936 EPASExtAngleStatReq 1 "Request" 0 "NoRequest" ;
VAL_ 936 ExtSteeringAngleReq2 32767 "Invalid" 32766 "Unknown" ;
VAL_ 936 ApaTrgtDist_D_Stat 15 "Step15" 14 "Step14" 13 "Step13" 12 "Step12" 11 "Step11" 10 "Step10" 9 "Step9" 8 "Step8" 7 "Step7" 6 "Step6" 5 "Step5" 4 "Step4" 3 "Step3" 2 "Step2" 1 "Step1" 0 "Off" ;
VAL_ 936 ApaMsgTxt_D_Rq 15 "NotUsed_6" 14 "NotUsed_5" 13 "NotUsed_4" 12 "NotUsed_3" 11 "ReleaseEpb" 10 "TrailerFeatureNotAvailable" 9 "AccelPedalInactive" 8 "WrongDirection" 7 "SteeringInteraction" 6 "BrakingActive" 5 "HighInclination" 4 "SpeedLimitExceeded" 3 "TcsDisabled" 2 "WheelSlip" 1 "None" 0 "Null" ;
VAL_ 674 ArmrestStwdRear_B_Stat 1 "Yes" 0 "No" ;
VAL_ 674 RACM_Coding_BtnID_D 1 "Pressed" 0 "Not_Pressed" ;
VAL_ 674 RACM_Coding_BtnID_C 1 "Pressed" 0 "Not_Pressed" ;
VAL_ 674 RACM_Coding_BtnID_B 1 "Pressed" 0 "Not_Pressed" ;
VAL_ 674 RACM_Coding_BtnID_A 1 "Pressed" 0 "Not_Pressed" ;
VAL_ 674 RearAudioCtlLck_D_Stat 2 "Unlocked" 1 "Locked" 0 "Null" ;
VAL_ 75 VedsPasKneeBag_D_Ltchd 7 "Fault" 6 "NotSupported" 5 "Unused_3" 4 "Unused_2" 3 "Unused_1" 2 "NotDeployed" 1 "Deployed" 0 "NoEvent" ;
VAL_ 75 VedsRw1mBckl_D_Ltchd 5 "Unused_3" 4 "Unused_2" 3 "Unused_1" 2 "NotBelted" 1 "Belted" 0 "NoEvent" 7 "Fault" 6 "NotSupported" ;
VAL_ 75 VedsRw1mBelt_D_Ltchd 7 "Fault" 6 "NotSupported" 5 "Unused_3" 4 "Unused_2" 3 "Unused_1" 2 "NotDeployed" 1 "Deployed" 0 "NoEvent" ;
VAL_ 75 VedsRw2pRib_D_Ltchd 7 "Fault" 6 "NotSupported" 5 "Unused_3" 4 "Unused_2" 3 "Unused_1" 2 "NotDeployed" 1 "Deployed" 0 "NoEvent" ;
VAL_ 75 VedsRw2dRib_D_Ltchd 7 "Fault" 6 "NotSupported" 5 "Unused_3" 4 "Unused_2" 3 "Unused_1" 2 "NotDeployed" 1 "Deployed" 0 "NoEvent" ;
VAL_ 75 VedsRw3pBckl_D_Ltchd 5 "Unused_3" 4 "Unused_2" 3 "Unused_1" 2 "NotBelted" 1 "Belted" 0 "NoEvent" 7 "Fault" 6 "NotSupported" ;
VAL_ 75 VedsRw3mBckl_D_Ltchd 5 "Unused_3" 4 "Unused_2" 3 "Unused_1" 2 "NotBelted" 1 "Belted" 0 "NoEvent" 7 "Fault" 6 "NotSupported" ;
VAL_ 75 VedsRw3dBckl_D_Ltchd 5 "Unused_3" 4 "Unused_2" 3 "Unused_1" 2 "NotBelted" 1 "Belted" 0 "NoEvent" 7 "Fault" 6 "NotSupported" ;
VAL_ 75 VedsRw2pBckl_D_Ltchd 5 "Unused_3" 4 "Unused_2" 3 "Unused_1" 2 "NotBelted" 1 "Belted" 0 "NoEvent" 7 "Fault" 6 "NotSupported" ;
VAL_ 75 VedsRw2mBckl_D_Ltchd 5 "Unused_3" 4 "Unused_2" 3 "Unused_1" 2 "NotBelted" 1 "Belted" 0 "NoEvent" 7 "Fault" 6 "NotSupported" ;
VAL_ 75 VedsRw2dBckl_D_Ltchd 5 "Unused_3" 4 "Unused_2" 3 "Unused_1" 2 "NotBelted" 1 "Belted" 0 "NoEvent" 7 "Fault" 6 "NotSupported" ;
VAL_ 75 VedsRw1PasChld_D_Ltchd 7 "Fault" 6 "NotSupported" 5 "Unused_3" 4 "Unused_2" 3 "Unused_1" 2 "ChildNotDetected" 1 "ChildDetected" 0 "NoEvent" ;
VAL_ 75 VedsRw1PasBckl_D_Ltchd 5 "Unused_3" 4 "Unused_2" 3 "Unused_1" 2 "NotBelted" 1 "Belted" 0 "NoEvent" 7 "Fault" 6 "NotSupported" ;
VAL_ 75 VedsRw1DrvBckl_D_Ltchd 5 "Unused_3" 4 "Unused_2" 3 "Unused_1" 2 "NotBelted" 1 "Belted" 0 "NoEvent" 7 "Fault" 6 "NotSupported" ;
VAL_ 75 VedsRw3pRib_D_Ltchd 7 "Fault" 6 "NotSupported" 5 "Unused_3" 4 "Unused_2" 3 "Unused_1" 2 "NotDeployed" 1 "Deployed" 0 "NoEvent" ;
VAL_ 75 VedsRw3dRib_D_Ltchd 7 "Fault" 6 "NotSupported" 5 "Unused_3" 4 "Unused_2" 3 "Unused_1" 2 "NotDeployed" 1 "Deployed" 0 "NoEvent" ;
VAL_ 74 VedsPasSideBag_D_Ltchd 7 "Fault" 6 "NotSupported" 5 "Unused_3" 4 "Unused_2" 3 "Unused_1" 2 "NotDeployed" 1 "Deployed" 0 "NoEvent" ;
VAL_ 74 VedsPasCrtnBag_D_Ltchd 7 "Fault" 6 "NotSupported" 5 "Unused_3" 4 "Unused_2" 3 "Unused_1" 2 "NotDeployed" 1 "Deployed" 0 "NoEvent" ;
VAL_ 74 VedsPasBelt_D_Ltchd 7 "Fault" 6 "NotSupported" 5 "Unused_3" 4 "Unused_2" 3 "Unused_1" 2 "NotDeployed" 1 "Deployed" 0 "NoEvent" ;
VAL_ 74 VedsPasBag_D_Ltchd 7 "Fault" 6 "NotSupported" 5 "Unused_3" 4 "Unused_2" 3 "Unused_1" 2 "NotDeployed" 1 "Deployed" 0 "NoEvent" ;
VAL_ 74 VedsMultiEvnt_D_Ltchd 7 "Fault" 6 "NotSupported" 5 "Unused_3" 4 "Unused_2" 3 "Unused_1" 2 "Yes" 1 "No" 0 "NoEvent" ;
VAL_ 74 VedsMaxDeltaV_D_Ltchd 0 "NoEvent" 255 "Fault" 254 "NotSupported" ;
VAL_ 74 VedsDrvKneeBag_D_Ltchd 7 "Fault" 6 "NotSupported" 5 "Unused_3" 4 "Unused_2" 3 "Unused_1" 2 "NotDeployed" 1 "Deployed" 0 "NoEvent" ;
VAL_ 74 VedsEvntType_D_Ltchd 7 "Fault" 6 "NotSupported" 5 "Unused" 4 "Rolllover" 3 "Rear" 2 "Side" 1 "Frontal" 0 "NoEvent" ;
VAL_ 74 VedsEvntRoll_D_Ltchd 7 "Fault" 6 "NotSupported" 5 "Unused_3" 4 "Unused_2" 3 "Unused_1" 2 "Yes" 1 "No" 0 "NoEvent" ;
VAL_ 74 VedsDrvSideBag_D_Ltchd 7 "Fault" 6 "NotSupported" 5 "Unused_3" 4 "Unused_2" 3 "Unused_1" 2 "NotDeployed" 1 "Deployed" 0 "NoEvent" ;
VAL_ 74 VedsDrvCrtnBag_D_Ltchd 7 "Fault" 6 "NotSupported" 5 "Unused_3" 4 "Unused_2" 3 "Unused_1" 2 "NotDeployed" 1 "Deployed" 0 "NoEvent" ;
VAL_ 74 VedsDrvBelt_D_Ltchd 7 "Fault" 6 "NotSupported" 5 "Unused_3" 4 "Unused_2" 3 "Unused_1" 2 "NotDeployed" 1 "Deployed" 0 "NoEvent" ;
VAL_ 74 VedsDrvBag_D_Ltchd 7 "Fault" 6 "NotSupported" 5 "Unused_3" 4 "Unused_2" 3 "Unused_1" 2 "NotDeployed" 1 "Deployed" 0 "NoEvent" ;
VAL_ 74 eCallNotification 3 "Not_Used" 2 "Active" 1 "Normal" 0 "Not_Supported" ;
VAL_ 780 TrlrTireSensRm_D_Stat 15 "NotSupported" 14 "NotUsed10" 13 "NotUsed9" 12 "NotUsed8" 11 "NotUsed7" 10 "NotUsed6" 9 "NotUsed5" 8 "NotUsed4" 7 "NotUsed3" 6 "NotUsed2" 5 "NotUsed1" 4 "Alert" 3 "Fault" 2 "Low" 1 "Normal" 0 "Unknown" ;
VAL_ 780 TrlrTireSensRf_D_Stat 15 "NotSupported" 14 "NotUsed10" 13 "NotUsed9" 12 "NotUsed8" 11 "NotUsed7" 10 "NotUsed6" 9 "NotUsed5" 8 "NotUsed4" 7 "NotUsed3" 6 "NotUsed2" 5 "NotUsed1" 4 "Alert" 3 "Fault" 2 "Low" 1 "Normal" 0 "Unknown" ;
VAL_ 780 TrlrTireRr_P_Actl 65534 "Invalid" 65535 "NotSupported" ;
VAL_ 780 TrlrTireRm_P_Actl 65534 "Invalid" 65535 "NotSupported" ;
VAL_ 780 TrlrTireRf_P_Actl 65534 "Invalid" 65535 "NotSupported" ;
VAL_ 780 TrlrTireSensRr_D_Stat 15 "NotSupported" 14 "NotUsed10" 13 "NotUsed9" 12 "NotUsed8" 11 "NotUsed7" 10 "NotUsed6" 9 "NotUsed5" 8 "NotUsed4" 7 "NotUsed3" 6 "NotUsed2" 5 "NotUsed1" 4 "Alert" 3 "Fault" 2 "Low" 1 "Normal" 0 "Unknown" ;
VAL_ 779 TrlrTireSensLr_D_Stat 15 "NotSupported" 14 "NotUsed10" 13 "NotUsed9" 12 "NotUsed8" 11 "NotUsed7" 10 "NotUsed6" 9 "NotUsed5" 8 "NotUsed4" 7 "NotUsed3" 6 "NotUsed2" 5 "NotUsed1" 4 "Alert" 3 "Fault" 2 "Low" 1 "Normal" 0 "Unknown" ;
VAL_ 779 TrlrTireSensLm_D_Stat 15 "NotSupported" 14 "NotUsed10" 13 "NotUsed9" 12 "NotUsed8" 11 "NotUsed7" 10 "NotUsed6" 9 "NotUsed5" 8 "NotUsed4" 7 "NotUsed3" 6 "NotUsed2" 5 "NotUsed1" 4 "Alert" 3 "Fault" 2 "Low" 1 "Normal" 0 "Unknown" ;
VAL_ 779 TrlrTireSensLf_D_Stat 15 "NotSupported" 14 "NotUsed10" 13 "NotUsed9" 12 "NotUsed8" 11 "NotUsed7" 10 "NotUsed6" 9 "NotUsed5" 8 "NotUsed4" 7 "NotUsed3" 6 "NotUsed2" 5 "NotUsed1" 4 "Alert" 3 "Fault" 2 "Low" 1 "Normal" 0 "Unknown" ;
VAL_ 779 TrlrTireLr_P_Actl 65534 "Invalid" 65535 "NotSupported" ;
VAL_ 779 TrlrTireLm_P_Actl 65534 "Invalid" 65535 "NotSupported" ;
VAL_ 779 TrlrTireLf_P_Actl 65534 "Invalid" 65535 "NotSupported" ;
VAL_ 783 TrlrTireCnt_D_RqDrv 7 "Faulty" 6 "NotUsed_3" 5 "NotUsed_2" 4 "NotUsed_1" 3 "Six_Tire" 2 "Four_Tire" 1 "Two_Tire" 0 "Unconfigured" ;
VAL_ 783 TrlrLearnMdeOn_B_RqDrv 1 "True" 0 "False" ;
VAL_ 638 EmgcyCallHmi_D_Stat 15 "NotUsed_1" 14 "Standby" 13 "Disabled" 12 "Malfunction" 11 "CallCompleted" 10 "CallDisconnected" 9 "CallNotPossible" 8 "CallCancelled" 7 "CallRetry" 6 "CallConnected" 5 "CallInProgress" 4 "CallMsdTransfer" 3 "CallDial" 2 "CallCancelTimer" 1 "NoEvent" 0 "Null" ;
VAL_ 638 EmgcyCallFalt_B_Dsply 1 "Yes" 0 "No" ;
VAL_ 638 EmgcyCall_D_Stat 7 "NotUsed_3" 6 "NotUsed_2" 5 "NotUsed_1" 4 "ManualEmergencyCall" 3 "AutoEmergencyCall" 2 "NoEvent" 1 "EmergencyCallNotSupported" 0 "Null" ;
VAL_ 555 HudVertSzMnuOn_B_Stat 1 "On" 0 "Off" ;
VAL_ 555 HudVertMnuOn_B_Stat 1 "Yes" 0 "No" ;
VAL_ 555 HudTestMdeActv_B_Stat 1 "Active" 0 "Inactive" ;
VAL_ 555 HudSwtch_B_Stat 1 "Pressed" 0 "Not_Pressed" ;
VAL_ 555 HudRotatMnuOn_B_Stat 1 "Yes" 0 "No" ;
VAL_ 555 HudMsgTxt_D_Rq 7 "Message7" 6 "Message6" 5 "Message5" 4 "Message4" 3 "Message3" 2 "Message2" 1 "Message1" 0 "NoMessage" ;
VAL_ 555 HudHzntlMnuOn_B_Stat 1 "Yes" 0 "No" ;
VAL_ 555 HudBrightMnuOn_B_Stat 1 "Yes" 0 "No" ;
VAL_ 555 HudActv_D_Stat 7 "Faulty" 6 "NotUsed_2" 5 "NotUsed_1" 4 "Error" 3 "Active" 2 "Pending" 1 "Inactive" 0 "NoData" ;
VAL_ 124 VehTrvlDir_D_Stat 7 "Faulty" 6 "NoDataExists" 5 "NotUsed2" 4 "NotUsed1" 3 "Reverse" 2 "LikelyReverse" 1 "Forward" 0 "LikelyForward" ;
VAL_ 124 VehOverGnd_V_Est 65535 "Invalid" 65534 "Unknown" ;
VAL_ 124 VehLongComp_A_Actl 1023 "Fault" 1022 "NoDataExists" ;
VAL_ 124 VehLatComp_A_Actl 1023 "Fault" 1022 "NoDataExists" ;
VAL_ 124 VehYawComp_W_Actl 4095 "Fault" 4094 "NoDataExists" ;
VAL_ 736 TextMessage_Rsp 3 "Cancelled" 2 "MessageIgnored" 1 "Listening" 0 "Invalid" ;
VAL_ 736 VRM_IncCallOption_St 0 "Inactive" 1 "RejectAll" 2 "AcceptIncomingCall" 3 "Silent" ;
VAL_ 736 BTInCallOptions_St 6 "HoldModeoff" 5 "InHoldMode" 4 "InHandsFreeMode" 3 "InPrivacyMode" 2 "Joined" 1 "Switched" 0 "Inactive" ;
VAL_ 722 VRM_ComShuffleTrack_St 0 "Invalid" 1 "CommandNotIssued" 2 "On" 3 "Off" ;
VAL_ 722 VRM_ComCompression_St 0 "Invalid" 1 "CommandNotIssued" 2 "On" 3 "Off" ;
VAL_ 722 VRM_ComStFreqMode_St 0 "Invalid" 1 "CommandNotIssued" 2 "Fm" 3 "Am" 4 "Reserved" ;
VAL_ 722 VRM_ComAutostore_St 0 "Invalid" 1 "CommandNotIssued" 2 "PerfomAutostore" ;
VAL_ 722 VRM_ComBand_St 0 "Invalid" 1 "CommandNotIssued" 2 "Fm1" 3 "Fm2" 4 "Fmas" 5 "Am" 6 "Amas" 7 "AutostoreMode" ;
VAL_ 722 VRM_TMCVoice 0 "Invalid" 1 "CommandNotIssued" 2 "On" 3 "Off" ;
VAL_ 722 VRM_NewSMS 3 "UnreadSMSMessagesAvailable" 0 "Invalid" 1 "NewSmsAvailable" 2 "NoNewSmsAvailable" ;
VAL_ 722 VRM_ComRSEDisplay_St 0 "Invalid" 1 "CommandNotIssued" 2 "On" 3 "Off" ;
VAL_ 722 VRM_ComPresetCall_St 0 "Invalid" 1 "CommandNotIssued" 2 "Prescall1" 3 "Prescall2" 4 "Prescall3" 5 "Prescall4" 6 "Prescall5" 7 "Prescall6" ;
VAL_ 722 VRM_ComTape_St 0 "Invalid" 1 "CommandNotIssued" 2 "Play" 3 "Rewind" 4 "Forward" 5 "ChangeSide" 6 "AutosearchForward" 7 "AutosearchBackward" ;
VAL_ 722 VRM_ComShuffleDiscs_St 0 "Invalid" 1 "CommandNotIssued" 2 "On" 3 "Off" ;
VAL_ 722 VRM_ComDolbyNR_St 0 "Invalid" 1 "CommandNotIssued" 2 "On" 3 "Off" ;
VAL_ 722 VRM_ComSourceSelect_St 7 "BTAudio" 6 "Con" 0 "Invalid" 1 "CommandNotIssued" 2 "Radio" 3 "SDCard" 4 "SingleDisc" 5 "MultiDisc" ;
VAL_ 722 VRM_ComRouteStrategy_St 0 "Invalid" 1 "CommandNotIssued" 2 "Shortesttime" 3 "Shortestdistance" 4 "Majorroadsavoid" 5 "Majorroadsprefer" 6 "TollRoadsaviod" 7 "TollRoadsprefer" 8 "Ferriesavoid" 9 "Ferriesprefer" ;
VAL_ 721 VRM_BTDefaultPhone_St 0 "Invalid" 1 "PhoneIndex1" 2 "PhoneIndex2" 3 "PhoneIndex3" 4 "PhoneIndex4" 5 "PhoneIndex5" 6 "PhoneIndex6" 7 "CradlePhone" 8 "NoPhone" ;
VAL_ 721 VRM_DetourUnit_st 0 "Invalid" 1 "Miles" 2 "Kilometer" 3 "Nounitdefined" ;
VAL_ 721 VRM_Zoom_Option_St 0 "Invalid" 1 "AbsoluteValue" 2 "InrelativeValue" 3 "OutrelativeValue" ;
VAL_ 721 VRM_ComBTDTMFTone_St 14 "Dtmfplus" 0 "Invalid" 1 "CommandNotIssued" 2 "Dtmf0" 3 "Dtmf1" 4 "Dtmf2" 5 "Dtmf3" 6 "Dtmf4" 7 "Dtmf5" 8 "Dtmf6" 9 "Dtmf7" 10 "Dtmf8" 11 "Dtmf9" 12 "Dtmfstar" 13 "Dtmfcross" ;
VAL_ 721 VRM_SuggestedRoute_St 0 "Invalid" 1 "CommandNotIssued" 2 "Accept" 3 "Reject" ;
VAL_ 721 VRM_ComDelWaypoint_St 0 "Invalid" 1 "CommandNotIssued" 2 "DeleteNextWayptDestination" ;
VAL_ 721 VRM_ComSelectDisc_St 0 "Invalid" 1 "CommandNotIssued" 2 "Disc1" 3 "Disc2" 4 "Disc3" 5 "Disc4" 6 "Disc5" 7 "Disc6" ;
VAL_ 721 VRM_ComTelService_St 0 "Invalid" 1 "CommandNotIssued" 2 "InformationCall" 3 "TelephonyCall" 4 "RedialLastIncoming" ;
VAL_ 721 VRM_ComDestHome_St 0 "Invalid" 1 "CommandNotIssued" 2 "SetDestinationHome" ;
VAL_ 721 VRM_ComShowNavInfo_St 0 "Invalid" 1 "CommandNotIssued" 2 "CurrentPos" 3 "Destination" 4 "CompleteRoute" 5 "NorthDirectionToTop" 6 "CarDirectionToTop" 7 "TurnList" ;
VAL_ 721 VRM_VoiceRecStatus_St 0 "Invalid" 1 "Idle" 2 "Listening" 3 "Reserved" 4 "CommandNotAllowed" ;
VAL_ 721 VRM_ComSelTrackSource_St 0 "Invalid" 1 "CommandNotIssued" 2 "Cd" 3 "CdChanger" ;
VAL_ 721 VRM_ComDetour_St 0 "Invalid" 1 "CommandNotIssued" 2 "Detour1" 3 "Detour2" 4 "Detour3" 5 "Detour4" 6 "Detour5" 7 "Detour10" 8 "Detour15" 9 "Detour20" 10 "Detour25" 11 "Detour50" 12 "Detour100" ;
VAL_ 721 VRM_ComDisplay_St 0 "Invalid" 1 "CommandNotIssued" 2 "DisplayOn" 3 "DisplayOff" 4 "Day" 5 "Night" 6 "Auto" 7 "Twilight" ;
VAL_ 721 VRM_ComDynamicGuidande_St 0 "Invalid" 1 "CommandNotIssued" 2 "On" 3 "Off" ;
VAL_ 721 VRM_ComZoom_St 0 "Invalid" 1 "CommandNotIssued" 2 "Level1" 3 "Level2" 4 "Level3" 5 "Level4" 6 "Level5" 7 "Level6" 8 "Level7" 9 "Level8" 10 "Level9" 11 "Level10" 12 "Level11" 13 "Level12" 14 "Level13" ;
VAL_ 721 VRM_ComCallControl_St 0 "Invalid" 1 "CommandNotIssued" 2 "Pickup" 3 "Reject" 4 "EndOngoingCall" ;
VAL_ 721 VRM_ComGuidance_St 0 "Invalid" 1 "CommandNotIssued" 2 "VoiceGuidanceOn" 3 "VoiceGuidanceOff" 4 "CancelGuidance" 5 "RepeatLastVoiceGuidance" ;
VAL_ 721 VRM_ComTrafficInfDsp_St 0 "Invalid" 1 "CommandNotIssued" 2 "ShowTrafficInfoOnDisplay" 3 "HideTrafficInfoOnDisplay" ;
VAL_ 720 VRM_PhMicrophoneMute_St 3 "Reserved" 2 "MicrophoneIsUnmuted" 1 "MicrophoneIsMuted" 0 "Invalid" ;
VAL_ 720 Aioc_ExtSrcOutpMode_St 8 "NotAllocated" 4 "AllocatedBtAudio" 3 "AllocatedBtNavigation" 2 "AllocatedBtPhone" 1 "AllocatedVr" 0 "Invalid" 7 "AllocatedAUX3" 6 "AllocatediPod" 5 "AllocatedUSB" ;
VAL_ 720 VRM_BTPhoneSts_St 16 "Connected_Call_on_hold" 15 "Conference_OtherCallOnHold" 0 "Invalid" 1 "Idle" 2 "Dialing" 3 "Connected" 4 "CradlephNotReady" 5 "NumUnobtainable" 6 "IncomCall" 7 "NoLinkToBt" 8 "InitBtCon" 9 "PhoneBusy" 10 "PhoneVr" 11 "NotSupported" 12 "BtPhPriv" 13 "ConfCall" 14 "Conference_2ndIncCall" ;
VAL_ 720 VRM_SubscribeStatus_St 0 "Invalid" 1 "OnSubscribingInfo" 2 "OffNotSubscribingInfo" ;
VAL_ 720 VRM_BlutoothStatus_St 0 "Invalid" 1 "On" 2 "Off" ;
VAL_ 720 VRM_BondRequest_St 0 "Invalid" 1 "BondRequestExist" 2 "NoBondRequestExist" ;
VAL_ 720 VRM_VRMMonoOutMode_St 0 "Invalid" 1 "AllocatedVr" 2 "AllocatedBt" 3 "NotAllocated" ;
VAL_ 720 VRM_BTNetworkStatus_St 0 "Invalid" 1 "NoNetwork" 2 "InNetwork" 3 "Roaming" 4 "NoLinkToBtPhone" 5 "NotSupportedByBtPhone" ;
VAL_ 720 VRM_BTSignalStrength_St 0 "Invalid" 1 "SignalStrength0" 2 "SignalStrength1" 3 "SignalStrength2" 4 "SignalStrength3" 5 "SignalStrength4" 6 "SignalStrength5" 7 "NoLinkToBtPhone" 8 "NotSupportedByBtPhone" ;
VAL_ 720 VRM_BTBatteryLevel_St 0 "Invalid" 1 "Level0" 2 "Level1" 3 "Level2" 4 "Level3" 5 "Level4" 6 "Level5" 7 "NoLinkToBtPhone" 8 "NotSupportedByBtPhone" ;
VAL_ 470 VRM_BTIncomingCall_Rsp 0 "Inactive" 1 "Accepted" 2 "Declined" 3 "Failed" ;
VAL_ 470 VRM_BTEndTelService_Rsp 3 "Error" 0 "Inactive" 1 "IntermediateResult" 2 "FinalResult" ;
VAL_ 758 SDARS_OpMode_St 7 "FastRewindSpeed2" 6 "FastRewindSpeed1" 5 "FastForwardSpeed2" 4 "FastForwardSpeed1" 3 "Pause" 2 "Play" 1 "Stop" 0 "Invalid" ;
VAL_ 758 SDARS_Factory_Reset_St 1 "FactorySettingsRestored" 0 "Invalid" ;
VAL_ 760 SDARS_Alert_Status 0 "Invalid" 2 "Disabled" 1 "Enabled" ;
VAL_ 760 SDARS_Channel_Lock 0 "Invalid" 2 "Unlocked" 1 "Locked" ;
VAL_ 523 WaterInFuel_B_Falt_UB 1 "Fresh_data" 0 "Unchanged_data" ;
VAL_ 523 WaterInFuel_B_Falt 1 "Fault" 0 "No_Fault" ;
VAL_ 523 UreaMxAdd_L2_Actl_UB 1 "Fresh_data" 0 "Unchanged_data" ;
VAL_ 523 VehUreaRnge3_L_DsplyMx_UB 1 "Fresh_data" 0 "Unchanged_data" ;
VAL_ 523 UreaMnAdd_L2_Actl_UB 1 "Fresh_data" 0 "Unchanged_data" ;
VAL_ 523 UreaMnAdd_L2_Actl 255 "Faulty" ;
VAL_ 523 UreaMxAdd_L2_Actl 511 "Faulty" ;
VAL_ 942 ApaOffOptnSel_B_Avail 1 "Available" 0 "NotAvailable" ;
VAL_ 942 PrkBrkElRleas_B_RqApa 1 "Yes" 0 "No" ;
VAL_ 942 ApaDrvRq2MsgTxt_D_Rq 15 "NotUsed_7" 14 "NotUsed_6" 13 "NotUsed_5" 12 "NotUsed_4" 11 "NotUsed_3" 10 "NotUsed_2" 9 "NotUsed_1" 8 "CloseDoor" 7 "TakeControl" 6 "ReleaseEpb" 5 "ReleaseSteering" 4 "ReleaseBrake" 3 "DriveBackward" 2 "DriveForward" 1 "Stop" 0 "NoRequest" ;
VAL_ 942 ApaDrvRq1MsgTxt_D_Rq 7 "NotUsed" 6 "ExitVehicle" 5 "PressApaButton" 4 "ShiftToP" 3 "ShiftToN" 2 "ShiftToD" 1 "ShiftToR" 0 "NoRequest" ;
VAL_ 942 ApaSys_D2_Stat 15 "NotUsed_5" 14 "NotUsed_4" 13 "NotUsed_3" 12 "NotUsed_2" 11 "NotUsed_1" 10 "NoSideSelectable" 9 "RightSideSelectable" 8 "LeftSideSelectable" 7 "BothSidesSelectable" 6 "Faulty" 5 "Finished" 4 "Cancelled" 3 "NotAvailable" 2 "Overspeed" 1 "Pause" 0 "NormalOperation" ;
VAL_ 942 ApaSlotTrgt_D_Stat 15 "NotUsed_7" 14 "NotUsed_6" 13 "NotUsed_5" 12 "NotUsed_4" 11 "NotUsed_3" 10 "NotUsed_2" 9 "NotUsed_1" 8 "Front" 7 "Rear" 6 "Right3" 5 "Right2" 4 "Right1" 3 "Left3" 2 "Left2" 1 "Left1" 0 "None" ;
VAL_ 942 ApaSlotOption_B_Avail 1 "Available" 0 "NotAvailable" ;
VAL_ 942 ApaSlotAlrtSet_B_Stat 1 "Enable" 0 "Disable" ;
VAL_ 942 ApaSlotAlrt_B_Rq 1 "True" 0 "False" ;
VAL_ 942 ApaRmtFeatSel_B_Avail 1 "Available" 0 "NotAvailable" ;
VAL_ 942 ApaParkOutSel_B_Avail 1 "Available" 0 "NotAvailable" ;
VAL_ 942 ApaParkInSel_B_Avail 1 "Available" 0 "NotAvailable" ;
VAL_ 942 ApaMsgTxt_D2_Stat 15 "ReducedFunction" 14 "TrailerFeatureNotAvailable" 13 "AcceleratorPedalInactive" 12 "SensorsBlocked" 11 "TrailerAttached" 10 "TcsDeactivated" 9 "WheelSlip" 8 "HighInclination" 7 "DoorOpen" 6 "SteeringInteraction" 5 "WrongDirection" 4 "SpeedLimitExceeded" 3 "BrakeEvent" 2 "ObstacleInPath" 1 "WaitForSteering" 0 "None" ;
VAL_ 942 ApaDynmcSlot_B_Stat 1 "On" 0 "Off" ;
VAL_ 942 ApaDisplayMode_D_Stat 3 "NotUsed" 2 "FullScreen" 1 "Menu" 0 "Off" ;
VAL_ 942 ApaControlMode_D_Stat 1 "Active" 0 "Inactive" ;
VAL_ 942 PrkAidAcsyRear_D_Stat 3 "NotUsed" 2 "On" 1 "Off" 0 "Null" ;
VAL_ 942 PrkAidAcsyFront_D_Stat 3 "NotUsed" 2 "On" 1 "Off" 0 "Null" ;
VAL_ 942 PrkAidDrvDir_D_Stat 7 "NotUsed_2" 6 "NotUsed_1" 5 "BackwardNegative" 4 "ForwardNegative" 3 "BackwardPositive" 2 "ForwardPositive" 1 "NoMotion" 0 "DirectionNotKnown" ;
VAL_ 634 EngAirFiltMsgTxt_D_Rq_UB 1 "Fresh_data" 0 "Unchanged_data" ;
VAL_ 634 EngAirFiltMsgTxt_D_Rq 7 "NotUsed_2" 6 "NotUsed_1" 5 "EngineAirFilterMonitorFalt" 4 "ResetComplete" 3 "Clogged" 2 "ReplaceNow" 1 "ReplaceSoon" 0 "NoMessage" ;
VAL_ 634 AutoHoldSwMde_B_Ind_UB 1 "Fresh_data" 0 "Unchanged_data" ;
VAL_ 634 AutoHoldSwMde_B_Ind 1 "On" 0 "Off" ;
VAL_ 634 Ccd_B_Falt_UB 1 "Fresh_data" 0 "Unchanged_data" ;
VAL_ 634 Ccd_B_Falt 1 "Yes" 0 "No" ;
VAL_ 634 RearDiffLckLamp_D_Rq3_UB 1 "Fresh_data" 0 "Unchanged_data" ;
VAL_ 634 AwdLckLamp_D_Rq_UB 1 "Fresh_data" 0 "Unchanged_data" ;
VAL_ 634 RearDiffLckLamp_D_Rq3 3 "Triggered" 2 "Flash" 1 "On" 0 "Off" ;
VAL_ 634 AwdLckLamp_D_Rq 3 "Triggered" 2 "Flash" 1 "On" 0 "Off" ;
VAL_ 634 AutoTowAllw_D_StatMnu_UB 1 "Fresh_data" 0 "Unchanged_data" ;
VAL_ 634 AutoTowAllw_D_StatMnu 3 "TowHaulCommandedOn" 2 "AutoTowHaulEnabled" 1 "AutoTowHaulDisabled" 0 "NoSelection" ;
VAL_ 634 AutoTowActv_B_Stat 1 "Yes" 0 "No" ;
VAL_ 634 AutoTowActv_B_Stat_UB 1 "Fresh_data" 0 "Unchanged_data" ;
VAL_ 634 LdwChime_B_Rq_UB 1 "Fresh_data" 0 "Unchanged_data" ;
VAL_ 634 HdcOn_B_Ind 1 "On" 0 "Off" ;
VAL_ 634 HdcOn_B_Ind_UB 1 "Fresh_data" 0 "Unchanged_data" ;
VAL_ 634 SuspVLimMsgTxt_B_Rq_UB 1 "Fresh_data" 0 "Unchanged_data" ;
VAL_ 634 SuspVlimMsgTxt_B_Rq 1 "Yes" 0 "No" ;
VAL_ 634 EngExhMdeQuiet_D2_Stat_UB 1 "Fresh_data" 0 "Unchanged_data" ;
VAL_ 634 EngExhMdeQuiet_D2_Stat 7 "Faulty" 6 "NotUsed_2" 5 "NotUsed_1" 4 "Track" 3 "Sport" 2 "Normal" 1 "Stealth" 0 "Null" ;
VAL_ 634 ChrgCrdLck_D_Falt_UB 1 "Fresh_data" 0 "Unchanged_data" ;
VAL_ 634 LdwChime_B_Rq 1 "On" 0 "Off" ;
VAL_ 634 ChrgCrdLck_D_Falt 3 "NotUsed" 2 "HardwareFault" 1 "CsiFault" 0 "NoFault" ;
VAL_ 1088 HvacPrecondRecirc_D_Rq 3 "Last_User_Setting" 2 "Auto" 1 "Recirc" 0 "Outside" ;
VAL_ 1088 HvacPrecondMode2_D_Rq 15 "NotUsed4" 14 "NotUsed3" 13 "NotUsed2" 12 "NotUsed1" 11 "Last_User_Settings" 10 "Auto" 9 "Max_Defrost" 8 "Windshield_Panel_Floor" 7 "Windshield_Panel" 6 "Windshield" 5 "Windshield_Floor" 4 "Floor" 3 "Panel_Floor" 2 "Panel" 1 "MAX_AC" 0 "Off" ;
VAL_ 1088 HvacPrecondBlwr2_D_Rq 15 "NotUsed6" 14 "NotUsed5" 13 "NotUsed4" 12 "NotUsed3" 11 "NotUsed2" 10 "NotUsed1" 9 "Last_User_Setting" 8 "Auto" 7 "Speed7" 6 "Speed6" 5 "Speed5" 4 "Speed4" 3 "Speed3" 2 "Speed2" 1 "Speed1" 0 "Off" ;
VAL_ 1088 HvacPrecondAC_D_Rq 3 "Last_User_Setting" 2 "Auto" 1 "On" 0 "Off" ;
VAL_ 1088 BattChrgInhbt_D_Rq 3 "MaintainTargetSoc" 2 "NotUsed" 1 "InhibitChargingThermal" 0 "Enable_Charging" ;
VAL_ 1088 ChrgStat_D2_Dsply 15 "ChargeStopCommanded" 14 "ChargeStartCommanded" 13 "ChargeTargetReached" 12 "DriveConditioning" 11 "CabinPreconditioning" 10 "ChargingSystemMaintain" 9 "ChargingInductive" 8 "ChargingDCFastCharge" 7 "ChargingAC" 6 "ChargeScheduled" 5 "EvsePaused" 4 "EvseNotDetected" 3 "EvseNotCompatible" 2 "FaultOutsideCar" 1 "FaultInsideCar" 0 "NotReady" ;
VAL_ 1088 ChrgTMatch_B_Stat 1 "True" 0 "False" ;
VAL_ 1088 BattDcChrgRms_I_Lim 32767 "Faulty" 32766 "NoDataExists" ;
VAL_ 761 SDARS_Seek_Scan_St 1 "NoChannelsAvailable" 0 "Invalid" ;
VAL_ 761 SDARS_Invalid_Chan_St 0 "Invalid" 2 "Active" 1 "Inactive" ;
VAL_ 761 SDARS_UnSubscrb_Chan_St 0 "Invalid" 2 "Active" 1 "Inactive" ;
VAL_ 761 SDARS_Loss_Ant_St 0 "Invalid" 2 "Active" 1 "Inactive" ;
VAL_ 761 SDARS_UnSubscrb_St 0 "Invalid" 2 "Active" 1 "Inactive" ;
VAL_ 761 SDARS_Subscription_St 0 "Invalid" 2 "Active" 1 "Inactive" ;
VAL_ 761 SDARS_GCI_Update_St 0 "Invalid" 2 "Active" 1 "Inactive" ;
VAL_ 761 SDARS_Firmware_Updat_St 0 "Invalid" 2 "Active" 1 "Inactive" ;
VAL_ 761 SDARS_Antenna_Err_St 0 "Invalid" 2 "Active" 1 "Inactive" ;
VAL_ 761 SDARS_Receive_Err_St 0 "Invalid" 2 "Active" 1 "Inactive" ;
VAL_ 761 SDARS_Error_Conf_St 0 "Invalid" 2 "SDARS_OFF" 1 "SDARS_ON" ;
VAL_ 750 LoclFuelEffUnit_D_Stat 3 "MetrickmL" 2 "MetricL100km" 1 "Imperial" 0 "Null" ;
VAL_ 750 RoadsideAsstAvail_D_St 3 "AvailableFord" 2 "AvailableLincoln" 1 "NotAvailable" 0 "Null" ;
VAL_ 750 EmbedNavActive_D_Stat 3 "NotUsed" 2 "Active" 1 "Inactive" 0 "Null" ;
VAL_ 750 UnitOfLength_St 3 "miles_yards" 2 "miles_feets" 1 "kilometers_meters" 0 "Invalid" ;
VAL_ 750 RouteActive_St 1 "Active" 0 "Inactive" ;
VAL_ 750 CancelCurrWaypt_St 1 "Cancelled" 0 "Inactive" ;
VAL_ 750 Nav_RemainTTDestDays_St 14 "Exceeding13days" ;
VAL_ 750 WaypointsActive_St 3 "Max_Waypoints_Active" 2 "Waypoints_Active" 1 "Waypoints_Inactive" 0 "Invalid" ;
VAL_ 750 Nav_DistanToDestUnit_St 3 "Yards_yd" 2 "Miles_mi" 1 "Meters_m" 0 "Kilometers_km" ;
VAL_ 750 NavError_Waypoint_St 2 "Navigation_Fault" 1 "No_Error" 0 "Invalid" ;
VAL_ 725 InfotainmentAudio_St 3 "NotUsed" 2 "ErrorState_NoAudio" 1 "NormalOperation" 0 "Null" ;
VAL_ 725 ACU_CompLogic_St 0 "Invalid" 1 "Off" 2 "On" ;
VAL_ 725 ACU_RadioError_St 0 "Invalid" 1 "NoError" 2 "PiNotFound" 3 "PtyNotFound" ;
VAL_ 725 ACU_HardwareError_St 0 "Invalid" 1 "NoError" 2 "EepromReadError" 3 "KeycodeLocked" 4 "KeycodeLockedForever" 5 "CommunicationError" 6 "OverTemperature" 7 "FocusError" ;
VAL_ 725 ACU_CurrentRadioBand_St 6 "Fm3" 0 "Invalid" 1 "Fm1" 2 "Fm2" 3 "FmAst" 4 "Am" 5 "AmAst" ;
VAL_ 725 ACU_AFMode_St 0 "Invalid" 1 "AfOn" 2 "AfOff" 3 "Auto" ;
VAL_ 1074 TrlrTireDual_D_Stat_UB 1 "Fresh_data" 0 "Unchanged_data" ;
VAL_ 1074 TrlrTireDual_D_Stat 15 "NotUsed_11" 14 "NotUsed_10" 13 "NotUsed_9" 12 "NotUsed_8" 11 "NotUsed_7" 10 "NotUsed_6" 9 "NotUsed_5" 8 "NotUsed_4" 7 "NotUsed_3" 6 "NotUsed_2" 5 "NotUsed_1" 4 "NotSupported" 3 "Invalid" 2 "InnerTire" 1 "OuterTire" 0 "SystemUnknown" ;
VAL_ 1074 PwLftgtIntSw_B_Stat_UB 1 "Fresh_data" 0 "Unchanged_data" ;
VAL_ 1074 PwLftgtIntSw_B_Stat 1 "Pressed" 0 "Null" ;
VAL_ 1074 E_Frt_Btn_Status_1st_UB 1 "Fresh_data" 0 "Unchanged_data" ;
VAL_ 1074 E_Frt_Btn_Status_2nd_UB 1 "Fresh_data" 0 "Unchanged_data" ;
VAL_ 1074 E_Frt_Btn_Status_2nd 63 "NotUsed_10" 62 "NotUsed_9" 61 "NotUsed_8" 60 "NotUsed_7" 59 "NotUsed_6" 58 "NotUsed_5" 57 "NotUsed_4" 56 "NotUsed_3" 55 "NotUsed_2" 54 "NotUsed_1" 53 "RHS_Cld_Seat3_Pressed" 52 "RHS_Cld_Seat2_Pressed" 51 "RHS_Cld_Seat1_Pressed" 50 "LHS_Cld_Seat3_Pressed" 49 "LHS_Cld_Seat2_Pressed" 48 "LHS_Cld_Seat1_Pressed" 47 "RHS_Auto_Seat_Pressed" 46 "RHS_Htd_Seat3_Pressed" 45 "RHS_Htd_Seat2_Pressed" 44 "RHS_Htd_Seat1_Pressed" 43 "RHS_Seat_Off_Pressed" 42 "LHS_Auto_Seat_Pressed" 41 "LHS_Htd_Seat3_Pressed" 40 "LHS_Htd_Seat2_Pressed" 39 "LHS_Htd_Seat1_Pressed" 38 "LHS_Seat_Off_Pressed" 37 "DrvrFcsdMde_Pressed" 36 "MdeMnu_Pressed" 35 "AAR_Pressed" 34 "Heat_Pressed" 33 "RearMnu_Pressed" 32 "FrontMnu_Pressed" 31 "Defrost_Pressed" 30 "Htg_Strg_Whl_Pressed" 29 "RHS_Cld_Seat_Pressed" 28 "LHS_Cld_Seat_Pressed" 27 "RHS_Htd_Seat_Pressed" 26 "LHS_Htd_Seat_Pressed" 25 "Max_Defrost_Pressed" 24 "My_Temp_Pressed" 23 "Front_Power_Pressed" 22 "Rear_Defrost_Pressed" 21 "Pnl_Flr_Ws_Pressed" 20 "Pnl_Ws_Pressed" 19 "Windscreen_Pressed" 18 "Htd_Frt_Wsh_Pressed" 17 "Auto_Recirc_Pressed" 16 "Outside_Pressed" 15 "Recirc_Pressed" 14 "Max_AC_Pressed" 13 "Auto_Pressed" 12 "Blwr_Dec_Pressed" 11 "Blwr_Inc_Pressed" 10 "RHS_Temp_Dec_Pressed" 9 "RHS_Temp_Inc_Pressed" 8 "LHS_Temp_Dec_Pressed" 7 "LHS_Temp_Inc_Pressed" 6 "Dual_Pressed" 5 "AC_Pressed" 4 "Floor_Ws_Pressed" 3 "Floor_Pressed" 2 "Panel_Floor_Pressed" 1 "Panel_Pressed" 0 "None_Pressed" ;
VAL_ 1074 E_Frt_Btn_Status_1st 63 "NotUsed_10" 62 "NotUsed_9" 61 "NotUsed_8" 60 "NotUsed_7" 59 "NotUsed_6" 58 "NotUsed_5" 57 "NotUsed_4" 56 "NotUsed_3" 55 "NotUsed_2" 54 "NotUsed_1" 53 "RHS_Cld_Seat3_Pressed" 52 "RHS_Cld_Seat2_Pressed" 51 "RHS_Cld_Seat1_Pressed" 50 "LHS_Cld_Seat3_Pressed" 49 "LHS_Cld_Seat2_Pressed" 48 "LHS_Cld_Seat1_Pressed" 47 "RHS_Auto_Seat_Pressed" 46 "RHS_Htd_Seat3_Pressed" 45 "RHS_Htd_Seat2_Pressed" 44 "RHS_Htd_Seat1_Pressed" 43 "RHS_Seat_Off_Pressed" 42 "LHS_Auto_Seat_Pressed" 41 "LHS_Htd_Seat3_Pressed" 40 "LHS_Htd_Seat2_Pressed" 39 "LHS_Htd_Seat1_Pressed" 38 "LHS_Seat_Off_Pressed" 37 "DrvrFcsdMde_Pressed" 36 "MdeMnu_Pressed" 35 "AAR_Pressed" 34 "Heat_Pressed" 33 "RearMnu_Pressed" 32 "FrontMnu_Pressed" 31 "Defrost_Pressed" 30 "Htg_Strg_Whl_Pressed" 29 "RHS_Cld_Seat_Pressed" 28 "LHS_Cld_Seat_Pressed" 27 "RHS_Htd_Seat_Pressed" 26 "LHS_Htd_Seat_Pressed" 25 "Max_Defrost_Pressed" 24 "My_Temp_Pressed" 23 "Front_Power_Pressed" 22 "Rear_Defrost_Pressed" 21 "Pnl_Flr_Ws_Pressed" 20 "Pnl_Ws_Pressed" 19 "Windscreen_Pressed" 18 "Htd_Frt_Wsh_Pressed" 17 "Auto_Recirc_Pressed" 16 "Outside_Pressed" 15 "Recirc_Pressed" 14 "Max_AC_Pressed" 13 "Auto_Pressed" 12 "Blwr_Dec_Pressed" 11 "Blwr_Inc_Pressed" 10 "RHS_Temp_Dec_Pressed" 9 "RHS_Temp_Inc_Pressed" 8 "LHS_Temp_Dec_Pressed" 7 "LHS_Temp_Inc_Pressed" 6 "Dual_Pressed" 5 "AC_Pressed" 4 "Floor_Ws_Pressed" 3 "Floor_Pressed" 2 "Panel_Floor_Pressed" 1 "Panel_Pressed" 0 "None_Pressed" ;
VAL_ 1074 DrLatchRrMsgTxt_D_Rq_UB 1 "Fresh_data" 0 "Unchanged_data" ;
VAL_ 1074 DrLatchRrMsgTxt_D_Rq 7 "Message7" 6 "Message6" 5 "Message5" 4 "Message4" 3 "Message3" 2 "Message2" 1 "Message1" 0 "NoMessage" ;
VAL_ 1074 DrLatchRlMsgTxt_D_Rq_UB 1 "Fresh_data" 0 "Unchanged_data" ;
VAL_ 1074 DrLatchRlMsgTxt_D_Rq 7 "Message7" 6 "Message6" 5 "Message5" 4 "Message4" 3 "Message3" 2 "Message2" 1 "Message1" 0 "NoMessage" ;
VAL_ 1074 DrLatchFrMsgTxt_D_Rq_UB 1 "Fresh_data" 0 "Unchanged_data" ;
VAL_ 1074 DrLatchFrMsgTxt_D_Rq 7 "Message7" 6 "Message6" 5 "Message5" 4 "Message4" 3 "Message3" 2 "Message2" 1 "Message1" 0 "NoMessage" ;
VAL_ 1074 DrLatchFlMsgTxt_D_Rq_UB 1 "Fresh_data" 0 "Unchanged_data" ;
VAL_ 1074 DrLatchFlMsgTxt_D_Rq 7 "Message7" 6 "Message6" 5 "Message5" 4 "Message4" 3 "Message3" 2 "Message2" 1 "Message1" 0 "NoMessage" ;
VAL_ 1074 TrlrTireThresh_D_Stat_UB 1 "Fresh_data" 0 "Unchanged_data" ;
VAL_ 1074 TrlrTireSys_D_Stat_UB 1 "Fresh_data" 0 "Unchanged_data" ;
VAL_ 1074 TrlrTireSys_D_Stat 15 "NotUsed" 14 "TiresNotTrained" 13 "TrainingComplete" 12 "TrainLMTire" 11 "TrainLRTire" 10 "TrainRMTire" 9 "TrainRRTire" 8 "TrainRFTire" 7 "TrainLFTire" 6 "RequestPressureThresh" 5 "RequestTireCount" 4 "SystemActive" 3 "TireLow" 2 "SensorFault" 1 "System Fault" 0 "SystemUnknown" ;
VAL_ 1074 TrlrTireCnt_D_Stat_UB 1 "Fresh_data" 0 "Unchanged_data" ;
VAL_ 1074 TrlrTireCnt_D_Stat 7 "Faulty" 6 "TwelveTire" 5 "EightTire" 4 "FourTireOneAxle" 3 "SixTire" 2 "FourTire" 1 "TwoTire" 0 "Unconfigured" ;
VAL_ 1074 BrkMdeInhbt_B_RqDsply_UB 1 "Fresh_data" 0 "Unchanged_data" ;
VAL_ 1074 BrkMdeInhbt_B_RqDsply 1 "Yes" 0 "No" ;
VAL_ 1014 WrlssAcsyChrg_Pc_Actl 127 "Faulty" 126 "NoDataExists" ;
VAL_ 1014 WrlssAcsyChrgr_D_Stat 7 "NotUsed" 6 "Misalignment" 5 "Overheat" 4 "MetalObjectDetected" 3 "ChargingComplete" 2 "ChargingInProgress" 1 "ChargingNotInProgress" 0 "Null" ;
VAL_ 548 DSP_AHU_ChmTstTone_Rq 1 "Active" 0 "Inactive" ;
VAL_ 548 DSP_ChimeChanState_St 7 "Reserved4" 6 "Reserved3" 5 "Reserved2" 4 "Reserved" 3 "Busy" 2 "Ready" 1 "Muted" 0 "Invalid" ;
VAL_ 548 DSP_Chime2_Not_Recgnizd 0 "Inactive" 1 "Chime_Not_Recognized" ;
VAL_ 548 DSP_Chime_Not_Recgnizd 0 "Inactive" 1 "Chime_Not_Recognized" ;
VAL_ 548 DSP_Alert_Channel3 3 "Reserved" 2 "Muted" 1 "Initialized_for_Prompts" 0 "Inactive" ;
VAL_ 548 DSP_Alert_Channel2 3 "Initialized_for_chimes" 2 "Muted" 1 "Reserved" 0 "Inactive" ;
VAL_ 548 DSP_Alert_Channel1 3 "Initialized_for_chimes" 2 "Muted" 1 "Reserved" 0 "Inactive" ;
VAL_ 548 DSP_Chimes_Supported 3 "Not_Used" 2 "Not_Supported" 1 "Supported" 0 "Inactive" ;
VAL_ 548 DSP_AdjChimVolSupp_St 3 "NotUsed_1" 2 "Supported" 1 "NotSupported" 0 "Inactive" ;
VAL_ 548 DSP_AdjChimVolSupp2_St 3 "NotUsed_1" 2 "Supported" 1 "NotSupported" 0 "Inactive" ;
VAL_ 548 DSP_AHU_ChmTstT 31 "NotUsed_22" 30 "NotUsed_21" 29 "NotUsed_20" 28 "NotUsed_19" 27 "NotUsed_18" 26 "NotUsed_17" 25 "NotUsed_16" 24 "NotUsed_15" 23 "NotUsed_14" 22 "NotUsed_13" 21 "NotUsed_12" 20 "NotUsed_11" 19 "NotUsed_10" 18 "NotUsed_9" 17 "NotUsed_8" 16 "NotUsed_7" 15 "NotUsed_6" 14 "NotUsed_5" 13 "NotUsed_4" 12 "NotUsed_3" 11 "NotUsed_2" 10 "NotUsed_1" 9 "Crank_3" 8 "NotUsed" 7 "Running_2" 6 "IgnitionOn_2" 5 "PostIgnition_1" 4 "Accessory_1" 3 "PostAccessory_0" 2 "KeyApproved_0" 1 "KeyRecentlyOut" 0 "KeyOut" ;
VAL_ 548 DspDgtlChime_D_Stat 3 "NotUsed" 2 "Supported" 1 "NotSupported" 0 "Inactive" ;
VAL_ 404 Dsp_LangUpdate_Rsp 2 "Language_Not_Supported" 1 "Language_Updated" 0 "Inactive" ;
